VERSION "created by canmatrix"

NS_ :

BS_:

BU_: DiagTool_OBD1 DiwaNXT EBS IRCS MulticII NBM VCM ETS NODE_45 FCCU DICO SGW2 HV_BOX ADCU AEBS DTCO MBMS SGW TPMS ACU CAID2 ELC5_Fr ELC5_Rr PredictiveVirtualNode2 BPU_3 Servo_dir_Turolla PCM NODE_90 NODE_91 NODE_92 RSRRM FCU DSE_VirtualNode2 DSE_VirtualNode40 DSE_VirtualNode38 DSE_VirtualNode49 DSE_VirtualNode48 DSE_VirtualNode39 DSE_VirtualNode37 DSE_VirtualNode36 BSM_B8 BPU_2 DSE_VirtualNode35 DSE_VirtualNode34 RADAR_ACC DSE_VirtualNode33 DSE_VirtualNode41 NODE_BE DSE_VirtualNode32 DSE_VirtualNode4 BSM_C0 BPU_1 DSE_VirtualNode31 DSE_VirtualNode29 DSE_VirtualNode28 MCDS DSE_VirtualNode44 DSE_VirtualNode27 DSE_VirtualNode26 BSM_C8 ALM DSE_VirtualNode25 DSE_VirtualNode50 DSE_VirtualNode47 DSE_VirtualNode46 DSE_VirtualNode23 DSE_VirtualNode51 ScanTool DSE_VirtualNode22 DSE_VirtualNode21 AePTO DC_VirtualNode1 DSE_VirtualNode43 MCSL DSE_VirtualNode1 DSE_VirtualNode42 PredictiveVirtualNode3 DSE_VirtualNode20 DSE_VirtualNode19 DSE_VirtualNode18 DSE_VirtualNode17 DSE_VirtualNode16 DSE_VirtualNode15 NODE_F9 DiagTool DSE_VirtualNode14 DSE_VirtualNode13 DSE_VirtualNode12 DSE_VirtualNode11 DSE_VirtualNode10 DSE_VirtualNode9 DSE_VirtualNode8 DSE_VirtualNode7 DSE_VirtualNode6 Mirror DSE_VirtualNode5 SAS DC_VirtualNode2 PredictiveVirtualNode1 DSE_VirtualNode45 ELFA3 EM_PTO RM CANAIR SWI

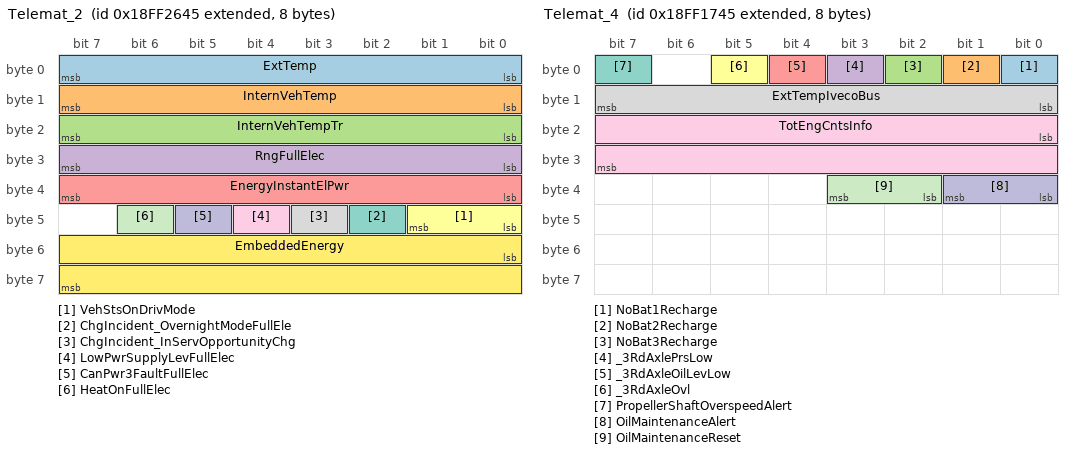
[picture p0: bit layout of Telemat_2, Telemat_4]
BO_ 2566858309 Telemat_2: 8 NODE_45
 SG_ ExtTemp : 0|8@1+ (1,-40) [-40|210] "°C"  PCM
 SG_ InternVehTemp : 8|8@1+ (1,-40) [-40|210] "°C"  PCM
 SG_ InternVehTempTr : 16|8@1+ (1,-40) [-40|210] "°C"  PCM
 SG_ RngFullElec : 24|8@1+ (2,0) [0|500] "km"  PCM
 SG_ EnergyInstantElPwr : 32|8@1+ (2,-250) [-250|250] "kw"  PCM
 SG_ VehStsOnDrivMode : 40|2@1+ (1,0) [0|3] ""  PCM
 SG_ ChgIncident_OvernightModeFullEle : 42|1@1+ (1,0) [0|1] ""  PCM
 SG_ ChgIncident_InServOpportunityChg : 43|1@1+ (1,0) [0|1] ""  PCM
 SG_ LowPwrSupplyLevFullElec : 44|1@1+ (1,0) [0|1] ""  PCM
 SG_ CanPwr3FaultFullElec : 45|1@1+ (1,0) [0|1] ""  PCM
 SG_ HeatOnFullElec : 46|1@1+ (1,0) [0|1] ""  PCM
 SG_ EmbeddedEnergy : 48|16@1+ (1,0) [0|385] "kwh"  PCM

BO_ 2566870597 Telemat_3: 8 NODE_45
 SG_ VehMode : 0|3@1+ (1,0) [0|7] ""  PCM
 SG_ HeatLiquidLowLev : 5|1@1+ (1,0) [0|1] ""  PCM
 SG_ HeatFuelLowLev : 6|1@1+ (1,0) [0|1] ""  PCM
 SG_ HeatSysHighTempFault : 7|1@1+ (1,0) [0|1] ""  PCM
 SG_ ParkBrkSwFullyApplied : 8|1@1+ (1,0) [0|1] ""  PCM
 SG_ FaeSts : 9|2@1+ (1,0) [0|3] ""  PCM
 SG_ FipoSts : 11|2@1+ (1,0) [0|3] ""  PCM
 SG_ EmerBtnSts : 13|1@1+ (1,0) [0|1] ""  PCM
 SG_ Door1EmerInh : 16|1@1+ (1,0) [0|1] ""  PCM
 SG_ Door2EmerInh : 17|1@1+ (1,0) [0|1] ""  PCM
 SG_ Door3EmerInh : 18|1@1+ (1,0) [0|1] ""  PCM
 SG_ Door4EmerInh : 19|1@1+ (1,0) [0|1] ""  PCM
 SG_ Door1ActvInEmerMode : 20|1@1+ (1,0) [0|1] ""  PCM
 SG_ Door2ActvInEmerMode : 21|1@1+ (1,0) [0|1] ""  PCM
 SG_ Door3ActvInEmerMode : 22|1@1+ (1,0) [0|1] ""  PCM
 SG_ Door4ActvInEmerMode : 23|1@1+ (1,0) [0|1] ""  PCM
 SG_ LastDoor1CmdCode : 24|8@1+ (1,0) [0|250] ""  PCM
 SG_ LastDoor2CmdCode : 32|8@1+ (1,0) [0|250] ""  PCM
 SG_ LastDoor3CmdCode : 40|8@1+ (1,0) [0|250] ""  PCM
 SG_ LastDoor4CmdCode : 48|8@1+ (1,0) [0|250] ""  PCM
 SG_ AirDryerSts : 56|1@1+ (1,0) [0|1] ""  PCM
 SG_ OverheatingComprElec : 57|1@1+ (1,0) [0|1] ""  PCM

BO_ 2566854469 Telemat_4: 8 NODE_45
 SG_ NoBat1Recharge : 0|1@1+ (1,0) [0|1] ""  PCM
 SG_ NoBat2Recharge : 1|1@1+ (1,0) [0|1] ""  PCM
 SG_ NoBat3Recharge : 2|1@1+ (1,0) [0|1] ""  PCM
 SG_ _3RdAxlePrsLow : 3|1@1+ (1,0) [0|1] ""  PCM
 SG_ _3RdAxleOilLevLow : 4|1@1+ (1,0) [0|1] ""  PCM
 SG_ _3RdAxleOvl : 5|1@1+ (1,0) [0|1] ""  PCM
 SG_ PropellerShaftOverspeedAlert : 7|1@1+ (1,0) [0|1] ""  PCM
 SG_ ExtTempIvecoBus : 8|8@1+ (1,-40) [-40|210] "°C"  PCM
 SG_ TotEngCntsInfo : 16|16@1+ (100,0) [0|6553500] "Cycles"  PCM
 SG_ OilMaintenanceAlert : 32|2@1+ (1,0) [0|3] ""  PCM
 SG_ OilMaintenanceReset : 34|2@1+ (1,0) [0|3] ""  PCM

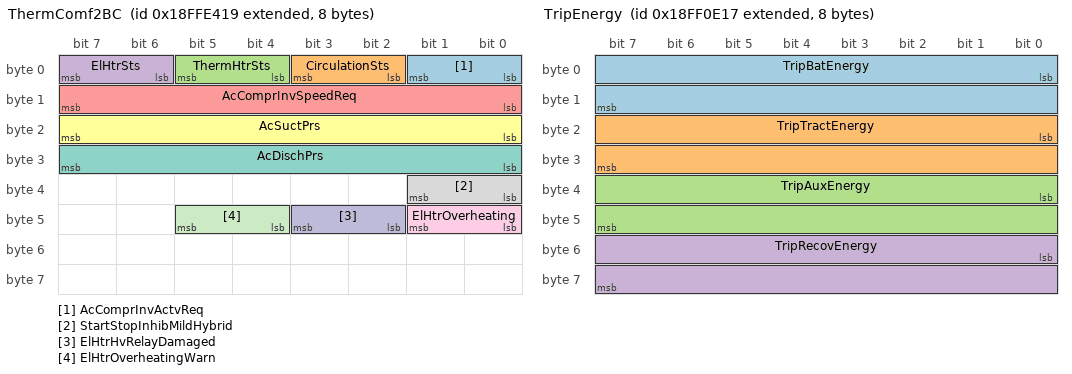
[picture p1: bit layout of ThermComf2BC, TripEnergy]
BO_ 2566906905 ThermComf2BC: 8 CANAIR
 SG_ AcComprInvActvReq : 0|2@1+ (1,0) [0|3] ""  PCM
 SG_ CirculationSts : 2|2@1+ (1,0) [0|3] ""  PCM
 SG_ ThermHtrSts : 4|2@1+ (1,0) [0|3] ""  PCM
 SG_ ElHtrSts : 6|2@1+ (1,0) [0|3] ""  PCM
 SG_ AcComprInvSpeedReq : 8|8@1+ (1,0) [0|250] "Hz"  PCM
 SG_ AcSuctPrs : 16|8@1+ (16,0) [0|4000] "kPa"  PCM
 SG_ AcDischPrs : 24|8@1+ (16,0) [0|4000] "kPa"  PCM
 SG_ StartStopInhibMildHybrid : 32|2@1+ (1,0) [0|3] ""  PCM
 SG_ ElHtrOverheating : 40|2@1+ (1,0) [0|3] ""  PCM
 SG_ ElHtrHvRelayDamaged : 42|2@1+ (1,0) [0|3] ""  PCM
 SG_ ElHtrOverheatingWarn : 44|2@1+ (1,0) [0|3] ""  PCM

BO_ 2566846467 TRF1: 8 DiwaNXT
 SG_ TransmOilTemp1 : 32|16@1+ (0.03125,-273) [-273|1734] "°C"  PCM

BO_ 2566852119 TripEnergy: 8 MulticII
 SG_ TripBatEnergy : 0|16@1+ (1,0) [0|65535] "kWh"  PCM
 SG_ TripTractEnergy : 16|16@1+ (1,0) [0|65535] "kWh"  PCM
 SG_ TripAuxEnergy : 32|16@1+ (1,0) [0|65535] "kWh"  PCM
 SG_ TripRecovEnergy : 48|16@1+ (1,0) [0|65535] "kWh"  PCM

BO_ 2566856261 TripEnergy2: 8 NODE_45
 SG_ TripAcEnergy : 0|16@1+ (1,0) [0|64255] "kWh"  PCM
 SG_ TripNet24VEnergy : 16|16@1+ (1,0) [0|64255] "kWh"  PCM

BO_ 2566749463 TTS: 8 MulticII
 SG_ TtBlkId M : 0|4@1+ (1,0) [0|15] ""  PCM
 SG_ CoolAc m0 : 4|3@1+ (1,0) [0|7] ""  PCM
 SG_ HighBeamMainBeam m0 : 8|3@1+ (1,0) [0|7] ""  PCM
 SG_ LowBeamDipBeam m0 : 12|3@1+ (1,0) [0|7] ""  PCM
 SG_ TurnSigs m0 : 16|3@1+ (1,0) [0|7] ""  PCM
 SG_ HazardWarn m0 : 20|3@1+ (1,0) [0|7] ""  PCM
 SG_ ProvDisOrHandiPers m0 : 24|3@1+ (1,0) [0|7] ""  PCM
 SG_ ParkBrk m0 : 28|3@1+ (1,0) [0|7] ""  PCM
 SG_ BrkFail_BrkSysMalf m0 : 32|3@1+ (1,0) [0|7] ""  PCM
 SG_ HatchOpen m0 : 36|3@1+ (1,0) [0|7] ""  PCM
 SG_ FuelLev m0 : 40|3@1+ (1,0) [0|7] ""  PCM
 SG_ EngCoolTemp_18FD7D17 m0 : 44|3@1+ (1,0) [0|7] ""  PCM
 SG_ BatChgCond m0 : 48|3@1+ (1,0) [0|7] ""  PCM
 SG_ EngOil m0 : 52|3@1+ (1,0) [0|7] ""  PCM
 SG_ PosLightSideLight m0 : 56|3@1+ (1,0) [0|7] ""  PCM
 SG_ FrontFogLight m0 : 60|3@1+ (1,0) [0|7] ""  PCM
 SG_ RearFogLight m1 : 4|3@1+ (1,0) [0|7] ""  PCM
 SG_ ParkHeat m1 : 8|3@1+ (1,0) [0|7] ""  PCM
 SG_ Eng_Mil m1 : 12|3@1+ (1,0) [0|7] ""  PCM
 SG_ ServCallForMaint m1 : 16|3@1+ (1,0) [0|7] ""  PCM
 SG_ TransmFluidTemp m1 : 20|3@1+ (1,0) [0|7] ""  PCM
 SG_ TransmFail_Malf m1 : 24|3@1+ (1,0) [0|7] ""  PCM
 SG_ AntiLckBrkSysFail m1 : 28|3@1+ (1,0) [0|7] ""  PCM
 SG_ WornBrkLin m1 : 32|3@1+ (1,0) [0|7] ""  PCM
 SG_ Windsh_WindshWasherFluid m1 : 36|3@1+ (1,0) [0|7] ""  PCM
 SG_ TireFail_Malf m1 : 40|3@1+ (1,0) [0|7] ""  PCM
 SG_ Malf_GenFail m1 : 44|3@1+ (1,0) [0|7] ""  PCM
 SG_ EngOilTemp m1 : 48|3@1+ (1,0) [0|7] ""  PCM
 SG_ EngOilLev m1 : 52|3@1+ (1,0) [0|7] ""  PCM
 SG_ EngCoolLev m1 : 56|3@1+ (1,0) [0|7] ""  PCM
 SG_ SteerFluidLev m1 : 60|3@1+ (1,0) [0|7] ""  PCM
 SG_ SteerFail m2 : 4|3@1+ (1,0) [0|7] ""  PCM
 SG_ HtCtrl m2 : 8|3@1+ (1,0) [0|7] ""  PCM
 SG_ Ret m2 : 12|3@1+ (1,0) [0|7] ""  PCM
 SG_ EngEmisSysFailMil m2 : 16|3@1+ (1,0) [0|7] ""  PCM
 SG_ EscInd m2 : 20|3@1+ (1,0) [0|7] ""  PCM
 SG_ BrkLight m2 : 24|3@1+ (1,0) [0|7] ""  PCM
 SG_ Artic m2 : 28|3@1+ (1,0) [0|7] ""  PCM
 SG_ StopReq m2 : 32|3@1+ (1,0) [0|7] ""  PCM
 SG_ PramReq m2 : 36|3@1+ (1,0) [0|7] ""  PCM
 SG_ BusStopBrk m2 : 40|3@1+ (1,0) [0|7] ""  PCM
 SG_ AdblueLev m2 : 44|3@1+ (1,0) [0|7] ""  PCM
 SG_ Raising m2 : 48|3@1+ (1,0) [0|7] ""  PCM
 SG_ Low m2 : 52|3@1+ (1,0) [0|7] ""  PCM
 SG_ Kneel m2 : 56|3@1+ (1,0) [0|7] ""  PCM
 SG_ EngCompTemp m2 : 60|3@1+ (1,0) [0|7] ""  PCM
 SG_ AuxAirPrs m3 : 4|3@1+ (1,0) [0|7] ""  PCM
 SG_ AirFiltClog m3 : 8|3@1+ (1,0) [0|7] ""  PCM
 SG_ FuelFiltDiffPrs m3 : 12|3@1+ (1,0) [0|7] ""  PCM
 SG_ SeatBelt m3 : 16|3@1+ (1,0) [0|7] ""  PCM
 SG_ Ebs m3 : 20|3@1+ (1,0) [0|7] ""  PCM
 SG_ LaneDepInd m3 : 24|3@1+ (1,0) [0|7] ""  PCM
 SG_ Aebs m3 : 28|3@1+ (1,0) [0|7] ""  PCM
 SG_ Acc m3 : 32|3@1+ (1,0) [0|7] ""  PCM
 SG_ TrailConn m3 : 36|3@1+ (1,0) [0|7] ""  PCM
 SG_ AbsTrail12 m3 : 40|3@1+ (1,0) [0|7] ""  PCM
 SG_ Airbag m3 : 44|3@1+ (1,0) [0|7] ""  PCM
 SG_ EbsTrail12 m3 : 48|3@1+ (1,0) [0|7] ""  PCM
 SG_ TcoInd m3 : 52|3@1+ (1,0) [0|7] ""  PCM
 SG_ EscSwdOff m3 : 56|3@1+ (1,0) [0|7] ""  PCM
 SG_ LdwSwdOff m3 : 60|3@1+ (1,0) [0|7] ""  PCM
 SG_ EngEmisFilt m4 : 4|3@1+ (1,0) [0|7] ""  PCM
 SG_ ElMotFails m4 : 8|3@1+ (1,0) [0|7] ""  PCM
 SG_ AdblueTamp m4 : 12|3@1+ (1,0) [0|7] ""  PCM
 SG_ MuxSys m4 : 16|3@1+ (1,0) [0|7] ""  PCM
 SG_ BatPak m4 : 20|3@1+ (1,0) [0|7] ""  PCM
 SG_ highVsysCaution m4 : 24|3@1+ (1,0) [0|7] ""  PCM
 SG_ BatPakTemp m4 : 28|3@1+ (1,0) [0|7] ""  PCM
 SG_ LimPerfElMot m4 : 32|3@1+ (1,0) [0|7] ""  PCM
 SG_ BatPakCool m4 : 36|3@1+ (1,0) [0|7] ""  PCM

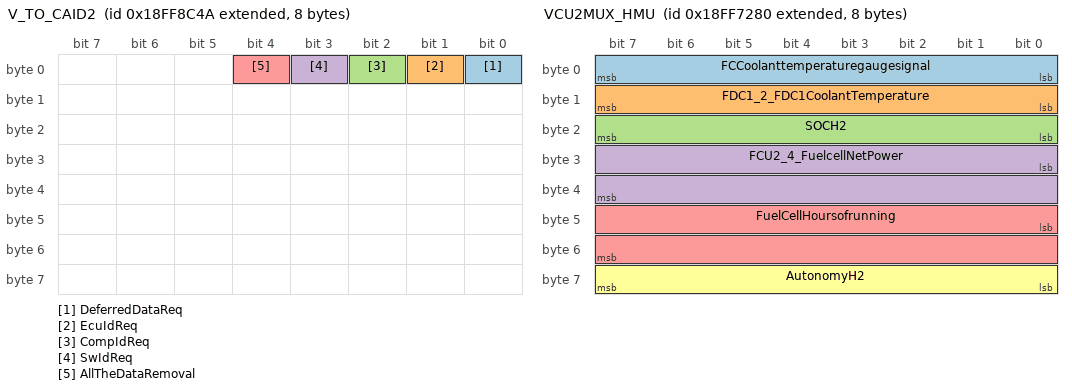
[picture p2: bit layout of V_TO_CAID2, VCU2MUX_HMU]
BO_ 2566884426 V_TO_CAID2: 8 PCM
 SG_ DeferredDataReq : 0|1@1+ (1,0) [0|1] "" Vector__XXX
 SG_ EcuIdReq : 1|1@1+ (1,0) [0|1] "" Vector__XXX
 SG_ CompIdReq : 2|1@1+ (1,0) [0|1] "" Vector__XXX
 SG_ SwIdReq : 3|1@1+ (1,0) [0|1] "" Vector__XXX
 SG_ AllTheDataRemoval : 4|1@1+ (1,0) [0|1] "" Vector__XXX

BO_ 2566877568 VCU2MUX_FC: 8 HV_BOX
 SG_ FCU2_8_H2LeakLamp : 1|2@1+ (1,0) [0|3] ""  PCM
 SG_ FCU2_5_H2FaultLamp : 3|1@1+ (1,0) [0|1] ""  PCM
 SG_ FCU2_HighvoltageInterlockReactRe : 4|1@1+ (1,0) [0|1] ""  PCM
 SG_ FCU2_H2TankValveEmergencyClose : 5|1@1+ (1,0) [0|1] ""  PCM
 SG_ FuelCellSwitchONOFFinputVCU : 6|1@1+ (1,0) [0|1] ""  PCM
 SG_ VCU_FuelcellCoolantLevelLow : 7|1@1+ (1,0) [0|1] ""  PCM
 SG_ FCU2_5_FuelcellStartup : 8|2@1+ (1,0) [0|3] ""  PCM
 SG_ FCU2_5_FuelcellLoadPermmit : 10|1@1+ (1,0) [0|1] ""  PCM
 SG_ FCU2_5_FuelcellShutdown : 11|2@1+ (1,0) [0|3] ""  PCM
 SG_ FCU2_5_FuelcellFault : 13|1@1+ (1,0) [0|1] ""  PCM
 SG_ FCU2_7_FuelcellStopImpossible : 14|2@1+ (1,0) [0|3] ""  PCM
 SG_ FCU2_7_FuelcellStopState : 16|2@1+ (1,0) [0|3] ""  PCM
 SG_ VCU_HighvoltageFaultEmergencyShu : 18|1@1+ (1,0) [0|1] ""  PCM
 SG_ VCU_TankCloseEmergencyShutdownRe : 19|1@1+ (1,0) [0|1] ""  PCM
 SG_ Fcactivationdeactivationstatusfo : 20|2@1+ (1,0) [0|3] ""  PCM
 SG_ H2ConctValExc3Pc_AwlR134 : 22|1@1+ (1,0) [0|1] ""  PCM
 SG_ H2ConctValExc4Pc_RsllR134 : 23|1@1+ (1,0) [0|1] ""  PCM
 SG_ H2sensor1leakagestatus : 24|1@1+ (1,0) [0|1] ""  PCM
 SG_ H2sensor2leakagestatus : 25|1@1+ (1,0) [0|1] ""  PCM
 SG_ H2sensor3leakagestatus : 26|1@1+ (1,0) [0|1] ""  PCM
 SG_ H2sensor4leakagestatus : 27|1@1+ (1,0) [0|1] ""  PCM
 SG_ FuelCellstatusfromSupervisorside : 28|4@1+ (1,0) [0|15] ""  PCM
 SG_ H2Circuitstatus : 32|4@1+ (1,0) [0|15] ""  PCM
 SG_ Limphomemodeoverridemodestatus : 36|1@1+ (1,0) [0|1] ""  PCM
 SG_ H2CircuitFautRSL : 37|1@1+ (1,0) [0|1] ""  PCM
 SG_ H2circuitFaultAWL : 38|1@1+ (1,0) [0|1] ""  PCM
 SG_ HVDCLinkStatus : 39|1@1+ (1,0) [0|1] ""  PCM
 SG_ FCModerequestbytheSupervisor : 40|4@1+ (1,0) [0|15] ""  PCM
 SG_ NumberoftanksopenforH2Readytopro : 44|3@1+ (1,0) [0|7] ""  PCM
 SG_ Fillingauthorizationduetosafetyr : 47|1@1+ (1,0) [0|1] ""  PCM
 SG_ FCU2_8_FuelcellConsumption : 48|16@1+ (0.01,0) [0|655] "mg"  PCM

BO_ 2566877824 VCU2MUX_HMU: 8 HV_BOX
 SG_ FCCoolanttemperaturegaugesignal : 0|8@1+ (1,0) [0|0] ""  PCM
 SG_ FDC1_2_FDC1CoolantTemperature : 8|8@1+ (1,0) [0|0] ""  PCM
 SG_ SOCH2 : 16|8@1+ (1,0) [0|0] ""  PCM
 SG_ FCU2_4_FuelcellNetPower : 24|16@1+ (1,0) [0|0] ""  PCM
 SG_ FuelCellHoursofrunning : 40|16@1+ (1,0) [0|0] ""  PCM
 SG_ AutonomyH2 : 56|8@1+ (1,0) [0|0] ""  PCM

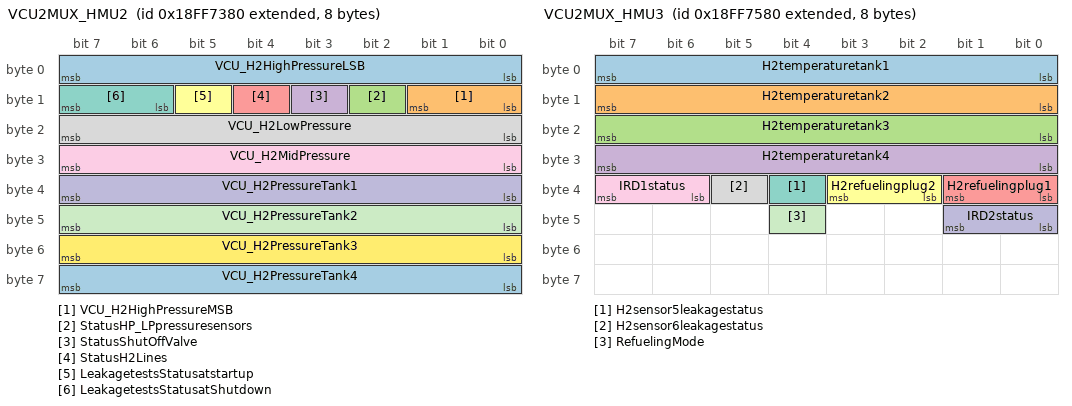
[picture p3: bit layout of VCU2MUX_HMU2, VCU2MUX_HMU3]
BO_ 2566878080 VCU2MUX_HMU2: 8 HV_BOX
 SG_ VCU_H2HighPressureLSB : 0|8@1+ (1,0) [0|0] ""  PCM
 SG_ VCU_H2HighPressureMSB : 8|2@1+ (1,0) [0|0] ""  PCM
 SG_ StatusHP_LPpressuresensors : 10|1@1+ (1,0) [0|0] ""  PCM
 SG_ StatusShutOffValve : 11|1@1+ (1,0) [0|0] ""  PCM
 SG_ StatusH2Lines : 12|1@1+ (1,0) [0|0] ""  PCM
 SG_ LeakagetestsStatusatstartup : 13|1@1+ (1,0) [0|0] ""  PCM
 SG_ LeakagetestsStatusatShutdown : 14|2@1+ (1,0) [0|0] ""  PCM
 SG_ VCU_H2LowPressure : 16|8@1+ (1,0) [0|0] ""  PCM
 SG_ VCU_H2MidPressure : 24|8@1+ (1,0) [0|0] ""  PCM
 SG_ VCU_H2PressureTank1 : 32|8@1+ (1,0) [0|0] ""  PCM
 SG_ VCU_H2PressureTank2 : 40|8@1+ (1,0) [0|0] ""  PCM
 SG_ VCU_H2PressureTank3 : 48|8@1+ (1,0) [0|0] ""  PCM
 SG_ VCU_H2PressureTank4 : 56|8@1+ (1,0) [0|0] ""  PCM

BO_ 2566878592 VCU2MUX_HMU3: 8 HV_BOX
 SG_ H2temperaturetank1 : 0|8@1+ (1,0) [0|0] ""  PCM
 SG_ H2temperaturetank2 : 8|8@1+ (1,0) [0|0] ""  PCM
 SG_ H2temperaturetank3 : 16|8@1+ (1,0) [0|0] ""  PCM
 SG_ H2temperaturetank4 : 24|8@1+ (1,0) [0|0] ""  PCM
 SG_ H2refuelingplug1 : 32|2@1+ (1,0) [0|0] ""  PCM
 SG_ H2refuelingplug2 : 34|2@1+ (1,0) [0|0] ""  PCM
 SG_ H2sensor5leakagestatus : 36|1@1+ (1,0) [0|0] ""  PCM
 SG_ H2sensor6leakagestatus : 37|1@1+ (1,0) [0|0] ""  PCM
 SG_ IRD1status : 38|2@1+ (1,0) [0|0] ""  PCM
 SG_ IRD2status : 40|2@1+ (1,0) [0|0] ""  PCM
 SG_ RefuelingMode : 44|1@1+ (1,0) [0|0] ""  PCM

BO_ 2566803211 VDC1: 8 EBS
 SG_ VdcInfoSig : 0|2@1+ (1,0) [0|3] ""  PCM
 SG_ VdcFullyOp : 2|2@1+ (1,0) [0|3] ""  PCM

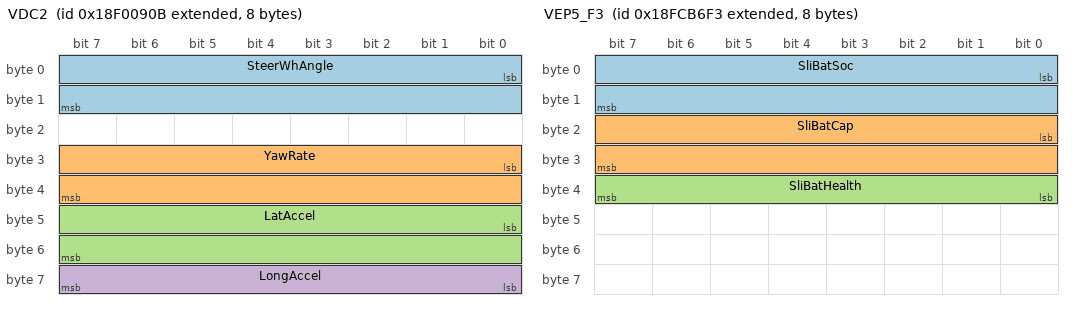
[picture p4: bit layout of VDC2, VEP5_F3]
BO_ 2565867787 VDC2: 8 EBS
 SG_ SteerWhAngle : 0|16@1+ (0.0009765625,-31) [-31|31] "rad"  PCM
 SG_ YawRate : 24|16@1+ (0.0001220703125,-3) [-3|3] "rad/s"  PCM
 SG_ LatAccel : 40|16@1+ (0.00048828125,-15) [-15|15] "m/s²"  PCM
 SG_ LongAccel : 56|8@1+ (0.1,-12) [-12|12] "m/s²"  PCM

BO_ 2566832622 VDHR: 8 DTCO
 SG_ TotVehDistHr : 0|32@1+ (5,0) [0|21055406075] "m"  PCM
 SG_ TripDistHr : 32|32@1+ (5,0) [0|21055406075] "m"  PCM

BO_ 2566846208 VEP1_00: 8 DiagTool_OBD1
 SG_ BatPot_PwrIn1 : 32|16@1+ (0.05,0) [0|3212] "V"  PCM

BO_ 2566846451 VEP1_F3: 8 MBMS
 SG_ BatPot_PwrIn1_18FEF7F3 : 32|16@1+ (0.05,0) [0|3212] "V"  PCM

BO_ 2566804211 VEP3_F3: 8 MBMS
 SG_ SliBat1NetCurHr : 16|16@1+ (0.05,-1600) [-1600|1612] "A"  PCM

BO_ 2566698739 VEP5_F3: 8 MBMS
 SG_ SliBatSoc : 0|16@1+ (0.0025,0) [0|160] "%"  PCM
 SG_ SliBatCap : 16|16@1+ (1,0) [0|64255] "Ah"  PCM
 SG_ SliBatHealth : 32|8@1+ (0.5,0) [0|125] "%"  PCM

BO_ 2566843630 VI_EE: 18 DTCO
 SG_ Vin : 0|8@1+ (1,0) [0|255] "ASCII"  PCM

BO_ 2566845212 VP1_1C: 8 PCM
 SG_ Lat : 0|32@1+ (1E-007,-210) [-210|211] "deg" Vector__XXX
 SG_ Long : 32|32@1+ (1E-007,-210) [-210|211] "deg" Vector__XXX

BO_ 2566842927 VW_2F_Test: 8 ELC5_Fr
 SG_ Axle_Location M : 4|4@1+ (1,0) [0|15] ""  PCM
 SG_ Axle_Weight_1 m0 : 8|16@1+ (0.5,0) [0|32127] "kg"  PCM
 SG_ Axle_Weight_2 m1 : 8|16@1+ (0.5,0) [0|32127] "kg"  PCM
 SG_ Axle_Weight_3 m2 : 8|16@1+ (0.5,0) [0|32127] "kg"  PCM
 SG_ Axle_Weight_4 m3 : 8|16@1+ (0.5,0) [0|32127] "kg"  PCM
 SG_ Axle_Weight_5 m4 : 8|16@1+ (0.5,0) [0|32127] "kg"  PCM

BO_ 2566842944 VW_40_Test: 8 ELC5_Rr
 SG_ Axle_Location_18FEEA40 M : 4|4@1+ (1,0) [0|15] ""  PCM
 SG_ Axle_Weight_1_18FEEA40 m0 : 8|16@1+ (0.5,0) [0|32127] "kg"  PCM
 SG_ Axle_Weight_2_18FEEA40 m1 : 8|16@1+ (0.5,0) [0|32127] "kg"  PCM
 SG_ Axle_Weight_3_18FEEA40 m2 : 8|16@1+ (0.5,0) [0|32127] "kg"  PCM
 SG_ Axle_Weight_4_18FEEA40 m3 : 8|16@1+ (0.5,0) [0|32127] "kg"  PCM
 SG_ Axle_Weight_5_18FEEA40 m4 : 8|16@1+ (0.5,0) [0|32127] "kg"  PCM

BO_ 2566848256 WFI: 8 DiagTool_OBD1
 SG_ WaterInFuelInd1 : 0|2@1+ (1,0) [0|3] ""  PCM

BO_ 2349075360 XBR_A0_0B: 8 AEBS
 SG_ XbrMsgCnt : 56|4@1+ (1,0) [0|15] "count"  PCM,EBS

BO_ 2565472330 RQST_4A_00: 3 PCM
 SG_ PgnRqst_4A_00 : 0|24@1+ (1,0) [0|16777215] ""  DiagTool_OBD1

BO_ 2565482314 RQST_4A_27: 3 PCM
 SG_ PgnRqst_4A_27 : 0|24@1+ (1,0) [0|16777215] ""  VCM

BO_ 2565478218 RQST_4A_17: 3 PCM
 SG_ PgnRqst_4A_17 : 0|24@1+ (1,0) [0|16777215] ""  MulticII

BO_ 2565473098 RQST_4A_03: 3 PCM
 SG_ PgnRqst_4A_03 : 0|24@1+ (1,0) [0|16777215] ""  DiwaNXT

BO_ 2565475146 RQST_4A_0B: 3 PCM
 SG_ PgnRqst_4A_0B : 0|24@1+ (1,0) [0|16777215] ""  EBS

BO_ 2565479754 RQST_4A_1D: 3 PCM
 SG_ PgnRqst_4A_1D : 0|24@1+ (1,0) [0|16777215] ""  SGW

BO_ 2565486666 RQST_4A_38: 3 PCM
 SG_ PgnRqst_4A_38 : 0|24@1+ (1,0) [0|16777215] ""  ETS

BO_ 2565504586 RQST_4A_7E: 3 PCM
 SG_ PgnRqst_4A_7E : 0|24@1+ (1,0) [0|16777215] ""  SGW2

BO_ 2565512778 RQST_4A_9E: 3 PCM
 SG_ PgnRqst_4A_9E : 0|24@1+ (1,0) [0|16777215] ""  ADCU

BO_ 2565513290 RQST_4A_A0: 3 PCM
 SG_ PgnRqst_4A_A0 : 0|24@1+ (1,0) [0|16777215] ""  AEBS

BO_ 2565531466 RQST_4A_E7: 3 PCM
 SG_ PgnRqst_4A_E7 : 0|24@1+ (1,0) [0|16777215] ""  ACU

BO_ 2565480778 RQST_4A_21: 3 PCM
 SG_ PgnRqst_4A_21 : 0|24@1+ (1,0) [0|16777215] ""  NBM

BO_ 2565496394 RQST_4A_5E: 3 PCM
 SG_ PgnRqst_4A_5E : 0|24@1+ (1,0) [0|16777215] ""  CAID2

BO_ 2565495370 RQST_4A_5A: 3 PCM
 SG_ PgnRqst_4A_5A : 0|24@1+ (1,0) [0|16777215] ""  DICO

BO_ 2565484362 RQST_4A_2F: 3 PCM
 SG_ PgnRqst_4A_2F : 0|24@1+ (1,0) [0|16777215] ""  ELC5_Fr

BO_ 2565488714 RQST_4A_40: 3 PCM
 SG_ PgnRqst_4A_40 : 0|24@1+ (1,0) [0|16777215] ""  ELC5_Rr

BO_ 2565535562 RQST_4A_F7: 3 PCM
 SG_ PgnRqst_4A_F7 : 0|24@1+ (1,0) [0|16777215] ""  PredictiveVirtualNode2

BO_ 2565535306 RQST_4A_F6: 3 PCM
 SG_ PgnRqst_4A_F6 : 0|24@1+ (1,0) [0|16777215] ""  BPU_3

BO_ 2565534538 RQST_4A_F3: 3 PCM
 SG_ PgnRqst_4A_F3 : 0|24@1+ (1,0) [0|16777215] ""  MBMS

BO_ 2565491018 RQST_4A_49: 3 PCM
 SG_ PgnRqst_4A_49 : 0|24@1+ (1,0) [0|16777215] ""  FCCU

BO_ 2565476426 RQST_4A_10: 3 PCM
 SG_ PgnRqst_4A_10 : 0|24@1+ (1,0) [0|16777215] ""  IRCS

BO_ 2565484106 RQST_4A_2E: 3 PCM
 SG_ PgnRqst_4A_2E : 0|24@1+ (1,0) [0|16777215] ""  Servo_dir_Turolla

BO_ 2565509194 RQST_4A_90: 3 PCM
 SG_ PgnRqst_4A_90 : 0|24@1+ (1,0) [0|16777215] ""  NODE_90

BO_ 2565509450 RQST_4A_91: 3 PCM
 SG_ PgnRqst_4A_91 : 0|24@1+ (1,0) [0|16777215] ""  NODE_91

BO_ 2565509706 RQST_4A_92: 3 PCM
 SG_ PgnRqst_4A_92 : 0|24@1+ (1,0) [0|16777215] ""  NODE_92

BO_ 2565512266 RQST_4A_9C: 3 PCM
 SG_ PgnRqst_4A_9C : 0|24@1+ (1,0) [0|16777215] ""  RSRRM

BO_ 2565521994 RQST_4A_C2: 3 PCM
 SG_ PgnRqst_4A_C2 : 0|24@1+ (1,0) [0|16777215] ""  FCU

BO_ 2565531722 RQST_4A_E8: 3 PCM
 SG_ PgnRqst_4A_E8 : 0|24@1+ (1,0) [0|16777215] ""  DSE_VirtualNode2

BO_ 2565505098 RQST_4A_80: 3 PCM
 SG_ PgnRqst_4A_80 : 0|24@1+ (1,0) [0|16777215] ""  HV_BOX

BO_ 2565489994 RQST_4A_45: 3 PCM
 SG_ PgnRqst_4A_45 : 0|24@1+ (1,0) [0|16777215] ""  NODE_45

BO_ 2565501514 RQST_4A_72: 3 PCM
 SG_ PgnRqst_4A_72 : 0|24@1+ (1,0) [0|16777215] ""  EM_PTO

BO_ 2565476170 RQST_4A_0F: 3 PCM
 SG_ PgnRqst_4A_0F : 0|24@1+ (1,0) [0|16777215] ""  RM

BO_ 2565533514 RQST_4A_EF: 3 PCM
 SG_ PgnRqst_4A_EF : 0|24@1+ (1,0) [0|16777215] ""  ELFA3

BO_ 2565501258 RQST_4A_71: 3 PCM
 SG_ PgnRqst_4A_71 : 0|24@1+ (1,0) [0|16777215] ""  SWI

BO_ 2565478730 RQST_4A_19: 3 PCM
 SG_ PgnRqst_4A_19 : 0|24@1+ (1,0) [0|16777215] ""  CANAIR

BO_ 2565537610 RQST_4A_FF: 3 PCM
 SG_ PgnRqst_4A_FF : 0|24@1+ (1,0) [0|16777215] "" Vector__XXX

CM_ BO_ 2566858309 "- Full Elec only.";
CM_ SG_ 2566858309 ChgIncident_OvernightModeFullEle "- CUC.C.PCM..3..TELEM: Predisposition. Not yet implemented on MUX software";
CM_ SG_ 2566858309 ChgIncident_InServOpportunityChg "- CUC.C.PCM..3..TELEM: Predisposition. Not yet implemented on MUX software";
CM_ BO_ 2566906905 "- *Not yet confirmed Heat Pump for CW FE. Today is used ECU Clima (like in Thermal engines).
-  [Msg Predisposal]";
CM_ SG_ 2566906905 ThermHtrSts "- Not yet used by the MUX, just for information.";
CM_ BO_ 2566852119 "- Full Elec only. Message FMS14, same ID, moved here.";
CM_ SG_ 2566852119 TripBatEnergy "- SPN/ID requested by responsible system ECU";
CM_ SG_ 2566852119 TripTractEnergy "- SPN/ID requested by responsible system ECU";
CM_ SG_ 2566852119 TripAuxEnergy "- SPN/ID requested by responsible system ECU";
CM_ SG_ 2566852119 TripRecovEnergy "- SPN/ID requested by responsible system ECU";
CM_ BO_ 2566856261 "- Full Elec only / Predisposal";
CM_ BO_ 2566884426 "- The telematics ECU will send 5 requests each 1 second if the CAID doesn’t send the data. After that the telematics ECU will generate an error if the CAID didn’t send the data. At least 2 events must be present in the deferred data in order to consider that it is valid.";
CM_ BO_ 2566803211 "- Optionnal, only if ESP installed";
CM_ SG_ 2566803211 VdcInfoSig "- VDC lamp status";
CM_ BO_ 2565867787 "- Optionnal, only if ESP installed Transmitted only if EoL enable_ebc2==1";
CM_ BO_ 2566832622 "- If without Tacho then Multic S is Tx_ else MulticS is Rx.
- VS2.B.SGW2..23..VDB: Used in freeze frames parameters";
CM_ BO_ 2566846208 "- Note: on MF4 (CNG) applications this message is not present";
CM_ SG_ 2566846208 BatPot_PwrIn1 "- Diesel vehicle only!!!??
-  Min value between both DC DC inverters delivered voltages.";
CM_ SG_ 2566846451 BatPot_PwrIn1_18FEF7F3 "- Available with NBM";
CM_ BO_ 2566843630 "-  2 Message Variant(s): Transm.Rates 10000, OnRequest
-  Cyclic Transmission Rate as result of PGN requests
-  Multipacket message handled by SAE Transport Protocol (J1939/21, par 5.10, Multipacket Broadcast with TP.CM/BAM, TP.DT)
-  Variable Message Length, maximum value used for dbc generation
-  Multipacket message handled by SAE Transport Protocol (J1939/21, par 5.10, Multipacket Broadcast with TP.CM/BAM, TP.DT)
-  Variable Message Length, maximum value used for dbc generation.
- ADC.ZF.ADCU..2";
CM_ SG_ 2566843630 Vin "- 17 bytes followed by an * delimiter
-  Variable signal length, 8 bits used for dbc generation only";
CM_ BO_ 2566842927 "- Only testing";
CM_ BO_ 2566842944 "- Only testing";
CM_ BO_ 2566848256 "- Diesel vehicle only";
CM_ SG_ 2566848256 WaterInFuelInd1 "- 00 No / 01 Yes / 10 Error / 11 Not available";
CM_ BO_ 2349075360 "- Faster Transmission Rate when active and at least once thereafter.
- CUC.C.PCM..3..TELEM: Optional";
BA_DEF_ BO_  "CI_MsgDefinition" STRING ;
BA_DEF_ BO_  "CI_MsgId" INT 0 2147483647;
BA_DEF_ BO_  "CI_MsgName" STRING ;
BA_DEF_ BO_  "GenMsgCycleTime" INT 0 3600000;
BA_DEF_ BO_  "GenMsgCycleTimeFast" INT 0 3600000;
BA_DEF_ BO_  "GenMsgDelayTime" INT 0 3600000;
BA_DEF_ BO_  "GenMsgILSupport" ENUM  "No","Yes";
BA_DEF_ BO_  "GenMsgNrOfRepetition" INT 0 1000000;
BA_DEF_ BO_  "GenMsgRequestable" INT 0 1;
BA_DEF_ BO_  "GenMsgSendType" ENUM  "cyclic","NotUsed","NotUsed","NotUsed","NotUsed","NotUsed","NotUsed","IfActive","noMsgSendType";
BA_DEF_ BO_  "GenMsgStartDelayTime" INT 0 100000;
BA_DEF_ BO_  "J1939PgAppearanceOnBus" ENUM  "Default","CAN_Extended","CANFD_Extended";
BA_DEF_ BO_  "TpJ1939VarDlc" ENUM  "No","Yes";
BA_DEF_ BO_  "VFrameFormat" ENUM  "StandardCAN","ExtendedCAN","reserved","J1939PG";
BA_DEF_ SG_  "CI_ParId" STRING ;
BA_DEF_ SG_  "CI_SigId" INT 0 2147483647;
BA_DEF_ SG_  "CI_SigName" STRING ;
BA_DEF_ SG_  "GenSigEVName" STRING ;
BA_DEF_ SG_  "GenSigILSupport" ENUM  "No","Yes";
BA_DEF_ SG_  "GenSigInactiveValue" INT 0 2147483647;
BA_DEF_ SG_  "GenSigSendType" ENUM  "Cyclic","OnWrite","OnWriteWithRepetition","OnChange","OnChangeWithRepetition","IfActive","IfActiveWithRepetition","NoSigSendType";
BA_DEF_ SG_  "GenSigStartValue" INT 0 2147483647;
BA_DEF_ SG_  "GenSigTimeoutTime_ACU" INT 0 3600000;
BA_DEF_ SG_  "GenSigTimeoutTime_ADCU" INT 0 3600000;
BA_DEF_ SG_  "GenSigTimeoutTime_CAID" INT 0 3600000;
BA_DEF_ SG_  "GenSigTimeoutTime_CANAIR" INT 0 3600000;
BA_DEF_ SG_  "GenSigTimeoutTime_DICO" INT 0 3600000;
BA_DEF_ SG_  "GenSigTimeoutTime_DTCO" INT 0 3600000;
BA_DEF_ SG_  "GenSigTimeoutTime_DiwaNXT" INT 0 3600000;
BA_DEF_ SG_  "GenSigTimeoutTime_DiwaNXT_MH" INT 0 3600000;
BA_DEF_ SG_  "GenSigTimeoutTime_EBS" INT 0 3600000;
BA_DEF_ SG_  "GenSigTimeoutTime_EBS_" INT 0 3600000;
BA_DEF_ SG_  "GenSigTimeoutTime_EBS__" INT 0 3600000;
BA_DEF_ SG_  "GenSigTimeoutTime_EBS___" INT 0 3600000;
BA_DEF_ SG_  "GenSigTimeoutTime_ELC5_Fr" INT 0 3600000;
BA_DEF_ SG_  "GenSigTimeoutTime_ELFA3" INT 0 3600000;
BA_DEF_ SG_  "GenSigTimeoutTime_ETS" INT 0 3600000;
BA_DEF_ SG_  "GenSigTimeoutTime_Ecolife2" INT 0 3600000;
BA_DEF_ SG_  "GenSigTimeoutTime_FCCU_" INT 0 3600000;
BA_DEF_ SG_  "GenSigTimeoutTime_FMS4" INT 0 3600000;
BA_DEF_ SG_  "GenSigTimeoutTime_HV_BOX" INT 0 3600000;
BA_DEF_ SG_  "GenSigTimeoutTime_INTD" INT 0 3600000;
BA_DEF_ SG_  "GenSigTimeoutTime_IRCS" INT 0 3600000;
BA_DEF_ SG_  "GenSigTimeoutTime_MD1_D" INT 0 3600000;
BA_DEF_ SG_  "GenSigTimeoutTime_MD1_G" INT 0 3600000;
BA_DEF_ SG_  "GenSigTimeoutTime_MTCO" INT 0 3600000;
BA_DEF_ SG_  "GenSigTimeoutTime_MulticII" INT 0 3600000;
BA_DEF_ SG_  "GenSigTimeoutTime_MulticS" INT 0 3600000;
BA_DEF_ SG_  "GenSigTimeoutTime_MulticS_" INT 0 3600000;
BA_DEF_ SG_  "GenSigTimeoutTime_MulticS__" INT 0 3600000;
BA_DEF_ SG_  "GenSigTimeoutTime_NBM" INT 0 3600000;
BA_DEF_ SG_  "GenSigTimeoutTime_NBM_" INT 0 3600000;
BA_DEF_ SG_  "GenSigTimeoutTime_NBM__" INT 0 3600000;
BA_DEF_ SG_  "GenSigTimeoutTime_NBM___" INT 0 3600000;
BA_DEF_ SG_  "GenSigTimeoutTime_PCM" INT 0 3600000;
BA_DEF_ SG_  "GenSigTimeoutTime_SGW" INT 0 3600000;
BA_DEF_ SG_  "GenSigTimeoutTime_SGW2" INT 0 3600000;
BA_DEF_ SG_  "GenSigTimeoutTime_SGW_" INT 0 3600000;
BA_DEF_ SG_  "GenSigTimeoutTime_SGW__" INT 0 3600000;
BA_DEF_ SG_  "GenSigTimeoutTime_SIU" INT 0 3600000;
BA_DEF_ SG_  "GenSigTimeoutTime_SmartRadio" INT 0 3600000;
BA_DEF_ SG_  "GenSigTimeoutTime_TPMS" INT 0 3600000;
BA_DEF_ SG_  "GenSigTimeoutTime_TSU" INT 0 3600000;
BA_DEF_ SG_  "GenSigTimeoutTime_VCM" INT 0 3600000;
BA_DEF_ SG_  "GenSigTimeoutTime_VCM_" INT 0 3600000;
BA_DEF_ SG_  "GenSigTimeoutTime_VCM__" INT 0 3600000;
BA_DEF_ SG_  "GenSigTimeoutTime_VCU" INT 0 3600000;
BA_DEF_ SG_  "GenSigTimeoutTime_VCU_" INT 0 3600000;
BA_DEF_ SG_  "GenSigTimeoutTime_VMU" INT 0 3600000;
BA_DEF_ SG_  "SPN" INT 0 524287;
BA_DEF_ SG_  "SigType" ENUM  "Default","Range","RangeSigned","ASCII","Discrete","Control","ReferencePGN","DTC","StringDelimiter","StringLength","StringLengthControl";
BA_DEF_DEF_  "CI_MsgDefinition" "";
BA_DEF_DEF_  "CI_MsgId" 0;
BA_DEF_DEF_  "CI_MsgName" "";
BA_DEF_DEF_  "GenMsgCycleTime" 0;
BA_DEF_DEF_  "GenMsgCycleTimeFast" 0;
BA_DEF_DEF_  "GenMsgDelayTime" 1;
BA_DEF_DEF_  "GenMsgILSupport" "Yes";
BA_DEF_DEF_  "GenMsgNrOfRepetition" 0;
BA_DEF_DEF_  "GenMsgRequestable" 0;
BA_DEF_DEF_  "GenMsgSendType" "noMsgSendType";
BA_DEF_DEF_  "GenMsgStartDelayTime" 0;
BA_DEF_DEF_  "J1939PgAppearanceOnBus" "Default";
BA_DEF_DEF_  "TpJ1939VarDlc" "No";
BA_DEF_DEF_  "VFrameFormat" "J1939PG";
BA_DEF_DEF_  "CI_ParId" "";
BA_DEF_DEF_  "CI_SigId" 0;
BA_DEF_DEF_  "CI_SigName" "";
BA_DEF_DEF_  "GenSigEVName" "Env@Nodename_@Signame";
BA_DEF_DEF_  "GenSigILSupport" "Yes";
BA_DEF_DEF_  "GenSigInactiveValue" 0;
BA_DEF_DEF_  "GenSigSendType" "NoSigSendType";
BA_DEF_DEF_  "GenSigStartValue" 0;
BA_DEF_DEF_  "GenSigTimeoutTime_ACU" 0;
BA_DEF_DEF_  "GenSigTimeoutTime_ADCU" 0;
BA_DEF_DEF_  "GenSigTimeoutTime_CAID" 0;
BA_DEF_DEF_  "GenSigTimeoutTime_CANAIR" 0;
BA_DEF_DEF_  "GenSigTimeoutTime_DICO" 0;
BA_DEF_DEF_  "GenSigTimeoutTime_DTCO" 0;
BA_DEF_DEF_  "GenSigTimeoutTime_DiwaNXT" 0;
BA_DEF_DEF_  "GenSigTimeoutTime_DiwaNXT_MH" 0;
BA_DEF_DEF_  "GenSigTimeoutTime_EBS" 0;
BA_DEF_DEF_  "GenSigTimeoutTime_EBS_" 0;
BA_DEF_DEF_  "GenSigTimeoutTime_EBS__" 0;
BA_DEF_DEF_  "GenSigTimeoutTime_EBS___" 0;
BA_DEF_DEF_  "GenSigTimeoutTime_ELC5_Fr" 0;
BA_DEF_DEF_  "GenSigTimeoutTime_ELFA3" 0;
BA_DEF_DEF_  "GenSigTimeoutTime_ETS" 0;
BA_DEF_DEF_  "GenSigTimeoutTime_Ecolife2" 0;
BA_DEF_DEF_  "GenSigTimeoutTime_FCCU_" 0;
BA_DEF_DEF_  "GenSigTimeoutTime_FMS4" 0;
BA_DEF_DEF_  "GenSigTimeoutTime_HV_BOX" 0;
BA_DEF_DEF_  "GenSigTimeoutTime_INTD" 0;
BA_DEF_DEF_  "GenSigTimeoutTime_IRCS" 0;
BA_DEF_DEF_  "GenSigTimeoutTime_MD1_D" 0;
BA_DEF_DEF_  "GenSigTimeoutTime_MD1_G" 0;
BA_DEF_DEF_  "GenSigTimeoutTime_MTCO" 0;
BA_DEF_DEF_  "GenSigTimeoutTime_MulticII" 0;
BA_DEF_DEF_  "GenSigTimeoutTime_MulticS" 0;
BA_DEF_DEF_  "GenSigTimeoutTime_MulticS_" 0;
BA_DEF_DEF_  "GenSigTimeoutTime_MulticS__" 0;
BA_DEF_DEF_  "GenSigTimeoutTime_NBM" 0;
BA_DEF_DEF_  "GenSigTimeoutTime_NBM_" 0;
BA_DEF_DEF_  "GenSigTimeoutTime_NBM__" 0;
BA_DEF_DEF_  "GenSigTimeoutTime_NBM___" 0;
BA_DEF_DEF_  "GenSigTimeoutTime_PCM" 0;
BA_DEF_DEF_  "GenSigTimeoutTime_SGW" 0;
BA_DEF_DEF_  "GenSigTimeoutTime_SGW2" 0;
BA_DEF_DEF_  "GenSigTimeoutTime_SGW_" 0;
BA_DEF_DEF_  "GenSigTimeoutTime_SGW__" 0;
BA_DEF_DEF_  "GenSigTimeoutTime_SIU" 0;
BA_DEF_DEF_  "GenSigTimeoutTime_SmartRadio" 0;
BA_DEF_DEF_  "GenSigTimeoutTime_TPMS" 0;
BA_DEF_DEF_  "GenSigTimeoutTime_TSU" 0;
BA_DEF_DEF_  "GenSigTimeoutTime_VCM" 0;
BA_DEF_DEF_  "GenSigTimeoutTime_VCM_" 0;
BA_DEF_DEF_  "GenSigTimeoutTime_VCM__" 0;
BA_DEF_DEF_  "GenSigTimeoutTime_VCU" 0;
BA_DEF_DEF_  "GenSigTimeoutTime_VCU_" 0;
BA_DEF_DEF_  "GenSigTimeoutTime_VMU" 0;
BA_DEF_DEF_  "SPN" 0;
BA_DEF_DEF_  "SigType" "Default";
BA_ "CI_MsgDefinition" BO_ 2566858309 "Wabco Proprietary";
BA_ "CI_MsgId" BO_ 2566858309 1847;
BA_ "CI_MsgName" BO_ 2566858309 "Telemat_2 - Telemat message 2";
BA_ "GenMsgCycleTime" BO_ 2566858309 1000;
BA_ "GenMsgCycleTimeFast" BO_ 2566858309 1000;
BA_ "GenMsgDelayTime" BO_ 2566858309 500;
BA_ "GenMsgSendType" BO_ 2566858309 0;
BA_ "GenMsgStartDelayTime" BO_ 2566858309 78;
BA_ "VFrameFormat" BO_ 2566858309 1;
BA_ "CI_MsgDefinition" BO_ 2566870597 "Iveco Bus Proprietary";
BA_ "CI_MsgId" BO_ 2566870597 1860;
BA_ "CI_MsgName" BO_ 2566870597 "Telemat_3 - Telemat message 3";
BA_ "GenMsgCycleTime" BO_ 2566870597 1000;
BA_ "GenMsgCycleTimeFast" BO_ 2566870597 1000;
BA_ "GenMsgDelayTime" BO_ 2566870597 500;
BA_ "GenMsgSendType" BO_ 2566870597 0;
BA_ "GenMsgStartDelayTime" BO_ 2566870597 82;
BA_ "CI_MsgDefinition" BO_ 2566854469 "Iveco Bus Proprietary";
BA_ "CI_MsgId" BO_ 2566854469 1885;
BA_ "CI_MsgName" BO_ 2566854469 "Telemat_4 - Telemat message 4";
BA_ "GenMsgCycleTime" BO_ 2566854469 1000;
BA_ "GenMsgCycleTimeFast" BO_ 2566854469 1000;
BA_ "GenMsgDelayTime" BO_ 2566854469 500;
BA_ "GenMsgSendType" BO_ 2566854469 0;
BA_ "GenMsgStartDelayTime" BO_ 2566854469 73;
BA_ "CI_MsgDefinition" BO_ 2566906905 "Iveco Proprietary";
BA_ "CI_MsgId" BO_ 2566906905 10923;
BA_ "CI_MsgName" BO_ 2566906905 "ThermComf2BC - Thermal Comfort To Body Controller";
BA_ "GenMsgCycleTime" BO_ 2566906905 1000;
BA_ "GenMsgCycleTimeFast" BO_ 2566906905 1000;
BA_ "GenMsgDelayTime" BO_ 2566906905 500;
BA_ "GenMsgSendType" BO_ 2566906905 0;
BA_ "CI_MsgDefinition" BO_ 2566846467 "J1939DA";
BA_ "CI_MsgId" BO_ 2566846467 630;
BA_ "CI_MsgName" BO_ 2566846467 "TRF1 - Transmission Fluids 1";
BA_ "GenMsgCycleTime" BO_ 2566846467 1000;
BA_ "GenMsgCycleTimeFast" BO_ 2566846467 1000;
BA_ "GenMsgDelayTime" BO_ 2566846467 500;
BA_ "GenMsgSendType" BO_ 2566846467 0;
BA_ "GenMsgStartDelayTime" BO_ 2566846467 35;
BA_ "CI_MsgDefinition" BO_ 2566852119 "Iveco Proprietary";
BA_ "CI_MsgId" BO_ 2566852119 1901;
BA_ "CI_MsgName" BO_ 2566852119 "TripEnergy - Trip Energy";
BA_ "GenMsgCycleTime" BO_ 2566852119 1000;
BA_ "GenMsgCycleTimeFast" BO_ 2566852119 1000;
BA_ "GenMsgDelayTime" BO_ 2566852119 500;
BA_ "GenMsgSendType" BO_ 2566852119 0;
BA_ "GenMsgStartDelayTime" BO_ 2566852119 75;
BA_ "CI_MsgDefinition" BO_ 2566856261 "Iveco Bus Proprietary";
BA_ "CI_MsgId" BO_ 2566856261 1923;
BA_ "CI_MsgName" BO_ 2566856261 "TripEnergy2 - Trip Energy2 (Old Telematic_10)";
BA_ "GenMsgCycleTime" BO_ 2566856261 1000;
BA_ "GenMsgCycleTimeFast" BO_ 2566856261 1000;
BA_ "GenMsgDelayTime" BO_ 2566856261 500;
BA_ "GenMsgSendType" BO_ 2566856261 0;
BA_ "GenMsgStartDelayTime" BO_ 2566856261 77;
BA_ "CI_MsgDefinition" BO_ 2566749463 "FMS";
BA_ "CI_MsgId" BO_ 2566749463 3201;
BA_ "CI_MsgName" BO_ 2566749463 "TTS - Telltale Status FMS1";
BA_ "GenMsgCycleTime" BO_ 2566749463 1000;
BA_ "GenMsgCycleTimeFast" BO_ 2566749463 1000;
BA_ "GenMsgDelayTime" BO_ 2566749463 100;
BA_ "GenMsgSendType" BO_ 2566749463 0;
BA_ "GenMsgStartDelayTime" BO_ 2566749463 53;
BA_ "CI_MsgDefinition" BO_ 2566884426 "Iveco Proprietary";
BA_ "CI_MsgId" BO_ 2566884426 1328;
BA_ "CI_MsgName" BO_ 2566884426 "V_TO_CAID2 - Proprietary B - Vehicle to CAID2 message ";
BA_ "GenMsgCycleTime" BO_ 2566884426 1000;
BA_ "GenMsgCycleTimeFast" BO_ 2566884426 1000;
BA_ "GenMsgDelayTime" BO_ 2566884426 500;
BA_ "GenMsgSendType" BO_ 2566884426 0;
BA_ "GenMsgStartDelayTime" BO_ 2566884426 162;
BA_ "CI_MsgDefinition" BO_ 2566877568 "Iveco Bus Proprietary";
BA_ "CI_MsgId" BO_ 2566877568 18903;
BA_ "CI_MsgName" BO_ 2566877568 "VCU2MUX_FC - VCU2MUX_FuelCell";
BA_ "GenMsgCycleTime" BO_ 2566877568 100;
BA_ "GenMsgCycleTimeFast" BO_ 2566877568 100;
BA_ "GenMsgDelayTime" BO_ 2566877568 50;
BA_ "GenMsgSendType" BO_ 2566877568 0;
BA_ "GenMsgStartDelayTime" BO_ 2566877568 22;
BA_ "CI_MsgDefinition" BO_ 2566877824 "Iveco Bus Proprietary";
BA_ "CI_MsgId" BO_ 2566877824 18936;
BA_ "CI_MsgName" BO_ 2566877824 "VCU2MUX_HMU - VCU2MUX_HMU";
BA_ "GenMsgCycleTime" BO_ 2566877824 1000;
BA_ "GenMsgCycleTimeFast" BO_ 2566877824 1000;
BA_ "GenMsgDelayTime" BO_ 2566877824 500;
BA_ "GenMsgSendType" BO_ 2566877824 0;
BA_ "GenMsgStartDelayTime" BO_ 2566877824 43;
BA_ "CI_MsgDefinition" BO_ 2566878080 "Iveco Bus Proprietary";
BA_ "CI_MsgId" BO_ 2566878080 18943;
BA_ "CI_MsgName" BO_ 2566878080 "VCU2MUX_HMU#2 - VCU2MUX_HMU#2";
BA_ "GenMsgCycleTime" BO_ 2566878080 1000;
BA_ "GenMsgCycleTimeFast" BO_ 2566878080 1000;
BA_ "GenMsgDelayTime" BO_ 2566878080 500;
BA_ "GenMsgSendType" BO_ 2566878080 0;
BA_ "GenMsgStartDelayTime" BO_ 2566878080 44;
BA_ "CI_MsgDefinition" BO_ 2566878592 "Iveco Bus Proprietary";
BA_ "CI_MsgId" BO_ 2566878592 18963;
BA_ "CI_MsgName" BO_ 2566878592 "VCU2MUX_HMU#3 - VCU2MUX_HMU#3";
BA_ "GenMsgCycleTime" BO_ 2566878592 1000;
BA_ "GenMsgCycleTimeFast" BO_ 2566878592 1000;
BA_ "GenMsgDelayTime" BO_ 2566878592 500;
BA_ "GenMsgSendType" BO_ 2566878592 0;
BA_ "GenMsgStartDelayTime" BO_ 2566878592 45;
BA_ "CI_MsgDefinition" BO_ 2566803211 "J1939DA";
BA_ "CI_MsgId" BO_ 2566803211 345;
BA_ "CI_MsgName" BO_ 2566803211 "VDC1 - Vehicle Dynamic Stability Control 1";
BA_ "GenMsgCycleTime" BO_ 2566803211 100;
BA_ "GenMsgCycleTimeFast" BO_ 2566803211 100;
BA_ "GenMsgDelayTime" BO_ 2566803211 50;
BA_ "GenMsgSendType" BO_ 2566803211 0;
BA_ "GenMsgStartDelayTime" BO_ 2566803211 29;
BA_ "CI_MsgDefinition" BO_ 2565867787 "J1939DA";
BA_ "CI_MsgId" BO_ 2565867787 354;
BA_ "CI_MsgName" BO_ 2565867787 "VDC2 - Vehicle Dynamic Stability Control 2";
BA_ "GenMsgCycleTime" BO_ 2565867787 20;
BA_ "GenMsgCycleTimeFast" BO_ 2565867787 20;
BA_ "GenMsgDelayTime" BO_ 2565867787 10;
BA_ "GenMsgSendType" BO_ 2565867787 0;
BA_ "GenMsgStartDelayTime" BO_ 2565867787 6;
BA_ "CI_MsgDefinition" BO_ 2566832622 "J1939DA";
BA_ "CI_MsgId" BO_ 2566832622 673;
BA_ "CI_MsgName" BO_ 2566832622 "VDHR - High Resolution Vehicle Distance";
BA_ "GenMsgCycleTime" BO_ 2566832622 1000;
BA_ "GenMsgCycleTimeFast" BO_ 2566832622 1000;
BA_ "GenMsgDelayTime" BO_ 2566832622 500;
BA_ "GenMsgSendType" BO_ 2566832622 0;
BA_ "GenMsgStartDelayTime" BO_ 2566832622 10;
BA_ "CI_MsgDefinition" BO_ 2566846208 "J1939DA";
BA_ "CI_MsgId" BO_ 2566846208 2205;
BA_ "CI_MsgName" BO_ 2566846208 "VEP1_00 - Vehicle Electrical Power 1";
BA_ "GenMsgCycleTime" BO_ 2566846208 1000;
BA_ "GenMsgCycleTimeFast" BO_ 2566846208 1000;
BA_ "GenMsgDelayTime" BO_ 2566846208 500;
BA_ "GenMsgSendType" BO_ 2566846208 0;
BA_ "GenMsgStartDelayTime" BO_ 2566846208 42;
BA_ "CI_MsgDefinition" BO_ 2566846451 "J1939DA";
BA_ "CI_MsgId" BO_ 2566846451 2211;
BA_ "CI_MsgName" BO_ 2566846451 "VEP1_F3 - Vehicle Electrical Power 1";
BA_ "GenMsgCycleTime" BO_ 2566846451 100;
BA_ "GenMsgCycleTimeFast" BO_ 2566846451 100;
BA_ "GenMsgDelayTime" BO_ 2566846451 100;
BA_ "GenMsgSendType" BO_ 2566846451 0;
BA_ "GenMsgStartDelayTime" BO_ 2566846451 36;
BA_ "CI_MsgDefinition" BO_ 2566804211 "J1939DA";
BA_ "CI_MsgId" BO_ 2566804211 2217;
BA_ "CI_MsgName" BO_ 2566804211 "VEP3_F3 - Vehicle Electrical Power 3";
BA_ "GenMsgCycleTime" BO_ 2566804211 100;
BA_ "GenMsgCycleTimeFast" BO_ 2566804211 100;
BA_ "GenMsgDelayTime" BO_ 2566804211 100;
BA_ "GenMsgSendType" BO_ 2566804211 0;
BA_ "GenMsgStartDelayTime" BO_ 2566804211 22;
BA_ "CI_MsgDefinition" BO_ 2566698739 "J1939DA";
BA_ "CI_MsgId" BO_ 2566698739 2586;
BA_ "CI_MsgName" BO_ 2566698739 "VEP5_F3 - Vehicle Electrical Power 5";
BA_ "GenMsgCycleTime" BO_ 2566698739 1000;
BA_ "GenMsgCycleTimeFast" BO_ 2566698739 1000;
BA_ "GenMsgDelayTime" BO_ 2566698739 500;
BA_ "GenMsgSendType" BO_ 2566698739 0;
BA_ "GenMsgStartDelayTime" BO_ 2566698739 49;
BA_ "CI_MsgDefinition" BO_ 2566843630 "J1939DA";
BA_ "CI_MsgId" BO_ 2566843630 743;
BA_ "CI_MsgName" BO_ 2566843630 "VI_EE - Vehicle Identification";
BA_ "GenMsgCycleTime" BO_ 2566843630 10000;
BA_ "GenMsgCycleTimeFast" BO_ 2566843630 10000;
BA_ "GenMsgDelayTime" BO_ 2566843630 5000;
BA_ "GenMsgSendType" BO_ 2566843630 0;
BA_ "GenMsgStartDelayTime" BO_ 2566843630 28;
BA_ "CI_MsgDefinition" BO_ 2566845212 "J1939DA";
BA_ "CI_MsgId" BO_ 2566845212 3460;
BA_ "CI_MsgName" BO_ 2566845212 "VP1_1C - Vehicle Position 1";
BA_ "GenMsgCycleTime" BO_ 2566845212 1000;
BA_ "GenMsgCycleTimeFast" BO_ 2566845212 1000;
BA_ "GenMsgDelayTime" BO_ 2566845212 500;
BA_ "GenMsgSendType" BO_ 2566845212 0;
BA_ "GenMsgStartDelayTime" BO_ 2566845212 158;
BA_ "CI_MsgDefinition" BO_ 2566842927 "J1939DA";
BA_ "CI_MsgId" BO_ 2566842927 17507;
BA_ "CI_MsgName" BO_ 2566842927 "VW_2F - Vehicle Weight";
BA_ "GenMsgCycleTime" BO_ 2566842927 1000;
BA_ "GenMsgCycleTimeFast" BO_ 2566842927 1000;
BA_ "GenMsgDelayTime" BO_ 2566842927 500;
BA_ "GenMsgSendType" BO_ 2566842927 0;
BA_ "GenMsgStartDelayTime" BO_ 2566842927 10;
BA_ "CI_MsgDefinition" BO_ 2566842944 "J1939DA";
BA_ "CI_MsgId" BO_ 2566842944 17514;
BA_ "CI_MsgName" BO_ 2566842944 "VW_40 - Vehicle Weight";
BA_ "GenMsgCycleTime" BO_ 2566842944 1000;
BA_ "GenMsgCycleTimeFast" BO_ 2566842944 1000;
BA_ "GenMsgDelayTime" BO_ 2566842944 500;
BA_ "GenMsgSendType" BO_ 2566842944 0;
BA_ "GenMsgStartDelayTime" BO_ 2566842944 8;
BA_ "CI_MsgDefinition" BO_ 2566848256 "J1939DA";
BA_ "CI_MsgId" BO_ 2566848256 1616;
BA_ "CI_MsgName" BO_ 2566848256 "WFI - Water in Fuel Indicator";
BA_ "GenMsgCycleTime" BO_ 2566848256 1000;
BA_ "GenMsgCycleTimeFast" BO_ 2566848256 1000;
BA_ "GenMsgDelayTime" BO_ 2566848256 100;
BA_ "GenMsgSendType" BO_ 2566848256 0;
BA_ "GenMsgStartDelayTime" BO_ 2566848256 52;
BA_ "CI_MsgDefinition" BO_ 2349075360 "J1939 p2p";
BA_ "CI_MsgId" BO_ 2349075360 336;
BA_ "CI_MsgName" BO_ 2349075360 "XBR_A0_0B - External Brake Request";
BA_ "GenMsgCycleTime" BO_ 2349075360 200;
BA_ "GenMsgCycleTimeFast" BO_ 2349075360 20;
BA_ "GenMsgDelayTime" BO_ 2349075360 10;
BA_ "GenMsgNrOfRepetition" BO_ 2349075360 4;
BA_ "GenMsgSendType" BO_ 2349075360 0;
BA_ "CI_MsgDefinition" BO_ 2565472330 "J1939-21";
BA_ "CI_MsgId" BO_ 2565472330 100000;
BA_ "CI_MsgName" BO_ 2565472330 "RQST_4A_00 - Request";
BA_ "CI_MsgDefinition" BO_ 2565482314 "J1939-21";
BA_ "CI_MsgId" BO_ 2565482314 100002;
BA_ "CI_MsgName" BO_ 2565482314 "RQST_4A_27 - Request";
BA_ "CI_MsgDefinition" BO_ 2565478218 "J1939-21";
BA_ "CI_MsgId" BO_ 2565478218 100004;
BA_ "CI_MsgName" BO_ 2565478218 "RQST_4A_17 - Request";
BA_ "CI_MsgDefinition" BO_ 2565473098 "J1939-21";
BA_ "CI_MsgId" BO_ 2565473098 100006;
BA_ "CI_MsgName" BO_ 2565473098 "RQST_4A_03 - Request";
BA_ "CI_MsgDefinition" BO_ 2565475146 "J1939-21";
BA_ "CI_MsgId" BO_ 2565475146 100008;
BA_ "CI_MsgName" BO_ 2565475146 "RQST_4A_0B - Request";
BA_ "CI_MsgDefinition" BO_ 2565479754 "J1939-21";
BA_ "CI_MsgId" BO_ 2565479754 100010;
BA_ "CI_MsgName" BO_ 2565479754 "RQST_4A_1D - Request";
BA_ "CI_MsgDefinition" BO_ 2565486666 "J1939-21";
BA_ "CI_MsgId" BO_ 2565486666 100012;
BA_ "CI_MsgName" BO_ 2565486666 "RQST_4A_38 - Request";
BA_ "CI_MsgDefinition" BO_ 2565504586 "J1939-21";
BA_ "CI_MsgId" BO_ 2565504586 100014;
BA_ "CI_MsgName" BO_ 2565504586 "RQST_4A_7E - Request";
BA_ "CI_MsgDefinition" BO_ 2565512778 "J1939-21";
BA_ "CI_MsgId" BO_ 2565512778 100016;
BA_ "CI_MsgName" BO_ 2565512778 "RQST_4A_9E - Request";
BA_ "CI_MsgDefinition" BO_ 2565513290 "J1939-21";
BA_ "CI_MsgId" BO_ 2565513290 100018;
BA_ "CI_MsgName" BO_ 2565513290 "RQST_4A_A0 - Request";
BA_ "CI_MsgDefinition" BO_ 2565531466 "J1939-21";
BA_ "CI_MsgId" BO_ 2565531466 100020;
BA_ "CI_MsgName" BO_ 2565531466 "RQST_4A_E7 - Request";
BA_ "CI_MsgDefinition" BO_ 2565480778 "J1939-21";
BA_ "CI_MsgId" BO_ 2565480778 100022;
BA_ "CI_MsgName" BO_ 2565480778 "RQST_4A_21 - Request";
BA_ "CI_MsgDefinition" BO_ 2565496394 "J1939-21";
BA_ "CI_MsgId" BO_ 2565496394 100024;
BA_ "CI_MsgName" BO_ 2565496394 "RQST_4A_5E - Request";
BA_ "CI_MsgDefinition" BO_ 2565495370 "J1939-21";
BA_ "CI_MsgId" BO_ 2565495370 100026;
BA_ "CI_MsgName" BO_ 2565495370 "RQST_4A_5A - Request";
BA_ "CI_MsgDefinition" BO_ 2565484362 "J1939-21";
BA_ "CI_MsgId" BO_ 2565484362 100028;
BA_ "CI_MsgName" BO_ 2565484362 "RQST_4A_2F - Request";
BA_ "CI_MsgDefinition" BO_ 2565488714 "J1939-21";
BA_ "CI_MsgId" BO_ 2565488714 100030;
BA_ "CI_MsgName" BO_ 2565488714 "RQST_4A_40 - Request";
BA_ "CI_MsgDefinition" BO_ 2565535562 "J1939-21";
BA_ "CI_MsgId" BO_ 2565535562 100032;
BA_ "CI_MsgName" BO_ 2565535562 "RQST_4A_F7 - Request";
BA_ "CI_MsgDefinition" BO_ 2565535306 "J1939-21";
BA_ "CI_MsgId" BO_ 2565535306 100034;
BA_ "CI_MsgName" BO_ 2565535306 "RQST_4A_F6 - Request";
BA_ "CI_MsgDefinition" BO_ 2565534538 "J1939-21";
BA_ "CI_MsgId" BO_ 2565534538 100036;
BA_ "CI_MsgName" BO_ 2565534538 "RQST_4A_F3 - Request";
BA_ "CI_MsgDefinition" BO_ 2565491018 "J1939-21";
BA_ "CI_MsgId" BO_ 2565491018 100038;
BA_ "CI_MsgName" BO_ 2565491018 "RQST_4A_49 - Request";
BA_ "CI_MsgDefinition" BO_ 2565476426 "J1939-21";
BA_ "CI_MsgId" BO_ 2565476426 100040;
BA_ "CI_MsgName" BO_ 2565476426 "RQST_4A_10 - Request";
BA_ "CI_MsgDefinition" BO_ 2565484106 "J1939-21";
BA_ "CI_MsgId" BO_ 2565484106 100042;
BA_ "CI_MsgName" BO_ 2565484106 "RQST_4A_2E - Request";
BA_ "CI_MsgDefinition" BO_ 2565509194 "J1939-21";
BA_ "CI_MsgId" BO_ 2565509194 100044;
BA_ "CI_MsgName" BO_ 2565509194 "RQST_4A_90 - Request";
BA_ "CI_MsgDefinition" BO_ 2565509450 "J1939-21";
BA_ "CI_MsgId" BO_ 2565509450 100046;
BA_ "CI_MsgName" BO_ 2565509450 "RQST_4A_91 - Request";
BA_ "CI_MsgDefinition" BO_ 2565509706 "J1939-21";
BA_ "CI_MsgId" BO_ 2565509706 100048;
BA_ "CI_MsgName" BO_ 2565509706 "RQST_4A_92 - Request";
BA_ "CI_MsgDefinition" BO_ 2565512266 "J1939-21";
BA_ "CI_MsgId" BO_ 2565512266 100050;
BA_ "CI_MsgName" BO_ 2565512266 "RQST_4A_9C - Request";
BA_ "CI_MsgDefinition" BO_ 2565521994 "J1939-21";
BA_ "CI_MsgId" BO_ 2565521994 100052;
BA_ "CI_MsgName" BO_ 2565521994 "RQST_4A_C2 - Request";
BA_ "CI_MsgDefinition" BO_ 2565531722 "J1939-21";
BA_ "CI_MsgId" BO_ 2565531722 100054;
BA_ "CI_MsgName" BO_ 2565531722 "RQST_4A_E8 - Request";
BA_ "CI_MsgDefinition" BO_ 2565505098 "J1939-21";
BA_ "CI_MsgId" BO_ 2565505098 100056;
BA_ "CI_MsgName" BO_ 2565505098 "RQST_4A_80 - Request";
BA_ "CI_MsgDefinition" BO_ 2565489994 "J1939-21";
BA_ "CI_MsgId" BO_ 2565489994 100058;
BA_ "CI_MsgName" BO_ 2565489994 "RQST_4A_45 - Request";
BA_ "CI_MsgDefinition" BO_ 2565501514 "J1939-21";
BA_ "CI_MsgId" BO_ 2565501514 100060;
BA_ "CI_MsgName" BO_ 2565501514 "RQST_4A_72 - Request";
BA_ "CI_MsgDefinition" BO_ 2565476170 "J1939-21";
BA_ "CI_MsgId" BO_ 2565476170 100062;
BA_ "CI_MsgName" BO_ 2565476170 "RQST_4A_0F - Request";
BA_ "CI_MsgDefinition" BO_ 2565533514 "J1939-21";
BA_ "CI_MsgId" BO_ 2565533514 100064;
BA_ "CI_MsgName" BO_ 2565533514 "RQST_4A_EF - Request";
BA_ "CI_MsgDefinition" BO_ 2565501258 "J1939-21";
BA_ "CI_MsgId" BO_ 2565501258 100066;
BA_ "CI_MsgName" BO_ 2565501258 "RQST_4A_71 - Request";
BA_ "CI_MsgDefinition" BO_ 2565478730 "J1939-21";
BA_ "CI_MsgId" BO_ 2565478730 100068;
BA_ "CI_MsgName" BO_ 2565478730 "RQST_4A_19 - Request";
BA_ "CI_MsgDefinition" BO_ 2565537610 "J1939-21";
BA_ "CI_MsgId" BO_ 2565537610 100070;
BA_ "CI_MsgName" BO_ 2565537610 "RQST_4A_FF - Request";
BA_ "CI_ParId" SG_ 2566858309 ExtTemp "IB741";
BA_ "CI_SigId" SG_ 2566858309 ExtTemp 1848;
BA_ "CI_SigName" SG_ 2566858309 ExtTemp "External temperature";
BA_ "GenSigTimeoutTime_PCM" SG_ 2566858309 ExtTemp 5000;
BA_ "GenSigTimeoutTime_SGW__" SG_ 2566858309 ExtTemp 5000;
BA_ "SigType" SG_ 2566858309 ExtTemp 1;
BA_ "CI_ParId" SG_ 2566858309 InternVehTemp "IB742";
BA_ "CI_SigId" SG_ 2566858309 InternVehTemp 1849;
BA_ "CI_SigName" SG_ 2566858309 InternVehTemp "Internal vehicle temperature";
BA_ "GenSigTimeoutTime_PCM" SG_ 2566858309 InternVehTemp 5000;
BA_ "GenSigTimeoutTime_SGW__" SG_ 2566858309 InternVehTemp 5000;
BA_ "SigType" SG_ 2566858309 InternVehTemp 1;
BA_ "CI_ParId" SG_ 2566858309 InternVehTempTr "IB743";
BA_ "CI_SigId" SG_ 2566858309 InternVehTempTr 1850;
BA_ "CI_SigName" SG_ 2566858309 InternVehTempTr "Internal vehicle temperature (trailer)";
BA_ "GenSigTimeoutTime_PCM" SG_ 2566858309 InternVehTempTr 5000;
BA_ "GenSigTimeoutTime_SGW__" SG_ 2566858309 InternVehTempTr 5000;
BA_ "SigType" SG_ 2566858309 InternVehTempTr 1;
BA_ "CI_ParId" SG_ 2566858309 RngFullElec "IB744";
BA_ "CI_SigId" SG_ 2566858309 RngFullElec 1851;
BA_ "CI_SigName" SG_ 2566858309 RngFullElec "Range -  Full Elec";
BA_ "GenSigTimeoutTime_PCM" SG_ 2566858309 RngFullElec 5000;
BA_ "GenSigTimeoutTime_SGW__" SG_ 2566858309 RngFullElec 5000;
BA_ "SigType" SG_ 2566858309 RngFullElec 1;
BA_ "CI_ParId" SG_ 2566858309 EnergyInstantElPwr "IB745";
BA_ "CI_SigId" SG_ 2566858309 EnergyInstantElPwr 1852;
BA_ "CI_SigName" SG_ 2566858309 EnergyInstantElPwr "Energy Instant Electric Power";
BA_ "GenSigTimeoutTime_PCM" SG_ 2566858309 EnergyInstantElPwr 5000;
BA_ "GenSigTimeoutTime_SGW__" SG_ 2566858309 EnergyInstantElPwr 5000;
BA_ "SigType" SG_ 2566858309 EnergyInstantElPwr 1;
BA_ "CI_ParId" SG_ 2566858309 VehStsOnDrivMode "IB746";
BA_ "CI_SigId" SG_ 2566858309 VehStsOnDrivMode 1853;
BA_ "CI_SigName" SG_ 2566858309 VehStsOnDrivMode "Vehicle state on drive mode ";
BA_ "GenSigTimeoutTime_PCM" SG_ 2566858309 VehStsOnDrivMode 5000;
BA_ "GenSigTimeoutTime_SGW__" SG_ 2566858309 VehStsOnDrivMode 5000;
BA_ "SigType" SG_ 2566858309 VehStsOnDrivMode 4;
BA_ "CI_ParId" SG_ 2566858309 ChgIncident_OvernightModeFullEle "IB747";
BA_ "CI_SigId" SG_ 2566858309 ChgIncident_OvernightModeFullEle 1854;
BA_ "CI_SigName" SG_ 2566858309 ChgIncident_OvernightModeFullEle "Charging incident – Overnight mode - Full Elec";
BA_ "GenSigTimeoutTime_PCM" SG_ 2566858309 ChgIncident_OvernightModeFullEle 5000;
BA_ "GenSigTimeoutTime_SGW__" SG_ 2566858309 ChgIncident_OvernightModeFullEle 5000;
BA_ "CI_ParId" SG_ 2566858309 ChgIncident_InServOpportunityChg "IB748";
BA_ "CI_SigId" SG_ 2566858309 ChgIncident_InServOpportunityChg 1855;
BA_ "CI_SigName" SG_ 2566858309 ChgIncident_InServOpportunityChg "Charging incident – In service Opportunity charging - Full Elec";
BA_ "GenSigTimeoutTime_PCM" SG_ 2566858309 ChgIncident_InServOpportunityChg 5000;
BA_ "GenSigTimeoutTime_SGW__" SG_ 2566858309 ChgIncident_InServOpportunityChg 5000;
BA_ "CI_ParId" SG_ 2566858309 LowPwrSupplyLevFullElec "IB749";
BA_ "CI_SigId" SG_ 2566858309 LowPwrSupplyLevFullElec 1856;
BA_ "CI_SigName" SG_ 2566858309 LowPwrSupplyLevFullElec "Low power supply  level - Full Elec";
BA_ "GenSigTimeoutTime_PCM" SG_ 2566858309 LowPwrSupplyLevFullElec 5000;
BA_ "GenSigTimeoutTime_SGW__" SG_ 2566858309 LowPwrSupplyLevFullElec 5000;
BA_ "CI_ParId" SG_ 2566858309 CanPwr3FaultFullElec "IB750";
BA_ "CI_SigId" SG_ 2566858309 CanPwr3FaultFullElec 1857;
BA_ "CI_SigName" SG_ 2566858309 CanPwr3FaultFullElec "CAN POWER 3 fault - Full Elec";
BA_ "GenSigTimeoutTime_PCM" SG_ 2566858309 CanPwr3FaultFullElec 5000;
BA_ "GenSigTimeoutTime_SGW__" SG_ 2566858309 CanPwr3FaultFullElec 5000;
BA_ "CI_ParId" SG_ 2566858309 HeatOnFullElec "IB751";
BA_ "CI_SigId" SG_ 2566858309 HeatOnFullElec 1858;
BA_ "CI_SigName" SG_ 2566858309 HeatOnFullElec "Heating On - Full Elec";
BA_ "GenSigTimeoutTime_PCM" SG_ 2566858309 HeatOnFullElec 5000;
BA_ "GenSigTimeoutTime_SGW__" SG_ 2566858309 HeatOnFullElec 5000;
BA_ "CI_ParId" SG_ 2566858309 EmbeddedEnergy "IB752";
BA_ "CI_SigId" SG_ 2566858309 EmbeddedEnergy 1859;
BA_ "CI_SigName" SG_ 2566858309 EmbeddedEnergy "Embedded Energy";
BA_ "GenSigTimeoutTime_PCM" SG_ 2566858309 EmbeddedEnergy 5000;
BA_ "GenSigTimeoutTime_SGW__" SG_ 2566858309 EmbeddedEnergy 5000;
BA_ "SigType" SG_ 2566858309 EmbeddedEnergy 1;
BA_ "CI_ParId" SG_ 2566870597 VehMode "IB753";
BA_ "CI_SigId" SG_ 2566870597 VehMode 1861;
BA_ "CI_SigName" SG_ 2566870597 VehMode "Vehicle Mode";
BA_ "GenSigTimeoutTime_PCM" SG_ 2566870597 VehMode 5000;
BA_ "GenSigTimeoutTime_SGW__" SG_ 2566870597 VehMode 5000;
BA_ "CI_ParId" SG_ 2566870597 HeatLiquidLowLev "IB756";
BA_ "CI_SigId" SG_ 2566870597 HeatLiquidLowLev 1864;
BA_ "CI_SigName" SG_ 2566870597 HeatLiquidLowLev "Heating Liquid Low Level";
BA_ "GenSigTimeoutTime_PCM" SG_ 2566870597 HeatLiquidLowLev 5000;
BA_ "GenSigTimeoutTime_SGW__" SG_ 2566870597 HeatLiquidLowLev 5000;
BA_ "CI_ParId" SG_ 2566870597 HeatFuelLowLev "IB757";
BA_ "CI_SigId" SG_ 2566870597 HeatFuelLowLev 1865;
BA_ "CI_SigName" SG_ 2566870597 HeatFuelLowLev "Heating Fuel Low Level";
BA_ "GenSigTimeoutTime_PCM" SG_ 2566870597 HeatFuelLowLev 5000;
BA_ "GenSigTimeoutTime_SGW__" SG_ 2566870597 HeatFuelLowLev 5000;
BA_ "CI_ParId" SG_ 2566870597 HeatSysHighTempFault "IB758";
BA_ "CI_SigId" SG_ 2566870597 HeatSysHighTempFault 1866;
BA_ "CI_SigName" SG_ 2566870597 HeatSysHighTempFault "Heating system high temperature fault";
BA_ "GenSigTimeoutTime_PCM" SG_ 2566870597 HeatSysHighTempFault 5000;
BA_ "GenSigTimeoutTime_SGW__" SG_ 2566870597 HeatSysHighTempFault 5000;
BA_ "CI_ParId" SG_ 2566870597 ParkBrkSwFullyApplied "IB759";
BA_ "CI_SigId" SG_ 2566870597 ParkBrkSwFullyApplied 1867;
BA_ "CI_SigName" SG_ 2566870597 ParkBrkSwFullyApplied "Parking Brake Switch fully applied";
BA_ "GenSigTimeoutTime_PCM" SG_ 2566870597 ParkBrkSwFullyApplied 5000;
BA_ "GenSigTimeoutTime_SGW__" SG_ 2566870597 ParkBrkSwFullyApplied 5000;
BA_ "CI_ParId" SG_ 2566870597 FaeSts "IB760";
BA_ "CI_SigId" SG_ 2566870597 FaeSts 1868;
BA_ "CI_SigName" SG_ 2566870597 FaeSts "FAE status";
BA_ "GenSigTimeoutTime_PCM" SG_ 2566870597 FaeSts 5000;
BA_ "GenSigTimeoutTime_SGW__" SG_ 2566870597 FaeSts 5000;
BA_ "SigType" SG_ 2566870597 FaeSts 4;
BA_ "CI_ParId" SG_ 2566870597 FipoSts "IB761";
BA_ "CI_SigId" SG_ 2566870597 FipoSts 1869;
BA_ "CI_SigName" SG_ 2566870597 FipoSts "FIPO status";
BA_ "GenSigTimeoutTime_PCM" SG_ 2566870597 FipoSts 5000;
BA_ "GenSigTimeoutTime_SGW__" SG_ 2566870597 FipoSts 5000;
BA_ "SigType" SG_ 2566870597 FipoSts 4;
BA_ "CI_ParId" SG_ 2566870597 EmerBtnSts "IB762";
BA_ "CI_SigId" SG_ 2566870597 EmerBtnSts 1870;
BA_ "CI_SigName" SG_ 2566870597 EmerBtnSts "Emergency button state ";
BA_ "GenSigTimeoutTime_PCM" SG_ 2566870597 EmerBtnSts 5000;
BA_ "GenSigTimeoutTime_SGW__" SG_ 2566870597 EmerBtnSts 5000;
BA_ "CI_ParId" SG_ 2566870597 Door1EmerInh "IB763";
BA_ "CI_SigId" SG_ 2566870597 Door1EmerInh 1871;
BA_ "CI_SigName" SG_ 2566870597 Door1EmerInh "Door 1 - Emergency inhibition";
BA_ "GenSigTimeoutTime_PCM" SG_ 2566870597 Door1EmerInh 5000;
BA_ "GenSigTimeoutTime_SGW__" SG_ 2566870597 Door1EmerInh 5000;
BA_ "CI_ParId" SG_ 2566870597 Door2EmerInh "IB764";
BA_ "CI_SigId" SG_ 2566870597 Door2EmerInh 1872;
BA_ "CI_SigName" SG_ 2566870597 Door2EmerInh "Door 2 - Emergency inhibition";
BA_ "GenSigTimeoutTime_PCM" SG_ 2566870597 Door2EmerInh 5000;
BA_ "GenSigTimeoutTime_SGW__" SG_ 2566870597 Door2EmerInh 5000;
BA_ "CI_ParId" SG_ 2566870597 Door3EmerInh "IB765";
BA_ "CI_SigId" SG_ 2566870597 Door3EmerInh 1873;
BA_ "CI_SigName" SG_ 2566870597 Door3EmerInh "Door 3 - Emergency inhibition";
BA_ "GenSigTimeoutTime_PCM" SG_ 2566870597 Door3EmerInh 5000;
BA_ "GenSigTimeoutTime_SGW__" SG_ 2566870597 Door3EmerInh 5000;
BA_ "CI_ParId" SG_ 2566870597 Door4EmerInh "IB766";
BA_ "CI_SigId" SG_ 2566870597 Door4EmerInh 1874;
BA_ "CI_SigName" SG_ 2566870597 Door4EmerInh "Door 4 - Emergency inhibition";
BA_ "GenSigTimeoutTime_PCM" SG_ 2566870597 Door4EmerInh 5000;
BA_ "GenSigTimeoutTime_SGW__" SG_ 2566870597 Door4EmerInh 5000;
BA_ "CI_ParId" SG_ 2566870597 Door1ActvInEmerMode "IB767";
BA_ "CI_SigId" SG_ 2566870597 Door1ActvInEmerMode 1875;
BA_ "CI_SigName" SG_ 2566870597 Door1ActvInEmerMode "Door 1 activated in emergency mode";
BA_ "GenSigTimeoutTime_PCM" SG_ 2566870597 Door1ActvInEmerMode 5000;
BA_ "GenSigTimeoutTime_SGW__" SG_ 2566870597 Door1ActvInEmerMode 5000;
BA_ "CI_ParId" SG_ 2566870597 Door2ActvInEmerMode "IB768";
BA_ "CI_SigId" SG_ 2566870597 Door2ActvInEmerMode 1876;
BA_ "CI_SigName" SG_ 2566870597 Door2ActvInEmerMode "Door 2 activated in emergency mode";
BA_ "GenSigTimeoutTime_PCM" SG_ 2566870597 Door2ActvInEmerMode 5000;
BA_ "GenSigTimeoutTime_SGW__" SG_ 2566870597 Door2ActvInEmerMode 5000;
BA_ "CI_ParId" SG_ 2566870597 Door3ActvInEmerMode "IB769";
BA_ "CI_SigId" SG_ 2566870597 Door3ActvInEmerMode 1877;
BA_ "CI_SigName" SG_ 2566870597 Door3ActvInEmerMode "Door 3 activated in emergency mode";
BA_ "GenSigTimeoutTime_PCM" SG_ 2566870597 Door3ActvInEmerMode 5000;
BA_ "GenSigTimeoutTime_SGW__" SG_ 2566870597 Door3ActvInEmerMode 5000;
BA_ "CI_ParId" SG_ 2566870597 Door4ActvInEmerMode "IB770";
BA_ "CI_SigId" SG_ 2566870597 Door4ActvInEmerMode 1878;
BA_ "CI_SigName" SG_ 2566870597 Door4ActvInEmerMode "Door 4 activated in emergency mode";
BA_ "GenSigTimeoutTime_PCM" SG_ 2566870597 Door4ActvInEmerMode 5000;
BA_ "GenSigTimeoutTime_SGW__" SG_ 2566870597 Door4ActvInEmerMode 5000;
BA_ "CI_ParId" SG_ 2566870597 LastDoor1CmdCode "IB771";
BA_ "CI_SigId" SG_ 2566870597 LastDoor1CmdCode 1879;
BA_ "CI_SigName" SG_ 2566870597 LastDoor1CmdCode "Last door 1 command code";
BA_ "GenSigTimeoutTime_PCM" SG_ 2566870597 LastDoor1CmdCode 5000;
BA_ "GenSigTimeoutTime_SGW__" SG_ 2566870597 LastDoor1CmdCode 5000;
BA_ "CI_ParId" SG_ 2566870597 LastDoor2CmdCode "IB772";
BA_ "CI_SigId" SG_ 2566870597 LastDoor2CmdCode 1880;
BA_ "CI_SigName" SG_ 2566870597 LastDoor2CmdCode "Last door 2 command code";
BA_ "GenSigTimeoutTime_PCM" SG_ 2566870597 LastDoor2CmdCode 5000;
BA_ "GenSigTimeoutTime_SGW__" SG_ 2566870597 LastDoor2CmdCode 5000;
BA_ "CI_ParId" SG_ 2566870597 LastDoor3CmdCode "IB773";
BA_ "CI_SigId" SG_ 2566870597 LastDoor3CmdCode 1881;
BA_ "CI_SigName" SG_ 2566870597 LastDoor3CmdCode "Last door 3 command code";
BA_ "GenSigTimeoutTime_PCM" SG_ 2566870597 LastDoor3CmdCode 5000;
BA_ "GenSigTimeoutTime_SGW__" SG_ 2566870597 LastDoor3CmdCode 5000;
BA_ "CI_ParId" SG_ 2566870597 LastDoor4CmdCode "IB774";
BA_ "CI_SigId" SG_ 2566870597 LastDoor4CmdCode 1882;
BA_ "CI_SigName" SG_ 2566870597 LastDoor4CmdCode "Last door 4 command code";
BA_ "GenSigTimeoutTime_PCM" SG_ 2566870597 LastDoor4CmdCode 5000;
BA_ "GenSigTimeoutTime_SGW__" SG_ 2566870597 LastDoor4CmdCode 5000;
BA_ "CI_ParId" SG_ 2566870597 AirDryerSts "IB775";
BA_ "CI_SigId" SG_ 2566870597 AirDryerSts 1883;
BA_ "CI_SigName" SG_ 2566870597 AirDryerSts "Air Dryer Status";
BA_ "GenSigTimeoutTime_PCM" SG_ 2566870597 AirDryerSts 5000;
BA_ "GenSigTimeoutTime_SGW__" SG_ 2566870597 AirDryerSts 5000;
BA_ "CI_ParId" SG_ 2566870597 OverheatingComprElec "IB776";
BA_ "CI_SigId" SG_ 2566870597 OverheatingComprElec 1884;
BA_ "CI_SigName" SG_ 2566870597 OverheatingComprElec "Overheating Compressor Elec";
BA_ "GenSigTimeoutTime_PCM" SG_ 2566870597 OverheatingComprElec 5000;
BA_ "GenSigTimeoutTime_SGW__" SG_ 2566870597 OverheatingComprElec 5000;
BA_ "CI_ParId" SG_ 2566854469 NoBat1Recharge "IB777";
BA_ "CI_SigId" SG_ 2566854469 NoBat1Recharge 1886;
BA_ "CI_SigName" SG_ 2566854469 NoBat1Recharge "No battery 1 recharge";
BA_ "GenSigTimeoutTime_PCM" SG_ 2566854469 NoBat1Recharge 5000;
BA_ "GenSigTimeoutTime_SGW__" SG_ 2566854469 NoBat1Recharge 5000;
BA_ "CI_ParId" SG_ 2566854469 NoBat2Recharge "IB778";
BA_ "CI_SigId" SG_ 2566854469 NoBat2Recharge 1887;
BA_ "CI_SigName" SG_ 2566854469 NoBat2Recharge "No battery 2 recharge";
BA_ "GenSigTimeoutTime_PCM" SG_ 2566854469 NoBat2Recharge 5000;
BA_ "GenSigTimeoutTime_SGW__" SG_ 2566854469 NoBat2Recharge 5000;
BA_ "CI_ParId" SG_ 2566854469 NoBat3Recharge "IB779";
BA_ "CI_SigId" SG_ 2566854469 NoBat3Recharge 1888;
BA_ "CI_SigName" SG_ 2566854469 NoBat3Recharge "No battery 3  recharge";
BA_ "GenSigTimeoutTime_PCM" SG_ 2566854469 NoBat3Recharge 5000;
BA_ "GenSigTimeoutTime_SGW__" SG_ 2566854469 NoBat3Recharge 5000;
BA_ "CI_ParId" SG_ 2566854469 _3RdAxlePrsLow "IB780";
BA_ "CI_SigId" SG_ 2566854469 _3RdAxlePrsLow 1889;
BA_ "CI_SigName" SG_ 2566854469 _3RdAxlePrsLow "3rd axle pressure Low";
BA_ "GenSigTimeoutTime_PCM" SG_ 2566854469 _3RdAxlePrsLow 5000;
BA_ "GenSigTimeoutTime_SGW__" SG_ 2566854469 _3RdAxlePrsLow 5000;
BA_ "CI_ParId" SG_ 2566854469 _3RdAxleOilLevLow "IB781";
BA_ "CI_SigId" SG_ 2566854469 _3RdAxleOilLevLow 1890;
BA_ "CI_SigName" SG_ 2566854469 _3RdAxleOilLevLow "3rd axle oil level low";
BA_ "GenSigTimeoutTime_PCM" SG_ 2566854469 _3RdAxleOilLevLow 5000;
BA_ "GenSigTimeoutTime_SGW__" SG_ 2566854469 _3RdAxleOilLevLow 5000;
BA_ "CI_ParId" SG_ 2566854469 _3RdAxleOvl "IB782";
BA_ "CI_SigId" SG_ 2566854469 _3RdAxleOvl 1891;
BA_ "CI_SigName" SG_ 2566854469 _3RdAxleOvl "3rd axle overload";
BA_ "GenSigTimeoutTime_PCM" SG_ 2566854469 _3RdAxleOvl 5000;
BA_ "GenSigTimeoutTime_SGW__" SG_ 2566854469 _3RdAxleOvl 5000;
BA_ "CI_ParId" SG_ 2566854469 PropellerShaftOverspeedAlert "IB784";
BA_ "CI_SigId" SG_ 2566854469 PropellerShaftOverspeedAlert 1893;
BA_ "CI_SigName" SG_ 2566854469 PropellerShaftOverspeedAlert "Propeller shaft overspeed alert";
BA_ "GenSigTimeoutTime_PCM" SG_ 2566854469 PropellerShaftOverspeedAlert 5000;
BA_ "GenSigTimeoutTime_SGW__" SG_ 2566854469 PropellerShaftOverspeedAlert 5000;
BA_ "CI_ParId" SG_ 2566854469 ExtTempIvecoBus "IB785";
BA_ "CI_SigId" SG_ 2566854469 ExtTempIvecoBus 1894;
BA_ "CI_SigName" SG_ 2566854469 ExtTempIvecoBus "External temperature - IVECO BUS";
BA_ "GenSigTimeoutTime_PCM" SG_ 2566854469 ExtTempIvecoBus 5000;
BA_ "GenSigTimeoutTime_SGW__" SG_ 2566854469 ExtTempIvecoBus 5000;
BA_ "SigType" SG_ 2566854469 ExtTempIvecoBus 1;
BA_ "CI_ParId" SG_ 2566854469 TotEngCntsInfo "IB786";
BA_ "CI_SigId" SG_ 2566854469 TotEngCntsInfo 1895;
BA_ "CI_SigName" SG_ 2566854469 TotEngCntsInfo "Total engine counters information";
BA_ "GenSigTimeoutTime_PCM" SG_ 2566854469 TotEngCntsInfo 5000;
BA_ "GenSigTimeoutTime_SGW__" SG_ 2566854469 TotEngCntsInfo 5000;
BA_ "SigType" SG_ 2566854469 TotEngCntsInfo 1;
BA_ "CI_ParId" SG_ 2566854469 OilMaintenanceAlert "IB2158";
BA_ "CI_SigId" SG_ 2566854469 OilMaintenanceAlert 17499;
BA_ "CI_SigName" SG_ 2566854469 OilMaintenanceAlert "Oil maintenance alert";
BA_ "GenSigTimeoutTime_PCM" SG_ 2566854469 OilMaintenanceAlert 5000;
BA_ "GenSigTimeoutTime_SGW__" SG_ 2566854469 OilMaintenanceAlert 5000;
BA_ "SigType" SG_ 2566854469 OilMaintenanceAlert 4;
BA_ "CI_ParId" SG_ 2566854469 OilMaintenanceReset "IB2159";
BA_ "CI_SigId" SG_ 2566854469 OilMaintenanceReset 17500;
BA_ "CI_SigName" SG_ 2566854469 OilMaintenanceReset "Oil maintenance reset";
BA_ "GenSigTimeoutTime_PCM" SG_ 2566854469 OilMaintenanceReset 5000;
BA_ "GenSigTimeoutTime_SGW__" SG_ 2566854469 OilMaintenanceReset 5000;
BA_ "SigType" SG_ 2566854469 OilMaintenanceReset 4;
BA_ "CI_ParId" SG_ 2566906905 AcComprInvActvReq "IB644";
BA_ "CI_SigId" SG_ 2566906905 AcComprInvActvReq 10924;
BA_ "CI_SigName" SG_ 2566906905 AcComprInvActvReq "Air conditioning compressor inverter activation request";
BA_ "GenSigTimeoutTime_NBM_" SG_ 2566906905 AcComprInvActvReq 5000;
BA_ "GenSigTimeoutTime_PCM" SG_ 2566906905 AcComprInvActvReq 5000;
BA_ "GenSigTimeoutTime_SGW__" SG_ 2566906905 AcComprInvActvReq 5000;
BA_ "SigType" SG_ 2566906905 AcComprInvActvReq 4;
BA_ "CI_ParId" SG_ 2566906905 CirculationSts "IB645";
BA_ "CI_SigId" SG_ 2566906905 CirculationSts 10925;
BA_ "CI_SigName" SG_ 2566906905 CirculationSts "Circulation status";
BA_ "GenSigTimeoutTime_PCM" SG_ 2566906905 CirculationSts 5000;
BA_ "GenSigTimeoutTime_SGW__" SG_ 2566906905 CirculationSts 5000;
BA_ "SigType" SG_ 2566906905 CirculationSts 4;
BA_ "CI_ParId" SG_ 2566906905 ThermHtrSts "IB646";
BA_ "CI_SigId" SG_ 2566906905 ThermHtrSts 10926;
BA_ "CI_SigName" SG_ 2566906905 ThermHtrSts "Thermal heater status";
BA_ "GenSigTimeoutTime_NBM_" SG_ 2566906905 ThermHtrSts 5000;
BA_ "GenSigTimeoutTime_PCM" SG_ 2566906905 ThermHtrSts 5000;
BA_ "GenSigTimeoutTime_SGW__" SG_ 2566906905 ThermHtrSts 5000;
BA_ "SigType" SG_ 2566906905 ThermHtrSts 4;
BA_ "CI_ParId" SG_ 2566906905 ElHtrSts "IB647";
BA_ "CI_SigId" SG_ 2566906905 ElHtrSts 10927;
BA_ "CI_SigName" SG_ 2566906905 ElHtrSts "Electrical heater status";
BA_ "GenSigTimeoutTime_NBM_" SG_ 2566906905 ElHtrSts 5000;
BA_ "GenSigTimeoutTime_PCM" SG_ 2566906905 ElHtrSts 5000;
BA_ "GenSigTimeoutTime_SGW__" SG_ 2566906905 ElHtrSts 5000;
BA_ "SigType" SG_ 2566906905 ElHtrSts 4;
BA_ "CI_ParId" SG_ 2566906905 AcComprInvSpeedReq "IB648";
BA_ "CI_SigId" SG_ 2566906905 AcComprInvSpeedReq 10928;
BA_ "CI_SigName" SG_ 2566906905 AcComprInvSpeedReq "Air conditioning compressor inverter speed request";
BA_ "GenSigTimeoutTime_NBM_" SG_ 2566906905 AcComprInvSpeedReq 5000;
BA_ "GenSigTimeoutTime_PCM" SG_ 2566906905 AcComprInvSpeedReq 5000;
BA_ "GenSigTimeoutTime_SGW__" SG_ 2566906905 AcComprInvSpeedReq 5000;
BA_ "SigType" SG_ 2566906905 AcComprInvSpeedReq 1;
BA_ "CI_ParId" SG_ 2566906905 AcSuctPrs "IB649";
BA_ "CI_SigId" SG_ 2566906905 AcSuctPrs 10929;
BA_ "CI_SigName" SG_ 2566906905 AcSuctPrs "Air conditioning suction pressure";
BA_ "GenSigTimeoutTime_NBM_" SG_ 2566906905 AcSuctPrs 5000;
BA_ "GenSigTimeoutTime_PCM" SG_ 2566906905 AcSuctPrs 5000;
BA_ "GenSigTimeoutTime_SGW__" SG_ 2566906905 AcSuctPrs 5000;
BA_ "SigType" SG_ 2566906905 AcSuctPrs 1;
BA_ "CI_ParId" SG_ 2566906905 AcDischPrs "IB650";
BA_ "CI_SigId" SG_ 2566906905 AcDischPrs 10930;
BA_ "CI_SigName" SG_ 2566906905 AcDischPrs "Air conditioning discharge pressure";
BA_ "GenSigTimeoutTime_NBM_" SG_ 2566906905 AcDischPrs 5000;
BA_ "GenSigTimeoutTime_PCM" SG_ 2566906905 AcDischPrs 5000;
BA_ "GenSigTimeoutTime_SGW__" SG_ 2566906905 AcDischPrs 5000;
BA_ "SigType" SG_ 2566906905 AcDischPrs 1;
BA_ "CI_ParId" SG_ 2566906905 StartStopInhibMildHybrid "IB1385";
BA_ "CI_SigId" SG_ 2566906905 StartStopInhibMildHybrid 10931;
BA_ "CI_SigName" SG_ 2566906905 StartStopInhibMildHybrid "Start/Stop Inhibit Mild Hybrid ";
BA_ "GenSigTimeoutTime_NBM" SG_ 2566906905 StartStopInhibMildHybrid 5000;
BA_ "GenSigTimeoutTime_PCM" SG_ 2566906905 StartStopInhibMildHybrid 5000;
BA_ "GenSigTimeoutTime_SGW__" SG_ 2566906905 StartStopInhibMildHybrid 5000;
BA_ "SigType" SG_ 2566906905 StartStopInhibMildHybrid 4;
BA_ "CI_ParId" SG_ 2566906905 ElHtrOverheating "IB1377";
BA_ "CI_SigId" SG_ 2566906905 ElHtrOverheating 10932;
BA_ "CI_SigName" SG_ 2566906905 ElHtrOverheating "Electric Heater Overheating";
BA_ "GenSigTimeoutTime_NBM_" SG_ 2566906905 ElHtrOverheating 5000;
BA_ "GenSigTimeoutTime_PCM" SG_ 2566906905 ElHtrOverheating 5000;
BA_ "GenSigTimeoutTime_SGW__" SG_ 2566906905 ElHtrOverheating 5000;
BA_ "SigType" SG_ 2566906905 ElHtrOverheating 4;
BA_ "CI_ParId" SG_ 2566906905 ElHtrHvRelayDamaged "IB1378";
BA_ "CI_SigId" SG_ 2566906905 ElHtrHvRelayDamaged 10933;
BA_ "CI_SigName" SG_ 2566906905 ElHtrHvRelayDamaged "Electric Heater HV relay damaged";
BA_ "GenSigTimeoutTime_NBM_" SG_ 2566906905 ElHtrHvRelayDamaged 5000;
BA_ "GenSigTimeoutTime_PCM" SG_ 2566906905 ElHtrHvRelayDamaged 5000;
BA_ "GenSigTimeoutTime_SGW__" SG_ 2566906905 ElHtrHvRelayDamaged 5000;
BA_ "SigType" SG_ 2566906905 ElHtrHvRelayDamaged 4;
BA_ "CI_ParId" SG_ 2566906905 ElHtrOverheatingWarn "IB1379";
BA_ "CI_SigId" SG_ 2566906905 ElHtrOverheatingWarn 10934;
BA_ "CI_SigName" SG_ 2566906905 ElHtrOverheatingWarn "Electric Heater Overheating warning";
BA_ "GenSigTimeoutTime_NBM_" SG_ 2566906905 ElHtrOverheatingWarn 5000;
BA_ "GenSigTimeoutTime_PCM" SG_ 2566906905 ElHtrOverheatingWarn 5000;
BA_ "GenSigTimeoutTime_SGW__" SG_ 2566906905 ElHtrOverheatingWarn 5000;
BA_ "SigType" SG_ 2566906905 ElHtrOverheatingWarn 4;
BA_ "CI_ParId" SG_ 2566846467 TransmOilTemp1 "177";
BA_ "CI_SigId" SG_ 2566846467 TransmOilTemp1 635;
BA_ "CI_SigName" SG_ 2566846467 TransmOilTemp1 "Transmission Oil Temperature 1";
BA_ "GenSigTimeoutTime_FMS4" SG_ 2566846467 TransmOilTemp1 5000;
BA_ "GenSigTimeoutTime_MulticS" SG_ 2566846467 TransmOilTemp1 5000;
BA_ "GenSigTimeoutTime_NBM" SG_ 2566846467 TransmOilTemp1 5000;
BA_ "GenSigTimeoutTime_PCM" SG_ 2566846467 TransmOilTemp1 5000;
BA_ "GenSigTimeoutTime_SGW__" SG_ 2566846467 TransmOilTemp1 5000;
BA_ "SPN" SG_ 2566846467 TransmOilTemp1 177;
BA_ "SigType" SG_ 2566846467 TransmOilTemp1 1;
BA_ "CI_ParId" SG_ 2566852119 TripBatEnergy "52004";
BA_ "CI_SigId" SG_ 2566852119 TripBatEnergy 1902;
BA_ "CI_SigName" SG_ 2566852119 TripBatEnergy "Trip Battery Energy";
BA_ "GenSigTimeoutTime_FMS4" SG_ 2566852119 TripBatEnergy 5000;
BA_ "GenSigTimeoutTime_PCM" SG_ 2566852119 TripBatEnergy 5000;
BA_ "GenSigTimeoutTime_SGW__" SG_ 2566852119 TripBatEnergy 5000;
BA_ "SPN" SG_ 2566852119 TripBatEnergy 52004;
BA_ "SigType" SG_ 2566852119 TripBatEnergy 1;
BA_ "CI_ParId" SG_ 2566852119 TripTractEnergy "52005";
BA_ "CI_SigId" SG_ 2566852119 TripTractEnergy 1903;
BA_ "CI_SigName" SG_ 2566852119 TripTractEnergy "Trip Traction Energy";
BA_ "GenSigTimeoutTime_FMS4" SG_ 2566852119 TripTractEnergy 5000;
BA_ "GenSigTimeoutTime_PCM" SG_ 2566852119 TripTractEnergy 5000;
BA_ "GenSigTimeoutTime_SGW__" SG_ 2566852119 TripTractEnergy 5000;
BA_ "SPN" SG_ 2566852119 TripTractEnergy 52005;
BA_ "SigType" SG_ 2566852119 TripTractEnergy 1;
BA_ "CI_ParId" SG_ 2566852119 TripAuxEnergy "52006";
BA_ "CI_SigId" SG_ 2566852119 TripAuxEnergy 1904;
BA_ "CI_SigName" SG_ 2566852119 TripAuxEnergy "Trip Auxiliary Energy";
BA_ "GenSigTimeoutTime_FMS4" SG_ 2566852119 TripAuxEnergy 5000;
BA_ "GenSigTimeoutTime_PCM" SG_ 2566852119 TripAuxEnergy 5000;
BA_ "GenSigTimeoutTime_SGW__" SG_ 2566852119 TripAuxEnergy 5000;
BA_ "SPN" SG_ 2566852119 TripAuxEnergy 52006;
BA_ "SigType" SG_ 2566852119 TripAuxEnergy 1;
BA_ "CI_ParId" SG_ 2566852119 TripRecovEnergy "52007";
BA_ "CI_SigId" SG_ 2566852119 TripRecovEnergy 1905;
BA_ "CI_SigName" SG_ 2566852119 TripRecovEnergy "Trip Recovery Energy ";
BA_ "GenSigTimeoutTime_FMS4" SG_ 2566852119 TripRecovEnergy 5000;
BA_ "GenSigTimeoutTime_PCM" SG_ 2566852119 TripRecovEnergy 5000;
BA_ "GenSigTimeoutTime_SGW__" SG_ 2566852119 TripRecovEnergy 5000;
BA_ "SPN" SG_ 2566852119 TripRecovEnergy 52007;
BA_ "SigType" SG_ 2566852119 TripRecovEnergy 1;
BA_ "CI_ParId" SG_ 2566856261 TripAcEnergy "IB806";
BA_ "CI_SigId" SG_ 2566856261 TripAcEnergy 1924;
BA_ "CI_SigName" SG_ 2566856261 TripAcEnergy "Trip A/C Energy";
BA_ "GenSigTimeoutTime_PCM" SG_ 2566856261 TripAcEnergy 5000;
BA_ "GenSigTimeoutTime_SGW__" SG_ 2566856261 TripAcEnergy 5000;
BA_ "SigType" SG_ 2566856261 TripAcEnergy 1;
BA_ "CI_ParId" SG_ 2566856261 TripNet24VEnergy "IB807";
BA_ "CI_SigId" SG_ 2566856261 TripNet24VEnergy 1925;
BA_ "CI_SigName" SG_ 2566856261 TripNet24VEnergy "Trip Network 24V Energy";
BA_ "GenSigTimeoutTime_PCM" SG_ 2566856261 TripNet24VEnergy 5000;
BA_ "GenSigTimeoutTime_SGW__" SG_ 2566856261 TripNet24VEnergy 5000;
BA_ "SigType" SG_ 2566856261 TripNet24VEnergy 1;
BA_ "CI_ParId" SG_ 2566749463 TtBlkId "FMS000";
BA_ "CI_SigId" SG_ 2566749463 TtBlkId 3202;
BA_ "CI_SigName" SG_ 2566749463 TtBlkId "Telltale Block ID";
BA_ "GenSigTimeoutTime_FMS4" SG_ 2566749463 TtBlkId 5000;
BA_ "GenSigTimeoutTime_PCM" SG_ 2566749463 TtBlkId 5000;
BA_ "GenSigTimeoutTime_SGW__" SG_ 2566749463 TtBlkId 5000;
BA_ "CI_ParId" SG_ 2566749463 CoolAc "FMS001";
BA_ "CI_SigId" SG_ 2566749463 CoolAc 3203;
BA_ "CI_SigName" SG_ 2566749463 CoolAc "Cooling air conditioning";
BA_ "GenSigTimeoutTime_FMS4" SG_ 2566749463 CoolAc 5000;
BA_ "GenSigTimeoutTime_PCM" SG_ 2566749463 CoolAc 5000;
BA_ "GenSigTimeoutTime_SGW__" SG_ 2566749463 CoolAc 5000;
BA_ "CI_ParId" SG_ 2566749463 HighBeamMainBeam "FMS002";
BA_ "CI_SigId" SG_ 2566749463 HighBeamMainBeam 3204;
BA_ "CI_SigName" SG_ 2566749463 HighBeamMainBeam "High beam, main beam";
BA_ "GenSigTimeoutTime_FMS4" SG_ 2566749463 HighBeamMainBeam 5000;
BA_ "GenSigTimeoutTime_PCM" SG_ 2566749463 HighBeamMainBeam 5000;
BA_ "GenSigTimeoutTime_SGW__" SG_ 2566749463 HighBeamMainBeam 5000;
BA_ "CI_ParId" SG_ 2566749463 LowBeamDipBeam "FMS003";
BA_ "CI_SigId" SG_ 2566749463 LowBeamDipBeam 3205;
BA_ "CI_SigName" SG_ 2566749463 LowBeamDipBeam "Low beam, dipped beam";
BA_ "GenSigTimeoutTime_FMS4" SG_ 2566749463 LowBeamDipBeam 5000;
BA_ "GenSigTimeoutTime_PCM" SG_ 2566749463 LowBeamDipBeam 5000;
BA_ "GenSigTimeoutTime_SGW__" SG_ 2566749463 LowBeamDipBeam 5000;
BA_ "CI_ParId" SG_ 2566749463 TurnSigs "FMS004";
BA_ "CI_SigId" SG_ 2566749463 TurnSigs 3206;
BA_ "CI_SigName" SG_ 2566749463 TurnSigs "Turn signals";
BA_ "GenSigTimeoutTime_FMS4" SG_ 2566749463 TurnSigs 5000;
BA_ "GenSigTimeoutTime_PCM" SG_ 2566749463 TurnSigs 5000;
BA_ "GenSigTimeoutTime_SGW__" SG_ 2566749463 TurnSigs 5000;
BA_ "CI_ParId" SG_ 2566749463 HazardWarn "FMS005";
BA_ "CI_SigId" SG_ 2566749463 HazardWarn 3207;
BA_ "CI_SigName" SG_ 2566749463 HazardWarn "Hazard warning";
BA_ "GenSigTimeoutTime_FMS4" SG_ 2566749463 HazardWarn 5000;
BA_ "GenSigTimeoutTime_PCM" SG_ 2566749463 HazardWarn 5000;
BA_ "GenSigTimeoutTime_SGW__" SG_ 2566749463 HazardWarn 5000;
BA_ "CI_ParId" SG_ 2566749463 ProvDisOrHandiPers "FMS006";
BA_ "CI_SigId" SG_ 2566749463 ProvDisOrHandiPers 3208;
BA_ "CI_SigName" SG_ 2566749463 ProvDisOrHandiPers "Provision for the disabled or handicapped persons";
BA_ "GenSigTimeoutTime_FMS4" SG_ 2566749463 ProvDisOrHandiPers 5000;
BA_ "GenSigTimeoutTime_PCM" SG_ 2566749463 ProvDisOrHandiPers 5000;
BA_ "GenSigTimeoutTime_SGW__" SG_ 2566749463 ProvDisOrHandiPers 5000;
BA_ "CI_ParId" SG_ 2566749463 ParkBrk "FMS007";
BA_ "CI_SigId" SG_ 2566749463 ParkBrk 3209;
BA_ "CI_SigName" SG_ 2566749463 ParkBrk "Parking Brake";
BA_ "GenSigTimeoutTime_FMS4" SG_ 2566749463 ParkBrk 5000;
BA_ "GenSigTimeoutTime_PCM" SG_ 2566749463 ParkBrk 5000;
BA_ "GenSigTimeoutTime_SGW__" SG_ 2566749463 ParkBrk 5000;
BA_ "CI_ParId" SG_ 2566749463 BrkFail_BrkSysMalf "FMS008";
BA_ "CI_SigId" SG_ 2566749463 BrkFail_BrkSysMalf 3210;
BA_ "CI_SigName" SG_ 2566749463 BrkFail_BrkSysMalf "Brake failure/brake system malfunction";
BA_ "GenSigTimeoutTime_FMS4" SG_ 2566749463 BrkFail_BrkSysMalf 5000;
BA_ "GenSigTimeoutTime_PCM" SG_ 2566749463 BrkFail_BrkSysMalf 5000;
BA_ "GenSigTimeoutTime_SGW__" SG_ 2566749463 BrkFail_BrkSysMalf 5000;
BA_ "CI_ParId" SG_ 2566749463 HatchOpen "FMS009";
BA_ "CI_SigId" SG_ 2566749463 HatchOpen 3211;
BA_ "CI_SigName" SG_ 2566749463 HatchOpen "Hatch open";
BA_ "GenSigTimeoutTime_FMS4" SG_ 2566749463 HatchOpen 5000;
BA_ "GenSigTimeoutTime_PCM" SG_ 2566749463 HatchOpen 5000;
BA_ "GenSigTimeoutTime_SGW__" SG_ 2566749463 HatchOpen 5000;
BA_ "CI_ParId" SG_ 2566749463 FuelLev "FMS010";
BA_ "CI_SigId" SG_ 2566749463 FuelLev 3212;
BA_ "CI_SigName" SG_ 2566749463 FuelLev "Fuel level";
BA_ "GenSigTimeoutTime_FMS4" SG_ 2566749463 FuelLev 5000;
BA_ "GenSigTimeoutTime_PCM" SG_ 2566749463 FuelLev 5000;
BA_ "GenSigTimeoutTime_SGW__" SG_ 2566749463 FuelLev 5000;
BA_ "CI_ParId" SG_ 2566749463 EngCoolTemp_18FD7D17 "FMS011";
BA_ "CI_SigId" SG_ 2566749463 EngCoolTemp_18FD7D17 3213;
BA_ "CI_SigName" SG_ 2566749463 EngCoolTemp_18FD7D17 "Engine coolant temperature";
BA_ "GenSigTimeoutTime_FMS4" SG_ 2566749463 EngCoolTemp_18FD7D17 5000;
BA_ "GenSigTimeoutTime_PCM" SG_ 2566749463 EngCoolTemp_18FD7D17 5000;
BA_ "GenSigTimeoutTime_SGW__" SG_ 2566749463 EngCoolTemp_18FD7D17 5000;
BA_ "CI_ParId" SG_ 2566749463 BatChgCond "FMS012";
BA_ "CI_SigId" SG_ 2566749463 BatChgCond 3214;
BA_ "CI_SigName" SG_ 2566749463 BatChgCond "Battery charging condition";
BA_ "GenSigTimeoutTime_FMS4" SG_ 2566749463 BatChgCond 5000;
BA_ "GenSigTimeoutTime_PCM" SG_ 2566749463 BatChgCond 5000;
BA_ "GenSigTimeoutTime_SGW__" SG_ 2566749463 BatChgCond 5000;
BA_ "CI_ParId" SG_ 2566749463 EngOil "FMS013";
BA_ "CI_SigId" SG_ 2566749463 EngOil 3215;
BA_ "CI_SigName" SG_ 2566749463 EngOil "Engine oil";
BA_ "GenSigTimeoutTime_FMS4" SG_ 2566749463 EngOil 5000;
BA_ "GenSigTimeoutTime_PCM" SG_ 2566749463 EngOil 5000;
BA_ "GenSigTimeoutTime_SGW__" SG_ 2566749463 EngOil 5000;
BA_ "CI_ParId" SG_ 2566749463 PosLightSideLight "FMS014";
BA_ "CI_SigId" SG_ 2566749463 PosLightSideLight 3216;
BA_ "CI_SigName" SG_ 2566749463 PosLightSideLight "Position lights,side lights";
BA_ "GenSigTimeoutTime_FMS4" SG_ 2566749463 PosLightSideLight 5000;
BA_ "GenSigTimeoutTime_PCM" SG_ 2566749463 PosLightSideLight 5000;
BA_ "GenSigTimeoutTime_SGW__" SG_ 2566749463 PosLightSideLight 5000;
BA_ "CI_ParId" SG_ 2566749463 FrontFogLight "FMS015";
BA_ "CI_SigId" SG_ 2566749463 FrontFogLight 3217;
BA_ "CI_SigName" SG_ 2566749463 FrontFogLight "Front fog light";
BA_ "GenSigTimeoutTime_FMS4" SG_ 2566749463 FrontFogLight 5000;
BA_ "GenSigTimeoutTime_PCM" SG_ 2566749463 FrontFogLight 5000;
BA_ "GenSigTimeoutTime_SGW__" SG_ 2566749463 FrontFogLight 5000;
BA_ "CI_ParId" SG_ 2566749463 RearFogLight "FMS001";
BA_ "CI_SigId" SG_ 2566749463 RearFogLight 14816;
BA_ "CI_SigName" SG_ 2566749463 RearFogLight "Rear fog light";
BA_ "GenSigTimeoutTime_FMS4" SG_ 2566749463 RearFogLight 5000;
BA_ "GenSigTimeoutTime_PCM" SG_ 2566749463 RearFogLight 5000;
BA_ "GenSigTimeoutTime_SGW__" SG_ 2566749463 RearFogLight 5000;
BA_ "CI_ParId" SG_ 2566749463 ParkHeat "FMS002";
BA_ "CI_SigId" SG_ 2566749463 ParkHeat 14817;
BA_ "CI_SigName" SG_ 2566749463 ParkHeat "Park Heating";
BA_ "GenSigTimeoutTime_FMS4" SG_ 2566749463 ParkHeat 5000;
BA_ "GenSigTimeoutTime_PCM" SG_ 2566749463 ParkHeat 5000;
BA_ "GenSigTimeoutTime_SGW__" SG_ 2566749463 ParkHeat 5000;
BA_ "CI_ParId" SG_ 2566749463 Eng_Mil "FMS003";
BA_ "CI_SigId" SG_ 2566749463 Eng_Mil 14818;
BA_ "CI_SigName" SG_ 2566749463 Eng_Mil "Engine / Mil indicator";
BA_ "GenSigTimeoutTime_FMS4" SG_ 2566749463 Eng_Mil 5000;
BA_ "GenSigTimeoutTime_PCM" SG_ 2566749463 Eng_Mil 5000;
BA_ "GenSigTimeoutTime_SGW__" SG_ 2566749463 Eng_Mil 5000;
BA_ "CI_ParId" SG_ 2566749463 ServCallForMaint "FMS004";
BA_ "CI_SigId" SG_ 2566749463 ServCallForMaint 14819;
BA_ "CI_SigName" SG_ 2566749463 ServCallForMaint "Service, call for maintenance";
BA_ "GenSigTimeoutTime_FMS4" SG_ 2566749463 ServCallForMaint 5000;
BA_ "GenSigTimeoutTime_PCM" SG_ 2566749463 ServCallForMaint 5000;
BA_ "GenSigTimeoutTime_SGW__" SG_ 2566749463 ServCallForMaint 5000;
BA_ "CI_ParId" SG_ 2566749463 TransmFluidTemp "FMS005";
BA_ "CI_SigId" SG_ 2566749463 TransmFluidTemp 14820;
BA_ "CI_SigName" SG_ 2566749463 TransmFluidTemp "Transmission fluid temperature";
BA_ "GenSigTimeoutTime_FMS4" SG_ 2566749463 TransmFluidTemp 5000;
BA_ "GenSigTimeoutTime_PCM" SG_ 2566749463 TransmFluidTemp 5000;
BA_ "GenSigTimeoutTime_SGW__" SG_ 2566749463 TransmFluidTemp 5000;
BA_ "CI_ParId" SG_ 2566749463 TransmFail_Malf "FMS006";
BA_ "CI_SigId" SG_ 2566749463 TransmFail_Malf 14821;
BA_ "CI_SigName" SG_ 2566749463 TransmFail_Malf "Transmission failure/malfunction";
BA_ "GenSigTimeoutTime_FMS4" SG_ 2566749463 TransmFail_Malf 5000;
BA_ "GenSigTimeoutTime_PCM" SG_ 2566749463 TransmFail_Malf 5000;
BA_ "GenSigTimeoutTime_SGW__" SG_ 2566749463 TransmFail_Malf 5000;
BA_ "CI_ParId" SG_ 2566749463 AntiLckBrkSysFail "FMS007";
BA_ "CI_SigId" SG_ 2566749463 AntiLckBrkSysFail 14822;
BA_ "CI_SigName" SG_ 2566749463 AntiLckBrkSysFail "Anti-lock brake system failure";
BA_ "GenSigTimeoutTime_FMS4" SG_ 2566749463 AntiLckBrkSysFail 5000;
BA_ "GenSigTimeoutTime_PCM" SG_ 2566749463 AntiLckBrkSysFail 5000;
BA_ "GenSigTimeoutTime_SGW__" SG_ 2566749463 AntiLckBrkSysFail 5000;
BA_ "CI_ParId" SG_ 2566749463 WornBrkLin "FMS008";
BA_ "CI_SigId" SG_ 2566749463 WornBrkLin 14823;
BA_ "CI_SigName" SG_ 2566749463 WornBrkLin "Worn brake linings";
BA_ "GenSigTimeoutTime_FMS4" SG_ 2566749463 WornBrkLin 5000;
BA_ "GenSigTimeoutTime_PCM" SG_ 2566749463 WornBrkLin 5000;
BA_ "GenSigTimeoutTime_SGW__" SG_ 2566749463 WornBrkLin 5000;
BA_ "CI_ParId" SG_ 2566749463 Windsh_WindshWasherFluid "FMS009";
BA_ "CI_SigId" SG_ 2566749463 Windsh_WindshWasherFluid 14824;
BA_ "CI_SigName" SG_ 2566749463 Windsh_WindshWasherFluid "Windscreen/windshield washer fluid";
BA_ "GenSigTimeoutTime_FMS4" SG_ 2566749463 Windsh_WindshWasherFluid 5000;
BA_ "GenSigTimeoutTime_PCM" SG_ 2566749463 Windsh_WindshWasherFluid 5000;
BA_ "GenSigTimeoutTime_SGW__" SG_ 2566749463 Windsh_WindshWasherFluid 5000;
BA_ "CI_ParId" SG_ 2566749463 TireFail_Malf "FMS010";
BA_ "CI_SigId" SG_ 2566749463 TireFail_Malf 14825;
BA_ "CI_SigName" SG_ 2566749463 TireFail_Malf "Tire failure/malfunction";
BA_ "GenSigTimeoutTime_FMS4" SG_ 2566749463 TireFail_Malf 5000;
BA_ "GenSigTimeoutTime_PCM" SG_ 2566749463 TireFail_Malf 5000;
BA_ "GenSigTimeoutTime_SGW__" SG_ 2566749463 TireFail_Malf 5000;
BA_ "CI_ParId" SG_ 2566749463 Malf_GenFail "FMS011";
BA_ "CI_SigId" SG_ 2566749463 Malf_GenFail 14826;
BA_ "CI_SigName" SG_ 2566749463 Malf_GenFail "Malfunction/general failure";
BA_ "GenSigTimeoutTime_FMS4" SG_ 2566749463 Malf_GenFail 5000;
BA_ "GenSigTimeoutTime_PCM" SG_ 2566749463 Malf_GenFail 5000;
BA_ "GenSigTimeoutTime_SGW__" SG_ 2566749463 Malf_GenFail 5000;
BA_ "CI_ParId" SG_ 2566749463 EngOilTemp "FMS012";
BA_ "CI_SigId" SG_ 2566749463 EngOilTemp 14827;
BA_ "CI_SigName" SG_ 2566749463 EngOilTemp "Engine oil temperature";
BA_ "GenSigTimeoutTime_FMS4" SG_ 2566749463 EngOilTemp 5000;
BA_ "GenSigTimeoutTime_PCM" SG_ 2566749463 EngOilTemp 5000;
BA_ "GenSigTimeoutTime_SGW__" SG_ 2566749463 EngOilTemp 5000;
BA_ "CI_ParId" SG_ 2566749463 EngOilLev "FMS013";
BA_ "CI_SigId" SG_ 2566749463 EngOilLev 14828;
BA_ "CI_SigName" SG_ 2566749463 EngOilLev "Engine oil level";
BA_ "GenSigTimeoutTime_FMS4" SG_ 2566749463 EngOilLev 5000;
BA_ "GenSigTimeoutTime_PCM" SG_ 2566749463 EngOilLev 5000;
BA_ "GenSigTimeoutTime_SGW__" SG_ 2566749463 EngOilLev 5000;
BA_ "CI_ParId" SG_ 2566749463 EngCoolLev "FMS014";
BA_ "CI_SigId" SG_ 2566749463 EngCoolLev 14829;
BA_ "CI_SigName" SG_ 2566749463 EngCoolLev "Engine coolant level";
BA_ "GenSigTimeoutTime_FMS4" SG_ 2566749463 EngCoolLev 5000;
BA_ "GenSigTimeoutTime_PCM" SG_ 2566749463 EngCoolLev 5000;
BA_ "GenSigTimeoutTime_SGW__" SG_ 2566749463 EngCoolLev 5000;
BA_ "CI_ParId" SG_ 2566749463 SteerFluidLev "FMS015";
BA_ "CI_SigId" SG_ 2566749463 SteerFluidLev 14830;
BA_ "CI_SigName" SG_ 2566749463 SteerFluidLev "Steering fluid level";
BA_ "GenSigTimeoutTime_FMS4" SG_ 2566749463 SteerFluidLev 5000;
BA_ "GenSigTimeoutTime_PCM" SG_ 2566749463 SteerFluidLev 5000;
BA_ "GenSigTimeoutTime_SGW__" SG_ 2566749463 SteerFluidLev 5000;
BA_ "CI_ParId" SG_ 2566749463 SteerFail "FMS001";
BA_ "CI_SigId" SG_ 2566749463 SteerFail 14831;
BA_ "CI_SigName" SG_ 2566749463 SteerFail "Steering failure";
BA_ "GenSigTimeoutTime_FMS4" SG_ 2566749463 SteerFail 5000;
BA_ "GenSigTimeoutTime_PCM" SG_ 2566749463 SteerFail 5000;
BA_ "GenSigTimeoutTime_SGW__" SG_ 2566749463 SteerFail 5000;
BA_ "CI_ParId" SG_ 2566749463 HtCtrl "FMS002";
BA_ "CI_SigId" SG_ 2566749463 HtCtrl 14832;
BA_ "CI_SigName" SG_ 2566749463 HtCtrl "Height Control (Levelling)";
BA_ "GenSigTimeoutTime_FMS4" SG_ 2566749463 HtCtrl 5000;
BA_ "GenSigTimeoutTime_PCM" SG_ 2566749463 HtCtrl 5000;
BA_ "GenSigTimeoutTime_SGW__" SG_ 2566749463 HtCtrl 5000;
BA_ "CI_ParId" SG_ 2566749463 Ret "FMS003";
BA_ "CI_SigId" SG_ 2566749463 Ret 14833;
BA_ "CI_SigName" SG_ 2566749463 Ret "Retarder";
BA_ "GenSigTimeoutTime_FMS4" SG_ 2566749463 Ret 5000;
BA_ "GenSigTimeoutTime_PCM" SG_ 2566749463 Ret 5000;
BA_ "GenSigTimeoutTime_SGW__" SG_ 2566749463 Ret 5000;
BA_ "CI_ParId" SG_ 2566749463 EngEmisSysFailMil "FMS004";
BA_ "CI_SigId" SG_ 2566749463 EngEmisSysFailMil 14834;
BA_ "CI_SigName" SG_ 2566749463 EngEmisSysFailMil "Engine Emission system failure -Mil indicator";
BA_ "GenSigTimeoutTime_FMS4" SG_ 2566749463 EngEmisSysFailMil 5000;
BA_ "GenSigTimeoutTime_PCM" SG_ 2566749463 EngEmisSysFailMil 5000;
BA_ "GenSigTimeoutTime_SGW__" SG_ 2566749463 EngEmisSysFailMil 5000;
BA_ "CI_ParId" SG_ 2566749463 EscInd "FMS005";
BA_ "CI_SigId" SG_ 2566749463 EscInd 14835;
BA_ "CI_SigName" SG_ 2566749463 EscInd "ESC indication";
BA_ "GenSigTimeoutTime_FMS4" SG_ 2566749463 EscInd 5000;
BA_ "GenSigTimeoutTime_PCM" SG_ 2566749463 EscInd 5000;
BA_ "GenSigTimeoutTime_SGW__" SG_ 2566749463 EscInd 5000;
BA_ "CI_ParId" SG_ 2566749463 BrkLight "FMS006";
BA_ "CI_SigId" SG_ 2566749463 BrkLight 14836;
BA_ "CI_SigName" SG_ 2566749463 BrkLight "Brake lights";
BA_ "GenSigTimeoutTime_FMS4" SG_ 2566749463 BrkLight 5000;
BA_ "GenSigTimeoutTime_PCM" SG_ 2566749463 BrkLight 5000;
BA_ "GenSigTimeoutTime_SGW__" SG_ 2566749463 BrkLight 5000;
BA_ "CI_ParId" SG_ 2566749463 Artic "FMS007";
BA_ "CI_SigId" SG_ 2566749463 Artic 14837;
BA_ "CI_SigName" SG_ 2566749463 Artic "Articulation";
BA_ "GenSigTimeoutTime_FMS4" SG_ 2566749463 Artic 5000;
BA_ "GenSigTimeoutTime_PCM" SG_ 2566749463 Artic 5000;
BA_ "GenSigTimeoutTime_SGW__" SG_ 2566749463 Artic 5000;
BA_ "CI_ParId" SG_ 2566749463 StopReq "FMS008";
BA_ "CI_SigId" SG_ 2566749463 StopReq 14838;
BA_ "CI_SigName" SG_ 2566749463 StopReq "Stop Request";
BA_ "GenSigTimeoutTime_FMS4" SG_ 2566749463 StopReq 5000;
BA_ "GenSigTimeoutTime_PCM" SG_ 2566749463 StopReq 5000;
BA_ "GenSigTimeoutTime_SGW__" SG_ 2566749463 StopReq 5000;
BA_ "CI_ParId" SG_ 2566749463 PramReq "FMS009";
BA_ "CI_SigId" SG_ 2566749463 PramReq 14839;
BA_ "CI_SigName" SG_ 2566749463 PramReq "Pram request";
BA_ "GenSigTimeoutTime_FMS4" SG_ 2566749463 PramReq 5000;
BA_ "GenSigTimeoutTime_PCM" SG_ 2566749463 PramReq 5000;
BA_ "GenSigTimeoutTime_SGW__" SG_ 2566749463 PramReq 5000;
BA_ "CI_ParId" SG_ 2566749463 BusStopBrk "FMS010";
BA_ "CI_SigId" SG_ 2566749463 BusStopBrk 14840;
BA_ "CI_SigName" SG_ 2566749463 BusStopBrk "Bus stop brake";
BA_ "GenSigTimeoutTime_FMS4" SG_ 2566749463 BusStopBrk 5000;
BA_ "GenSigTimeoutTime_PCM" SG_ 2566749463 BusStopBrk 5000;
BA_ "GenSigTimeoutTime_SGW__" SG_ 2566749463 BusStopBrk 5000;
BA_ "CI_ParId" SG_ 2566749463 AdblueLev "FMS011";
BA_ "CI_SigId" SG_ 2566749463 AdblueLev 14841;
BA_ "CI_SigName" SG_ 2566749463 AdblueLev "AdBlue level";
BA_ "GenSigTimeoutTime_FMS4" SG_ 2566749463 AdblueLev 5000;
BA_ "GenSigTimeoutTime_PCM" SG_ 2566749463 AdblueLev 5000;
BA_ "GenSigTimeoutTime_SGW__" SG_ 2566749463 AdblueLev 5000;
BA_ "CI_ParId" SG_ 2566749463 Raising "FMS012";
BA_ "CI_SigId" SG_ 2566749463 Raising 14842;
BA_ "CI_SigName" SG_ 2566749463 Raising "Raising";
BA_ "GenSigTimeoutTime_FMS4" SG_ 2566749463 Raising 5000;
BA_ "GenSigTimeoutTime_PCM" SG_ 2566749463 Raising 5000;
BA_ "GenSigTimeoutTime_SGW__" SG_ 2566749463 Raising 5000;
BA_ "CI_ParId" SG_ 2566749463 Low "FMS013";
BA_ "CI_SigId" SG_ 2566749463 Low 14843;
BA_ "CI_SigName" SG_ 2566749463 Low "Lowering";
BA_ "GenSigTimeoutTime_FMS4" SG_ 2566749463 Low 5000;
BA_ "GenSigTimeoutTime_PCM" SG_ 2566749463 Low 5000;
BA_ "GenSigTimeoutTime_SGW__" SG_ 2566749463 Low 5000;
BA_ "CI_ParId" SG_ 2566749463 Kneel "FMS014";
BA_ "CI_SigId" SG_ 2566749463 Kneel 14844;
BA_ "CI_SigName" SG_ 2566749463 Kneel "Kneeling";
BA_ "GenSigTimeoutTime_FMS4" SG_ 2566749463 Kneel 5000;
BA_ "GenSigTimeoutTime_PCM" SG_ 2566749463 Kneel 5000;
BA_ "GenSigTimeoutTime_SGW__" SG_ 2566749463 Kneel 5000;
BA_ "CI_ParId" SG_ 2566749463 EngCompTemp "FMS015";
BA_ "CI_SigId" SG_ 2566749463 EngCompTemp 14845;
BA_ "CI_SigName" SG_ 2566749463 EngCompTemp "Engine compartment temperature";
BA_ "GenSigTimeoutTime_FMS4" SG_ 2566749463 EngCompTemp 5000;
BA_ "GenSigTimeoutTime_PCM" SG_ 2566749463 EngCompTemp 5000;
BA_ "GenSigTimeoutTime_SGW__" SG_ 2566749463 EngCompTemp 5000;
BA_ "CI_ParId" SG_ 2566749463 AuxAirPrs "FMS001";
BA_ "CI_SigId" SG_ 2566749463 AuxAirPrs 14846;
BA_ "CI_SigName" SG_ 2566749463 AuxAirPrs "Auxiliary air pressure";
BA_ "GenSigTimeoutTime_FMS4" SG_ 2566749463 AuxAirPrs 5000;
BA_ "GenSigTimeoutTime_PCM" SG_ 2566749463 AuxAirPrs 5000;
BA_ "GenSigTimeoutTime_SGW__" SG_ 2566749463 AuxAirPrs 5000;
BA_ "CI_ParId" SG_ 2566749463 AirFiltClog "FMS002";
BA_ "CI_SigId" SG_ 2566749463 AirFiltClog 14847;
BA_ "CI_SigName" SG_ 2566749463 AirFiltClog "Air filter clogged";
BA_ "GenSigTimeoutTime_FMS4" SG_ 2566749463 AirFiltClog 5000;
BA_ "GenSigTimeoutTime_PCM" SG_ 2566749463 AirFiltClog 5000;
BA_ "GenSigTimeoutTime_SGW__" SG_ 2566749463 AirFiltClog 5000;
BA_ "CI_ParId" SG_ 2566749463 FuelFiltDiffPrs "FMS003";
BA_ "CI_SigId" SG_ 2566749463 FuelFiltDiffPrs 14848;
BA_ "CI_SigName" SG_ 2566749463 FuelFiltDiffPrs "Fuel filter differential pressure";
BA_ "GenSigTimeoutTime_FMS4" SG_ 2566749463 FuelFiltDiffPrs 5000;
BA_ "GenSigTimeoutTime_PCM" SG_ 2566749463 FuelFiltDiffPrs 5000;
BA_ "GenSigTimeoutTime_SGW__" SG_ 2566749463 FuelFiltDiffPrs 5000;
BA_ "CI_ParId" SG_ 2566749463 SeatBelt "FMS004";
BA_ "CI_SigId" SG_ 2566749463 SeatBelt 14849;
BA_ "CI_SigName" SG_ 2566749463 SeatBelt "Seat belt";
BA_ "GenSigTimeoutTime_FMS4" SG_ 2566749463 SeatBelt 5000;
BA_ "GenSigTimeoutTime_PCM" SG_ 2566749463 SeatBelt 5000;
BA_ "GenSigTimeoutTime_SGW__" SG_ 2566749463 SeatBelt 5000;
BA_ "CI_ParId" SG_ 2566749463 Ebs "FMS005";
BA_ "CI_SigId" SG_ 2566749463 Ebs 14850;
BA_ "CI_SigName" SG_ 2566749463 Ebs "EBS";
BA_ "GenSigTimeoutTime_FMS4" SG_ 2566749463 Ebs 5000;
BA_ "GenSigTimeoutTime_PCM" SG_ 2566749463 Ebs 5000;
BA_ "GenSigTimeoutTime_SGW__" SG_ 2566749463 Ebs 5000;
BA_ "CI_ParId" SG_ 2566749463 LaneDepInd "FMS006";
BA_ "CI_SigId" SG_ 2566749463 LaneDepInd 14851;
BA_ "CI_SigName" SG_ 2566749463 LaneDepInd "Lane departure indication";
BA_ "GenSigTimeoutTime_FMS4" SG_ 2566749463 LaneDepInd 5000;
BA_ "GenSigTimeoutTime_PCM" SG_ 2566749463 LaneDepInd 5000;
BA_ "GenSigTimeoutTime_SGW__" SG_ 2566749463 LaneDepInd 5000;
BA_ "CI_ParId" SG_ 2566749463 Aebs "FMS007";
BA_ "CI_SigId" SG_ 2566749463 Aebs 14852;
BA_ "CI_SigName" SG_ 2566749463 Aebs "Advanced emergency braking system";
BA_ "GenSigTimeoutTime_FMS4" SG_ 2566749463 Aebs 5000;
BA_ "GenSigTimeoutTime_PCM" SG_ 2566749463 Aebs 5000;
BA_ "GenSigTimeoutTime_SGW__" SG_ 2566749463 Aebs 5000;
BA_ "CI_ParId" SG_ 2566749463 Acc "FMS008";
BA_ "CI_SigId" SG_ 2566749463 Acc 14853;
BA_ "CI_SigName" SG_ 2566749463 Acc "ACC";
BA_ "GenSigTimeoutTime_FMS4" SG_ 2566749463 Acc 5000;
BA_ "GenSigTimeoutTime_PCM" SG_ 2566749463 Acc 5000;
BA_ "GenSigTimeoutTime_SGW__" SG_ 2566749463 Acc 5000;
BA_ "CI_ParId" SG_ 2566749463 TrailConn "FMS009";
BA_ "CI_SigId" SG_ 2566749463 TrailConn 14854;
BA_ "CI_SigName" SG_ 2566749463 TrailConn "Trailer connected";
BA_ "GenSigTimeoutTime_FMS4" SG_ 2566749463 TrailConn 5000;
BA_ "GenSigTimeoutTime_PCM" SG_ 2566749463 TrailConn 5000;
BA_ "GenSigTimeoutTime_SGW__" SG_ 2566749463 TrailConn 5000;
BA_ "CI_ParId" SG_ 2566749463 AbsTrail12 "FMS010";
BA_ "CI_SigId" SG_ 2566749463 AbsTrail12 14855;
BA_ "CI_SigName" SG_ 2566749463 AbsTrail12 "ABS Trailer 1,2";
BA_ "GenSigTimeoutTime_FMS4" SG_ 2566749463 AbsTrail12 5000;
BA_ "GenSigTimeoutTime_PCM" SG_ 2566749463 AbsTrail12 5000;
BA_ "GenSigTimeoutTime_SGW__" SG_ 2566749463 AbsTrail12 5000;
BA_ "CI_ParId" SG_ 2566749463 Airbag "FMS011";
BA_ "CI_SigId" SG_ 2566749463 Airbag 14856;
BA_ "CI_SigName" SG_ 2566749463 Airbag "Airbag";
BA_ "GenSigTimeoutTime_FMS4" SG_ 2566749463 Airbag 5000;
BA_ "GenSigTimeoutTime_PCM" SG_ 2566749463 Airbag 5000;
BA_ "GenSigTimeoutTime_SGW__" SG_ 2566749463 Airbag 5000;
BA_ "CI_ParId" SG_ 2566749463 EbsTrail12 "FMS012";
BA_ "CI_SigId" SG_ 2566749463 EbsTrail12 14857;
BA_ "CI_SigName" SG_ 2566749463 EbsTrail12 "EBS Trailer 1,2";
BA_ "GenSigTimeoutTime_FMS4" SG_ 2566749463 EbsTrail12 5000;
BA_ "GenSigTimeoutTime_PCM" SG_ 2566749463 EbsTrail12 5000;
BA_ "GenSigTimeoutTime_SGW__" SG_ 2566749463 EbsTrail12 5000;
BA_ "CI_ParId" SG_ 2566749463 TcoInd "FMS013";
BA_ "CI_SigId" SG_ 2566749463 TcoInd 14858;
BA_ "CI_SigName" SG_ 2566749463 TcoInd "Tachograph indication";
BA_ "GenSigTimeoutTime_FMS4" SG_ 2566749463 TcoInd 5000;
BA_ "GenSigTimeoutTime_PCM" SG_ 2566749463 TcoInd 5000;
BA_ "GenSigTimeoutTime_SGW__" SG_ 2566749463 TcoInd 5000;
BA_ "CI_ParId" SG_ 2566749463 EscSwdOff "FMS014";
BA_ "CI_SigId" SG_ 2566749463 EscSwdOff 14859;
BA_ "CI_SigName" SG_ 2566749463 EscSwdOff "ESC switched off";
BA_ "GenSigTimeoutTime_FMS4" SG_ 2566749463 EscSwdOff 5000;
BA_ "GenSigTimeoutTime_PCM" SG_ 2566749463 EscSwdOff 5000;
BA_ "GenSigTimeoutTime_SGW__" SG_ 2566749463 EscSwdOff 5000;
BA_ "CI_ParId" SG_ 2566749463 LdwSwdOff "FMS015";
BA_ "CI_SigId" SG_ 2566749463 LdwSwdOff 14860;
BA_ "CI_SigName" SG_ 2566749463 LdwSwdOff "Lane departure warning switched off";
BA_ "GenSigTimeoutTime_FMS4" SG_ 2566749463 LdwSwdOff 5000;
BA_ "GenSigTimeoutTime_PCM" SG_ 2566749463 LdwSwdOff 5000;
BA_ "GenSigTimeoutTime_SGW__" SG_ 2566749463 LdwSwdOff 5000;
BA_ "CI_ParId" SG_ 2566749463 EngEmisFilt "FMS001";
BA_ "CI_SigId" SG_ 2566749463 EngEmisFilt 14861;
BA_ "CI_SigName" SG_ 2566749463 EngEmisFilt "Engine emission filter (Soot Filter)";
BA_ "GenSigTimeoutTime_FMS4" SG_ 2566749463 EngEmisFilt 5000;
BA_ "GenSigTimeoutTime_PCM" SG_ 2566749463 EngEmisFilt 5000;
BA_ "GenSigTimeoutTime_SGW__" SG_ 2566749463 EngEmisFilt 5000;
BA_ "CI_ParId" SG_ 2566749463 ElMotFails "FMS002";
BA_ "CI_SigId" SG_ 2566749463 ElMotFails 14862;
BA_ "CI_SigName" SG_ 2566749463 ElMotFails "Electric motor failures";
BA_ "GenSigTimeoutTime_FMS4" SG_ 2566749463 ElMotFails 5000;
BA_ "GenSigTimeoutTime_PCM" SG_ 2566749463 ElMotFails 5000;
BA_ "GenSigTimeoutTime_SGW__" SG_ 2566749463 ElMotFails 5000;
BA_ "CI_ParId" SG_ 2566749463 AdblueTamp "FMS003";
BA_ "CI_SigId" SG_ 2566749463 AdblueTamp 14863;
BA_ "CI_SigName" SG_ 2566749463 AdblueTamp "AdBlue tampering";
BA_ "GenSigTimeoutTime_FMS4" SG_ 2566749463 AdblueTamp 5000;
BA_ "GenSigTimeoutTime_PCM" SG_ 2566749463 AdblueTamp 5000;
BA_ "GenSigTimeoutTime_SGW__" SG_ 2566749463 AdblueTamp 5000;
BA_ "CI_ParId" SG_ 2566749463 MuxSys "FMS004";
BA_ "CI_SigId" SG_ 2566749463 MuxSys 14864;
BA_ "CI_SigName" SG_ 2566749463 MuxSys "Multiplex System";
BA_ "GenSigTimeoutTime_FMS4" SG_ 2566749463 MuxSys 5000;
BA_ "GenSigTimeoutTime_PCM" SG_ 2566749463 MuxSys 5000;
BA_ "GenSigTimeoutTime_SGW__" SG_ 2566749463 MuxSys 5000;
BA_ "CI_ParId" SG_ 2566749463 BatPak "FMS005";
BA_ "CI_SigId" SG_ 2566749463 BatPak 14865;
BA_ "CI_SigName" SG_ 2566749463 BatPak "Battery pack";
BA_ "GenSigTimeoutTime_FMS4" SG_ 2566749463 BatPak 5000;
BA_ "GenSigTimeoutTime_PCM" SG_ 2566749463 BatPak 5000;
BA_ "GenSigTimeoutTime_SGW__" SG_ 2566749463 BatPak 5000;
BA_ "CI_ParId" SG_ 2566749463 highVsysCaution "FMS006";
BA_ "CI_SigId" SG_ 2566749463 highVsysCaution 14866;
BA_ "CI_SigName" SG_ 2566749463 highVsysCaution "High voltage system caution";
BA_ "GenSigTimeoutTime_FMS4" SG_ 2566749463 highVsysCaution 5000;
BA_ "GenSigTimeoutTime_PCM" SG_ 2566749463 highVsysCaution 5000;
BA_ "GenSigTimeoutTime_SGW__" SG_ 2566749463 highVsysCaution 5000;
BA_ "CI_ParId" SG_ 2566749463 BatPakTemp "FMS007";
BA_ "CI_SigId" SG_ 2566749463 BatPakTemp 14867;
BA_ "CI_SigName" SG_ 2566749463 BatPakTemp "Battery pack temperature ";
BA_ "GenSigTimeoutTime_FMS4" SG_ 2566749463 BatPakTemp 5000;
BA_ "GenSigTimeoutTime_PCM" SG_ 2566749463 BatPakTemp 5000;
BA_ "GenSigTimeoutTime_SGW__" SG_ 2566749463 BatPakTemp 5000;
BA_ "CI_ParId" SG_ 2566749463 LimPerfElMot "FMS008";
BA_ "CI_SigId" SG_ 2566749463 LimPerfElMot 14868;
BA_ "CI_SigName" SG_ 2566749463 LimPerfElMot "Limited performance electric motor";
BA_ "GenSigTimeoutTime_FMS4" SG_ 2566749463 LimPerfElMot 5000;
BA_ "GenSigTimeoutTime_PCM" SG_ 2566749463 LimPerfElMot 5000;
BA_ "GenSigTimeoutTime_SGW__" SG_ 2566749463 LimPerfElMot 5000;
BA_ "CI_ParId" SG_ 2566749463 BatPakCool "FMS009";
BA_ "CI_SigId" SG_ 2566749463 BatPakCool 14869;
BA_ "CI_SigName" SG_ 2566749463 BatPakCool "Battery pack cooling";
BA_ "GenSigTimeoutTime_FMS4" SG_ 2566749463 BatPakCool 5000;
BA_ "GenSigTimeoutTime_PCM" SG_ 2566749463 BatPakCool 5000;
BA_ "GenSigTimeoutTime_SGW__" SG_ 2566749463 BatPakCool 5000;
BA_ "CI_ParId" SG_ 2566884426 DeferredDataReq "IB074";
BA_ "CI_SigId" SG_ 2566884426 DeferredDataReq 1329;
BA_ "CI_SigName" SG_ 2566884426 DeferredDataReq "Deferred data request";
BA_ "GenSigTimeoutTime_CAID" SG_ 2566884426 DeferredDataReq 5000;
BA_ "GenSigTimeoutTime_SGW2" SG_ 2566884426 DeferredDataReq 5000;
BA_ "GenSigTimeoutTime_SGW_" SG_ 2566884426 DeferredDataReq 5000;
BA_ "CI_ParId" SG_ 2566884426 EcuIdReq "IB075";
BA_ "CI_SigId" SG_ 2566884426 EcuIdReq 1330;
BA_ "CI_SigName" SG_ 2566884426 EcuIdReq "ECU identification request";
BA_ "GenSigTimeoutTime_CAID" SG_ 2566884426 EcuIdReq 5000;
BA_ "GenSigTimeoutTime_SGW2" SG_ 2566884426 EcuIdReq 5000;
BA_ "GenSigTimeoutTime_SGW_" SG_ 2566884426 EcuIdReq 5000;
BA_ "CI_ParId" SG_ 2566884426 CompIdReq "IB076";
BA_ "CI_SigId" SG_ 2566884426 CompIdReq 1331;
BA_ "CI_SigName" SG_ 2566884426 CompIdReq "Component identification request";
BA_ "GenSigTimeoutTime_CAID" SG_ 2566884426 CompIdReq 5000;
BA_ "GenSigTimeoutTime_SGW2" SG_ 2566884426 CompIdReq 5000;
BA_ "GenSigTimeoutTime_SGW_" SG_ 2566884426 CompIdReq 5000;
BA_ "CI_ParId" SG_ 2566884426 SwIdReq "IB077";
BA_ "CI_SigId" SG_ 2566884426 SwIdReq 1332;
BA_ "CI_SigName" SG_ 2566884426 SwIdReq "Software identification request";
BA_ "GenSigTimeoutTime_CAID" SG_ 2566884426 SwIdReq 5000;
BA_ "GenSigTimeoutTime_SGW2" SG_ 2566884426 SwIdReq 5000;
BA_ "GenSigTimeoutTime_SGW_" SG_ 2566884426 SwIdReq 5000;
BA_ "CI_ParId" SG_ 2566884426 AllTheDataRemoval "IB078";
BA_ "CI_SigId" SG_ 2566884426 AllTheDataRemoval 1333;
BA_ "CI_SigName" SG_ 2566884426 AllTheDataRemoval "All the data removal";
BA_ "GenSigTimeoutTime_CAID" SG_ 2566884426 AllTheDataRemoval 5000;
BA_ "GenSigTimeoutTime_SGW2" SG_ 2566884426 AllTheDataRemoval 5000;
BA_ "GenSigTimeoutTime_SGW_" SG_ 2566884426 AllTheDataRemoval 5000;
BA_ "CI_ParId" SG_ 2566877568 FCU2_8_H2LeakLamp "IB3001";
BA_ "CI_SigId" SG_ 2566877568 FCU2_8_H2LeakLamp 18905;
BA_ "CI_SigName" SG_ 2566877568 FCU2_8_H2LeakLamp "FCU2_8_H2LeakLamp";
BA_ "GenSigTimeoutTime_PCM" SG_ 2566877568 FCU2_8_H2LeakLamp 500;
BA_ "GenSigTimeoutTime_SGW__" SG_ 2566877568 FCU2_8_H2LeakLamp 500;
BA_ "SigType" SG_ 2566877568 FCU2_8_H2LeakLamp 4;
BA_ "CI_ParId" SG_ 2566877568 FCU2_5_H2FaultLamp "IB3002";
BA_ "CI_SigId" SG_ 2566877568 FCU2_5_H2FaultLamp 18906;
BA_ "CI_SigName" SG_ 2566877568 FCU2_5_H2FaultLamp "FCU2_5_H2FaultLamp";
BA_ "GenSigTimeoutTime_PCM" SG_ 2566877568 FCU2_5_H2FaultLamp 500;
BA_ "GenSigTimeoutTime_SGW__" SG_ 2566877568 FCU2_5_H2FaultLamp 500;
BA_ "CI_ParId" SG_ 2566877568 FCU2_HighvoltageInterlockReactRe "IB3003";
BA_ "CI_SigId" SG_ 2566877568 FCU2_HighvoltageInterlockReactRe 18907;
BA_ "CI_SigName" SG_ 2566877568 FCU2_HighvoltageInterlockReactRe "FCU2_HighvoltageInterlockReactRequest";
BA_ "GenSigTimeoutTime_PCM" SG_ 2566877568 FCU2_HighvoltageInterlockReactRe 500;
BA_ "GenSigTimeoutTime_SGW__" SG_ 2566877568 FCU2_HighvoltageInterlockReactRe 500;
BA_ "CI_ParId" SG_ 2566877568 FCU2_H2TankValveEmergencyClose "IB3004";
BA_ "CI_SigId" SG_ 2566877568 FCU2_H2TankValveEmergencyClose 18908;
BA_ "CI_SigName" SG_ 2566877568 FCU2_H2TankValveEmergencyClose "FCU2_H2TankValveEmergencyClose";
BA_ "GenSigTimeoutTime_PCM" SG_ 2566877568 FCU2_H2TankValveEmergencyClose 500;
BA_ "GenSigTimeoutTime_SGW__" SG_ 2566877568 FCU2_H2TankValveEmergencyClose 500;
BA_ "CI_ParId" SG_ 2566877568 FuelCellSwitchONOFFinputVCU "IB3005";
BA_ "CI_SigId" SG_ 2566877568 FuelCellSwitchONOFFinputVCU 18909;
BA_ "CI_SigName" SG_ 2566877568 FuelCellSwitchONOFFinputVCU "Fuel Cell Switch ON/OFF (input VCU)";
BA_ "GenSigTimeoutTime_PCM" SG_ 2566877568 FuelCellSwitchONOFFinputVCU 500;
BA_ "GenSigTimeoutTime_SGW__" SG_ 2566877568 FuelCellSwitchONOFFinputVCU 500;
BA_ "CI_ParId" SG_ 2566877568 VCU_FuelcellCoolantLevelLow "IB3006";
BA_ "CI_SigId" SG_ 2566877568 VCU_FuelcellCoolantLevelLow 18910;
BA_ "CI_SigName" SG_ 2566877568 VCU_FuelcellCoolantLevelLow "VCU_FuelcellCoolantLevelLow";
BA_ "GenSigTimeoutTime_PCM" SG_ 2566877568 VCU_FuelcellCoolantLevelLow 500;
BA_ "GenSigTimeoutTime_SGW__" SG_ 2566877568 VCU_FuelcellCoolantLevelLow 500;
BA_ "CI_ParId" SG_ 2566877568 FCU2_5_FuelcellStartup "IB3007";
BA_ "CI_SigId" SG_ 2566877568 FCU2_5_FuelcellStartup 18911;
BA_ "CI_SigName" SG_ 2566877568 FCU2_5_FuelcellStartup "FCU2_5_FuelcellStartup";
BA_ "GenSigTimeoutTime_PCM" SG_ 2566877568 FCU2_5_FuelcellStartup 500;
BA_ "GenSigTimeoutTime_SGW__" SG_ 2566877568 FCU2_5_FuelcellStartup 500;
BA_ "SigType" SG_ 2566877568 FCU2_5_FuelcellStartup 4;
BA_ "CI_ParId" SG_ 2566877568 FCU2_5_FuelcellLoadPermmit "IB3008";
BA_ "CI_SigId" SG_ 2566877568 FCU2_5_FuelcellLoadPermmit 18912;
BA_ "CI_SigName" SG_ 2566877568 FCU2_5_FuelcellLoadPermmit "FCU2_5_FuelcellLoadPermmit";
BA_ "GenSigTimeoutTime_PCM" SG_ 2566877568 FCU2_5_FuelcellLoadPermmit 500;
BA_ "GenSigTimeoutTime_SGW__" SG_ 2566877568 FCU2_5_FuelcellLoadPermmit 500;
BA_ "CI_ParId" SG_ 2566877568 FCU2_5_FuelcellShutdown "IB3009";
BA_ "CI_SigId" SG_ 2566877568 FCU2_5_FuelcellShutdown 18913;
BA_ "CI_SigName" SG_ 2566877568 FCU2_5_FuelcellShutdown "FCU2_5_FuelcellShutdown";
BA_ "GenSigTimeoutTime_PCM" SG_ 2566877568 FCU2_5_FuelcellShutdown 500;
BA_ "GenSigTimeoutTime_SGW__" SG_ 2566877568 FCU2_5_FuelcellShutdown 500;
BA_ "SigType" SG_ 2566877568 FCU2_5_FuelcellShutdown 4;
BA_ "CI_ParId" SG_ 2566877568 FCU2_5_FuelcellFault "IB3010";
BA_ "CI_SigId" SG_ 2566877568 FCU2_5_FuelcellFault 18914;
BA_ "CI_SigName" SG_ 2566877568 FCU2_5_FuelcellFault "FCU2_5_FuelcellFault";
BA_ "GenSigTimeoutTime_PCM" SG_ 2566877568 FCU2_5_FuelcellFault 500;
BA_ "GenSigTimeoutTime_SGW__" SG_ 2566877568 FCU2_5_FuelcellFault 500;
BA_ "CI_ParId" SG_ 2566877568 FCU2_7_FuelcellStopImpossible "IB3011";
BA_ "CI_SigId" SG_ 2566877568 FCU2_7_FuelcellStopImpossible 18915;
BA_ "CI_SigName" SG_ 2566877568 FCU2_7_FuelcellStopImpossible "FCU2_7_FuelcellStopImpossible";
BA_ "GenSigTimeoutTime_PCM" SG_ 2566877568 FCU2_7_FuelcellStopImpossible 500;
BA_ "GenSigTimeoutTime_SGW__" SG_ 2566877568 FCU2_7_FuelcellStopImpossible 500;
BA_ "SigType" SG_ 2566877568 FCU2_7_FuelcellStopImpossible 4;
BA_ "CI_ParId" SG_ 2566877568 FCU2_7_FuelcellStopState "IB3012";
BA_ "CI_SigId" SG_ 2566877568 FCU2_7_FuelcellStopState 18916;
BA_ "CI_SigName" SG_ 2566877568 FCU2_7_FuelcellStopState "FCU2_7_FuelcellStopState";
BA_ "GenSigTimeoutTime_PCM" SG_ 2566877568 FCU2_7_FuelcellStopState 500;
BA_ "GenSigTimeoutTime_SGW__" SG_ 2566877568 FCU2_7_FuelcellStopState 500;
BA_ "SigType" SG_ 2566877568 FCU2_7_FuelcellStopState 4;
BA_ "CI_ParId" SG_ 2566877568 VCU_HighvoltageFaultEmergencyShu "IB3013";
BA_ "CI_SigId" SG_ 2566877568 VCU_HighvoltageFaultEmergencyShu 18917;
BA_ "CI_SigName" SG_ 2566877568 VCU_HighvoltageFaultEmergencyShu "VCU_HighvoltageFaultEmergencyShutdownRequest_Fuelcell1";
BA_ "GenSigTimeoutTime_PCM" SG_ 2566877568 VCU_HighvoltageFaultEmergencyShu 500;
BA_ "GenSigTimeoutTime_SGW__" SG_ 2566877568 VCU_HighvoltageFaultEmergencyShu 500;
BA_ "CI_ParId" SG_ 2566877568 VCU_TankCloseEmergencyShutdownRe "IB3014";
BA_ "CI_SigId" SG_ 2566877568 VCU_TankCloseEmergencyShutdownRe 18918;
BA_ "CI_SigName" SG_ 2566877568 VCU_TankCloseEmergencyShutdownRe "VCU_TankCloseEmergencyShutdownRequest_Fuelcell1";
BA_ "GenSigTimeoutTime_PCM" SG_ 2566877568 VCU_TankCloseEmergencyShutdownRe 500;
BA_ "GenSigTimeoutTime_SGW__" SG_ 2566877568 VCU_TankCloseEmergencyShutdownRe 500;
BA_ "CI_ParId" SG_ 2566877568 Fcactivationdeactivationstatusfo "IB3015";
BA_ "CI_SigId" SG_ 2566877568 Fcactivationdeactivationstatusfo 18919;
BA_ "CI_SigName" SG_ 2566877568 Fcactivationdeactivationstatusfo "FC activation / deactivation status for dashboard displaying";
BA_ "GenSigTimeoutTime_PCM" SG_ 2566877568 Fcactivationdeactivationstatusfo 500;
BA_ "GenSigTimeoutTime_SGW__" SG_ 2566877568 Fcactivationdeactivationstatusfo 500;
BA_ "SigType" SG_ 2566877568 Fcactivationdeactivationstatusfo 4;
BA_ "CI_ParId" SG_ 2566877568 H2ConctValExc3Pc_AwlR134 "IB3016";
BA_ "CI_SigId" SG_ 2566877568 H2ConctValExc3Pc_AwlR134 18920;
BA_ "CI_SigName" SG_ 2566877568 H2ConctValExc3Pc_AwlR134 "H2 concentration value exceeding 3% (Amber Warning Lamp R134)";
BA_ "GenSigTimeoutTime_PCM" SG_ 2566877568 H2ConctValExc3Pc_AwlR134 500;
BA_ "GenSigTimeoutTime_SGW__" SG_ 2566877568 H2ConctValExc3Pc_AwlR134 500;
BA_ "CI_ParId" SG_ 2566877568 H2ConctValExc4Pc_RsllR134 "IB3017";
BA_ "CI_SigId" SG_ 2566877568 H2ConctValExc4Pc_RsllR134 18921;
BA_ "CI_SigName" SG_ 2566877568 H2ConctValExc4Pc_RsllR134 "H2 concentration value exceeding 4% (Red Stop Lamp R134)";
BA_ "GenSigTimeoutTime_PCM" SG_ 2566877568 H2ConctValExc4Pc_RsllR134 500;
BA_ "GenSigTimeoutTime_SGW__" SG_ 2566877568 H2ConctValExc4Pc_RsllR134 500;
BA_ "CI_ParId" SG_ 2566877568 H2sensor1leakagestatus "IB3018";
BA_ "CI_SigId" SG_ 2566877568 H2sensor1leakagestatus 18922;
BA_ "CI_SigName" SG_ 2566877568 H2sensor1leakagestatus "H2 sensor 1 leakage status";
BA_ "GenSigTimeoutTime_PCM" SG_ 2566877568 H2sensor1leakagestatus 500;
BA_ "GenSigTimeoutTime_SGW__" SG_ 2566877568 H2sensor1leakagestatus 500;
BA_ "CI_ParId" SG_ 2566877568 H2sensor2leakagestatus "IB3019";
BA_ "CI_SigId" SG_ 2566877568 H2sensor2leakagestatus 18923;
BA_ "CI_SigName" SG_ 2566877568 H2sensor2leakagestatus "H2 sensor 2 leakage status";
BA_ "GenSigTimeoutTime_PCM" SG_ 2566877568 H2sensor2leakagestatus 500;
BA_ "GenSigTimeoutTime_SGW__" SG_ 2566877568 H2sensor2leakagestatus 500;
BA_ "CI_ParId" SG_ 2566877568 H2sensor3leakagestatus "IB3020";
BA_ "CI_SigId" SG_ 2566877568 H2sensor3leakagestatus 18924;
BA_ "CI_SigName" SG_ 2566877568 H2sensor3leakagestatus "H2 sensor 3 leakage status";
BA_ "GenSigTimeoutTime_PCM" SG_ 2566877568 H2sensor3leakagestatus 500;
BA_ "GenSigTimeoutTime_SGW__" SG_ 2566877568 H2sensor3leakagestatus 500;
BA_ "CI_ParId" SG_ 2566877568 H2sensor4leakagestatus "IB3021";
BA_ "CI_SigId" SG_ 2566877568 H2sensor4leakagestatus 18925;
BA_ "CI_SigName" SG_ 2566877568 H2sensor4leakagestatus "H2 sensor 4 leakage status";
BA_ "GenSigTimeoutTime_PCM" SG_ 2566877568 H2sensor4leakagestatus 500;
BA_ "GenSigTimeoutTime_SGW__" SG_ 2566877568 H2sensor4leakagestatus 500;
BA_ "CI_ParId" SG_ 2566877568 FuelCellstatusfromSupervisorside "IB3022";
BA_ "CI_SigId" SG_ 2566877568 FuelCellstatusfromSupervisorside 18926;
BA_ "CI_SigName" SG_ 2566877568 FuelCellstatusfromSupervisorside "Fuel Cell status (from Supervisor side)";
BA_ "GenSigTimeoutTime_PCM" SG_ 2566877568 FuelCellstatusfromSupervisorside 500;
BA_ "GenSigTimeoutTime_SGW__" SG_ 2566877568 FuelCellstatusfromSupervisorside 500;
BA_ "CI_ParId" SG_ 2566877568 H2Circuitstatus "IB3023";
BA_ "CI_SigId" SG_ 2566877568 H2Circuitstatus 18927;
BA_ "CI_SigName" SG_ 2566877568 H2Circuitstatus "H2 Circuit status";
BA_ "GenSigTimeoutTime_PCM" SG_ 2566877568 H2Circuitstatus 500;
BA_ "GenSigTimeoutTime_SGW__" SG_ 2566877568 H2Circuitstatus 500;
BA_ "CI_ParId" SG_ 2566877568 Limphomemodeoverridemodestatus "IB3024";
BA_ "CI_SigId" SG_ 2566877568 Limphomemodeoverridemodestatus 18928;
BA_ "CI_SigName" SG_ 2566877568 Limphomemodeoverridemodestatus "Limp home mode / override mode status";
BA_ "GenSigTimeoutTime_PCM" SG_ 2566877568 Limphomemodeoverridemodestatus 500;
BA_ "GenSigTimeoutTime_SGW__" SG_ 2566877568 Limphomemodeoverridemodestatus 500;
BA_ "CI_ParId" SG_ 2566877568 H2CircuitFautRSL "IB3025";
BA_ "CI_SigId" SG_ 2566877568 H2CircuitFautRSL 18929;
BA_ "CI_SigName" SG_ 2566877568 H2CircuitFautRSL "H2 Circuit Faut (RSL)";
BA_ "GenSigTimeoutTime_PCM" SG_ 2566877568 H2CircuitFautRSL 500;
BA_ "GenSigTimeoutTime_SGW__" SG_ 2566877568 H2CircuitFautRSL 500;
BA_ "CI_ParId" SG_ 2566877568 H2circuitFaultAWL "IB3026";
BA_ "CI_SigId" SG_ 2566877568 H2circuitFaultAWL 18930;
BA_ "CI_SigName" SG_ 2566877568 H2circuitFaultAWL "H2 circuit Fault (AWL)";
BA_ "GenSigTimeoutTime_PCM" SG_ 2566877568 H2circuitFaultAWL 500;
BA_ "GenSigTimeoutTime_SGW__" SG_ 2566877568 H2circuitFaultAWL 500;
BA_ "CI_ParId" SG_ 2566877568 HVDCLinkStatus "IB3027";
BA_ "CI_SigId" SG_ 2566877568 HVDCLinkStatus 18931;
BA_ "CI_SigName" SG_ 2566877568 HVDCLinkStatus "HV DC Link Status";
BA_ "GenSigTimeoutTime_PCM" SG_ 2566877568 HVDCLinkStatus 500;
BA_ "GenSigTimeoutTime_SGW__" SG_ 2566877568 HVDCLinkStatus 500;
BA_ "CI_ParId" SG_ 2566877568 FCModerequestbytheSupervisor "IB3028";
BA_ "CI_SigId" SG_ 2566877568 FCModerequestbytheSupervisor 18932;
BA_ "CI_SigName" SG_ 2566877568 FCModerequestbytheSupervisor "FC Mode request (by the Supervisor)";
BA_ "GenSigTimeoutTime_PCM" SG_ 2566877568 FCModerequestbytheSupervisor 500;
BA_ "GenSigTimeoutTime_SGW__" SG_ 2566877568 FCModerequestbytheSupervisor 500;
BA_ "CI_ParId" SG_ 2566877568 NumberoftanksopenforH2Readytopro "IB3029";
BA_ "CI_SigId" SG_ 2566877568 NumberoftanksopenforH2Readytopro 18933;
BA_ "CI_SigName" SG_ 2566877568 NumberoftanksopenforH2Readytopro "Number of tanks open for H2 (Ready to provide H2 to the FC)";
BA_ "GenSigTimeoutTime_PCM" SG_ 2566877568 NumberoftanksopenforH2Readytopro 500;
BA_ "GenSigTimeoutTime_SGW__" SG_ 2566877568 NumberoftanksopenforH2Readytopro 500;
BA_ "CI_ParId" SG_ 2566877568 Fillingauthorizationduetosafetyr "IB3030";
BA_ "CI_SigId" SG_ 2566877568 Fillingauthorizationduetosafetyr 18934;
BA_ "CI_SigName" SG_ 2566877568 Fillingauthorizationduetosafetyr "Filling authorization due to safety reasons";
BA_ "GenSigTimeoutTime_PCM" SG_ 2566877568 Fillingauthorizationduetosafetyr 500;
BA_ "GenSigTimeoutTime_SGW__" SG_ 2566877568 Fillingauthorizationduetosafetyr 500;
BA_ "CI_ParId" SG_ 2566877568 FCU2_8_FuelcellConsumption "IB3031";
BA_ "CI_SigId" SG_ 2566877568 FCU2_8_FuelcellConsumption 18935;
BA_ "CI_SigName" SG_ 2566877568 FCU2_8_FuelcellConsumption "FCU2_8_FuelcellConsumption";
BA_ "GenSigTimeoutTime_PCM" SG_ 2566877568 FCU2_8_FuelcellConsumption 500;
BA_ "GenSigTimeoutTime_SGW__" SG_ 2566877568 FCU2_8_FuelcellConsumption 500;
BA_ "SigType" SG_ 2566877568 FCU2_8_FuelcellConsumption 1;
BA_ "CI_ParId" SG_ 2566877824 FCCoolanttemperaturegaugesignal "IB3032";
BA_ "CI_SigId" SG_ 2566877824 FCCoolanttemperaturegaugesignal 18937;
BA_ "CI_SigName" SG_ 2566877824 FCCoolanttemperaturegaugesignal "FC Coolant temperature gauge signal.";
BA_ "GenSigTimeoutTime_PCM" SG_ 2566877824 FCCoolanttemperaturegaugesignal 5000;
BA_ "GenSigTimeoutTime_SGW__" SG_ 2566877824 FCCoolanttemperaturegaugesignal 5000;
BA_ "CI_ParId" SG_ 2566877824 FDC1_2_FDC1CoolantTemperature "IB3033";
BA_ "CI_SigId" SG_ 2566877824 FDC1_2_FDC1CoolantTemperature 18938;
BA_ "CI_SigName" SG_ 2566877824 FDC1_2_FDC1CoolantTemperature "FDC1_2_FDC1 Coolant Temperature";
BA_ "GenSigTimeoutTime_PCM" SG_ 2566877824 FDC1_2_FDC1CoolantTemperature 5000;
BA_ "GenSigTimeoutTime_SGW__" SG_ 2566877824 FDC1_2_FDC1CoolantTemperature 5000;
BA_ "CI_ParId" SG_ 2566877824 SOCH2 "IB3034";
BA_ "CI_SigId" SG_ 2566877824 SOCH2 18939;
BA_ "CI_SigName" SG_ 2566877824 SOCH2 "SOC H2";
BA_ "GenSigTimeoutTime_PCM" SG_ 2566877824 SOCH2 5000;
BA_ "GenSigTimeoutTime_SGW__" SG_ 2566877824 SOCH2 5000;
BA_ "CI_ParId" SG_ 2566877824 FCU2_4_FuelcellNetPower "IB3035";
BA_ "CI_SigId" SG_ 2566877824 FCU2_4_FuelcellNetPower 18940;
BA_ "CI_SigName" SG_ 2566877824 FCU2_4_FuelcellNetPower "FCU2_4_FuelcellNetPower";
BA_ "GenSigTimeoutTime_PCM" SG_ 2566877824 FCU2_4_FuelcellNetPower 5000;
BA_ "GenSigTimeoutTime_SGW__" SG_ 2566877824 FCU2_4_FuelcellNetPower 5000;
BA_ "CI_ParId" SG_ 2566877824 FuelCellHoursofrunning "IB3036";
BA_ "CI_SigId" SG_ 2566877824 FuelCellHoursofrunning 18941;
BA_ "CI_SigName" SG_ 2566877824 FuelCellHoursofrunning "Fuel Cell Hours of running";
BA_ "GenSigTimeoutTime_PCM" SG_ 2566877824 FuelCellHoursofrunning 5000;
BA_ "GenSigTimeoutTime_SGW__" SG_ 2566877824 FuelCellHoursofrunning 5000;
BA_ "CI_ParId" SG_ 2566877824 AutonomyH2 "IB3037";
BA_ "CI_SigId" SG_ 2566877824 AutonomyH2 18942;
BA_ "CI_SigName" SG_ 2566877824 AutonomyH2 "Autonomy H2";
BA_ "GenSigTimeoutTime_PCM" SG_ 2566877824 AutonomyH2 5000;
BA_ "GenSigTimeoutTime_SGW__" SG_ 2566877824 AutonomyH2 5000;
BA_ "CI_ParId" SG_ 2566878080 VCU_H2HighPressureLSB "IB3038";
BA_ "CI_SigId" SG_ 2566878080 VCU_H2HighPressureLSB 18944;
BA_ "CI_SigName" SG_ 2566878080 VCU_H2HighPressureLSB "VCU_H2HighPressure (LSB)";
BA_ "GenSigTimeoutTime_PCM" SG_ 2566878080 VCU_H2HighPressureLSB 5000;
BA_ "GenSigTimeoutTime_SGW__" SG_ 2566878080 VCU_H2HighPressureLSB 5000;
BA_ "CI_ParId" SG_ 2566878080 VCU_H2HighPressureMSB "IB3039";
BA_ "CI_SigId" SG_ 2566878080 VCU_H2HighPressureMSB 18945;
BA_ "CI_SigName" SG_ 2566878080 VCU_H2HighPressureMSB "VCU_H2HighPressure (MSB)";
BA_ "GenSigTimeoutTime_PCM" SG_ 2566878080 VCU_H2HighPressureMSB 5000;
BA_ "GenSigTimeoutTime_SGW__" SG_ 2566878080 VCU_H2HighPressureMSB 5000;
BA_ "CI_ParId" SG_ 2566878080 StatusHP_LPpressuresensors "IB3040";
BA_ "CI_SigId" SG_ 2566878080 StatusHP_LPpressuresensors 18946;
BA_ "CI_SigName" SG_ 2566878080 StatusHP_LPpressuresensors "Status HP&LP pressure sensors";
BA_ "GenSigTimeoutTime_PCM" SG_ 2566878080 StatusHP_LPpressuresensors 5000;
BA_ "GenSigTimeoutTime_SGW__" SG_ 2566878080 StatusHP_LPpressuresensors 5000;
BA_ "CI_ParId" SG_ 2566878080 StatusShutOffValve "IB3041";
BA_ "CI_SigId" SG_ 2566878080 StatusShutOffValve 18947;
BA_ "CI_SigName" SG_ 2566878080 StatusShutOffValve "Status ShutOff Valve";
BA_ "GenSigTimeoutTime_PCM" SG_ 2566878080 StatusShutOffValve 5000;
BA_ "GenSigTimeoutTime_SGW__" SG_ 2566878080 StatusShutOffValve 5000;
BA_ "CI_ParId" SG_ 2566878080 StatusH2Lines "IB3042";
BA_ "CI_SigId" SG_ 2566878080 StatusH2Lines 18948;
BA_ "CI_SigName" SG_ 2566878080 StatusH2Lines "Status H2 Lines";
BA_ "GenSigTimeoutTime_PCM" SG_ 2566878080 StatusH2Lines 5000;
BA_ "GenSigTimeoutTime_SGW__" SG_ 2566878080 StatusH2Lines 5000;
BA_ "CI_ParId" SG_ 2566878080 LeakagetestsStatusatstartup "IB3043";
BA_ "CI_SigId" SG_ 2566878080 LeakagetestsStatusatstartup 18949;
BA_ "CI_SigName" SG_ 2566878080 LeakagetestsStatusatstartup "Leakage tests Status at start up";
BA_ "GenSigTimeoutTime_PCM" SG_ 2566878080 LeakagetestsStatusatstartup 5000;
BA_ "GenSigTimeoutTime_SGW__" SG_ 2566878080 LeakagetestsStatusatstartup 5000;
BA_ "CI_ParId" SG_ 2566878080 LeakagetestsStatusatShutdown "IB3044";
BA_ "CI_SigId" SG_ 2566878080 LeakagetestsStatusatShutdown 18950;
BA_ "CI_SigName" SG_ 2566878080 LeakagetestsStatusatShutdown "Leakage tests Status at Shutdown";
BA_ "GenSigTimeoutTime_PCM" SG_ 2566878080 LeakagetestsStatusatShutdown 5000;
BA_ "GenSigTimeoutTime_SGW__" SG_ 2566878080 LeakagetestsStatusatShutdown 5000;
BA_ "CI_ParId" SG_ 2566878080 VCU_H2LowPressure "IB3045";
BA_ "CI_SigId" SG_ 2566878080 VCU_H2LowPressure 18951;
BA_ "CI_SigName" SG_ 2566878080 VCU_H2LowPressure "VCU_H2LowPressure";
BA_ "GenSigTimeoutTime_PCM" SG_ 2566878080 VCU_H2LowPressure 5000;
BA_ "GenSigTimeoutTime_SGW__" SG_ 2566878080 VCU_H2LowPressure 5000;
BA_ "CI_ParId" SG_ 2566878080 VCU_H2MidPressure "IB3046";
BA_ "CI_SigId" SG_ 2566878080 VCU_H2MidPressure 18952;
BA_ "CI_SigName" SG_ 2566878080 VCU_H2MidPressure "VCU_H2MidPressure";
BA_ "GenSigTimeoutTime_PCM" SG_ 2566878080 VCU_H2MidPressure 5000;
BA_ "GenSigTimeoutTime_SGW__" SG_ 2566878080 VCU_H2MidPressure 5000;
BA_ "CI_ParId" SG_ 2566878080 VCU_H2PressureTank1 "IB3047";
BA_ "CI_SigId" SG_ 2566878080 VCU_H2PressureTank1 18953;
BA_ "CI_SigName" SG_ 2566878080 VCU_H2PressureTank1 "VCU_H2PressureTank1";
BA_ "GenSigTimeoutTime_PCM" SG_ 2566878080 VCU_H2PressureTank1 5000;
BA_ "GenSigTimeoutTime_SGW__" SG_ 2566878080 VCU_H2PressureTank1 5000;
BA_ "CI_ParId" SG_ 2566878080 VCU_H2PressureTank2 "IB3048";
BA_ "CI_SigId" SG_ 2566878080 VCU_H2PressureTank2 18954;
BA_ "CI_SigName" SG_ 2566878080 VCU_H2PressureTank2 "VCU_H2PressureTank2";
BA_ "GenSigTimeoutTime_PCM" SG_ 2566878080 VCU_H2PressureTank2 5000;
BA_ "GenSigTimeoutTime_SGW__" SG_ 2566878080 VCU_H2PressureTank2 5000;
BA_ "CI_ParId" SG_ 2566878080 VCU_H2PressureTank3 "IB3049";
BA_ "CI_SigId" SG_ 2566878080 VCU_H2PressureTank3 18955;
BA_ "CI_SigName" SG_ 2566878080 VCU_H2PressureTank3 "VCU_H2PressureTank3";
BA_ "GenSigTimeoutTime_PCM" SG_ 2566878080 VCU_H2PressureTank3 5000;
BA_ "GenSigTimeoutTime_SGW__" SG_ 2566878080 VCU_H2PressureTank3 5000;
BA_ "CI_ParId" SG_ 2566878080 VCU_H2PressureTank4 "IB3050";
BA_ "CI_SigId" SG_ 2566878080 VCU_H2PressureTank4 18956;
BA_ "CI_SigName" SG_ 2566878080 VCU_H2PressureTank4 "VCU_H2PressureTank4";
BA_ "GenSigTimeoutTime_PCM" SG_ 2566878080 VCU_H2PressureTank4 5000;
BA_ "GenSigTimeoutTime_SGW__" SG_ 2566878080 VCU_H2PressureTank4 5000;
BA_ "CI_ParId" SG_ 2566878592 H2temperaturetank1 "IB3056";
BA_ "CI_SigId" SG_ 2566878592 H2temperaturetank1 18964;
BA_ "CI_SigName" SG_ 2566878592 H2temperaturetank1 "H2 temperature tank 1";
BA_ "GenSigTimeoutTime_PCM" SG_ 2566878592 H2temperaturetank1 5000;
BA_ "GenSigTimeoutTime_SGW__" SG_ 2566878592 H2temperaturetank1 5000;
BA_ "CI_ParId" SG_ 2566878592 H2temperaturetank2 "IB3057";
BA_ "CI_SigId" SG_ 2566878592 H2temperaturetank2 18965;
BA_ "CI_SigName" SG_ 2566878592 H2temperaturetank2 "H2 temperature tank 2";
BA_ "GenSigTimeoutTime_PCM" SG_ 2566878592 H2temperaturetank2 5000;
BA_ "GenSigTimeoutTime_SGW__" SG_ 2566878592 H2temperaturetank2 5000;
BA_ "CI_ParId" SG_ 2566878592 H2temperaturetank3 "IB3058";
BA_ "CI_SigId" SG_ 2566878592 H2temperaturetank3 18966;
BA_ "CI_SigName" SG_ 2566878592 H2temperaturetank3 "H2 temperature tank 3";
BA_ "GenSigTimeoutTime_PCM" SG_ 2566878592 H2temperaturetank3 5000;
BA_ "GenSigTimeoutTime_SGW__" SG_ 2566878592 H2temperaturetank3 5000;
BA_ "CI_ParId" SG_ 2566878592 H2temperaturetank4 "IB3059";
BA_ "CI_SigId" SG_ 2566878592 H2temperaturetank4 18967;
BA_ "CI_SigName" SG_ 2566878592 H2temperaturetank4 "H2 temperature tank 4";
BA_ "GenSigTimeoutTime_PCM" SG_ 2566878592 H2temperaturetank4 5000;
BA_ "GenSigTimeoutTime_SGW__" SG_ 2566878592 H2temperaturetank4 5000;
BA_ "CI_ParId" SG_ 2566878592 H2refuelingplug1 "IB3060";
BA_ "CI_SigId" SG_ 2566878592 H2refuelingplug1 18968;
BA_ "CI_SigName" SG_ 2566878592 H2refuelingplug1 "H2 refueling plug 1";
BA_ "GenSigTimeoutTime_PCM" SG_ 2566878592 H2refuelingplug1 5000;
BA_ "GenSigTimeoutTime_SGW__" SG_ 2566878592 H2refuelingplug1 5000;
BA_ "CI_ParId" SG_ 2566878592 H2refuelingplug2 "IB3061";
BA_ "CI_SigId" SG_ 2566878592 H2refuelingplug2 18969;
BA_ "CI_SigName" SG_ 2566878592 H2refuelingplug2 "H2 refueling plug 2";
BA_ "GenSigTimeoutTime_PCM" SG_ 2566878592 H2refuelingplug2 5000;
BA_ "GenSigTimeoutTime_SGW__" SG_ 2566878592 H2refuelingplug2 5000;
BA_ "CI_ParId" SG_ 2566878592 H2sensor5leakagestatus "IB3062";
BA_ "CI_SigId" SG_ 2566878592 H2sensor5leakagestatus 18970;
BA_ "CI_SigName" SG_ 2566878592 H2sensor5leakagestatus "H2 sensor 5 leakage status";
BA_ "GenSigTimeoutTime_PCM" SG_ 2566878592 H2sensor5leakagestatus 5000;
BA_ "GenSigTimeoutTime_SGW__" SG_ 2566878592 H2sensor5leakagestatus 5000;
BA_ "CI_ParId" SG_ 2566878592 H2sensor6leakagestatus "IB3063";
BA_ "CI_SigId" SG_ 2566878592 H2sensor6leakagestatus 18971;
BA_ "CI_SigName" SG_ 2566878592 H2sensor6leakagestatus "H2 sensor 6 leakage status";
BA_ "GenSigTimeoutTime_PCM" SG_ 2566878592 H2sensor6leakagestatus 5000;
BA_ "GenSigTimeoutTime_SGW__" SG_ 2566878592 H2sensor6leakagestatus 5000;
BA_ "CI_ParId" SG_ 2566878592 IRD1status "IB3064";
BA_ "CI_SigId" SG_ 2566878592 IRD1status 18972;
BA_ "CI_SigName" SG_ 2566878592 IRD1status "IRD #1 status";
BA_ "GenSigTimeoutTime_PCM" SG_ 2566878592 IRD1status 5000;
BA_ "GenSigTimeoutTime_SGW__" SG_ 2566878592 IRD1status 5000;
BA_ "CI_ParId" SG_ 2566878592 IRD2status "IB3065";
BA_ "CI_SigId" SG_ 2566878592 IRD2status 18973;
BA_ "CI_SigName" SG_ 2566878592 IRD2status "IRD #2 status";
BA_ "GenSigTimeoutTime_PCM" SG_ 2566878592 IRD2status 5000;
BA_ "GenSigTimeoutTime_SGW__" SG_ 2566878592 IRD2status 5000;
BA_ "CI_ParId" SG_ 2566878592 RefuelingMode "IB3068";
BA_ "CI_SigId" SG_ 2566878592 RefuelingMode 18976;
BA_ "CI_SigName" SG_ 2566878592 RefuelingMode "Refueling mode";
BA_ "GenSigTimeoutTime_PCM" SG_ 2566878592 RefuelingMode 5000;
BA_ "GenSigTimeoutTime_SGW__" SG_ 2566878592 RefuelingMode 5000;
BA_ "CI_ParId" SG_ 2566803211 VdcInfoSig "1813";
BA_ "CI_SigId" SG_ 2566803211 VdcInfoSig 346;
BA_ "CI_SigName" SG_ 2566803211 VdcInfoSig "VDC Information Signal";
BA_ "GenSigTimeoutTime_MulticII" SG_ 2566803211 VdcInfoSig 500;
BA_ "GenSigTimeoutTime_MulticS__" SG_ 2566803211 VdcInfoSig 500;
BA_ "GenSigTimeoutTime_PCM" SG_ 2566803211 VdcInfoSig 500;
BA_ "GenSigTimeoutTime_SGW__" SG_ 2566803211 VdcInfoSig 500;
BA_ "GenSigTimeoutTime_VCM" SG_ 2566803211 VdcInfoSig 500;
BA_ "SPN" SG_ 2566803211 VdcInfoSig 1813;
BA_ "SigType" SG_ 2566803211 VdcInfoSig 4;
BA_ "CI_ParId" SG_ 2566803211 VdcFullyOp "1814";
BA_ "CI_SigId" SG_ 2566803211 VdcFullyOp 347;
BA_ "CI_SigName" SG_ 2566803211 VdcFullyOp "VDC Fully Operational";
BA_ "GenSigTimeoutTime_ADCU" SG_ 2566803211 VdcFullyOp 500;
BA_ "GenSigTimeoutTime_Ecolife2" SG_ 2566803211 VdcFullyOp 500;
BA_ "GenSigTimeoutTime_MulticII" SG_ 2566803211 VdcFullyOp 500;
BA_ "GenSigTimeoutTime_MulticS" SG_ 2566803211 VdcFullyOp 500;
BA_ "GenSigTimeoutTime_MulticS_" SG_ 2566803211 VdcFullyOp 500;
BA_ "GenSigTimeoutTime_MulticS__" SG_ 2566803211 VdcFullyOp 500;
BA_ "GenSigTimeoutTime_PCM" SG_ 2566803211 VdcFullyOp 500;
BA_ "GenSigTimeoutTime_SGW__" SG_ 2566803211 VdcFullyOp 500;
BA_ "GenSigTimeoutTime_VCM" SG_ 2566803211 VdcFullyOp 500;
BA_ "SPN" SG_ 2566803211 VdcFullyOp 1814;
BA_ "SigType" SG_ 2566803211 VdcFullyOp 4;
BA_ "CI_ParId" SG_ 2565867787 SteerWhAngle "1807";
BA_ "CI_SigId" SG_ 2565867787 SteerWhAngle 355;
BA_ "CI_SigName" SG_ 2565867787 SteerWhAngle "Steering Wheel Angle";
BA_ "GenSigTimeoutTime_ADCU" SG_ 2565867787 SteerWhAngle 500;
BA_ "GenSigTimeoutTime_ELC5_Fr" SG_ 2565867787 SteerWhAngle 500;
BA_ "GenSigTimeoutTime_FMS4" SG_ 2565867787 SteerWhAngle 500;
BA_ "GenSigTimeoutTime_NBM" SG_ 2565867787 SteerWhAngle 500;
BA_ "GenSigTimeoutTime_NBM_" SG_ 2565867787 SteerWhAngle 500;
BA_ "GenSigTimeoutTime_NBM__" SG_ 2565867787 SteerWhAngle 500;
BA_ "GenSigTimeoutTime_NBM___" SG_ 2565867787 SteerWhAngle 500;
BA_ "GenSigTimeoutTime_PCM" SG_ 2565867787 SteerWhAngle 500;
BA_ "GenSigTimeoutTime_SGW__" SG_ 2565867787 SteerWhAngle 500;
BA_ "SPN" SG_ 2565867787 SteerWhAngle 1807;
BA_ "SigType" SG_ 2565867787 SteerWhAngle 1;
BA_ "CI_ParId" SG_ 2565867787 YawRate "1808";
BA_ "CI_SigId" SG_ 2565867787 YawRate 358;
BA_ "CI_SigName" SG_ 2565867787 YawRate "Yaw Rate";
BA_ "GenSigTimeoutTime_ADCU" SG_ 2565867787 YawRate 500;
BA_ "GenSigTimeoutTime_PCM" SG_ 2565867787 YawRate 500;
BA_ "GenSigTimeoutTime_SGW__" SG_ 2565867787 YawRate 500;
BA_ "SPN" SG_ 2565867787 YawRate 1808;
BA_ "SigType" SG_ 2565867787 YawRate 1;
BA_ "CI_ParId" SG_ 2565867787 LatAccel "1809";
BA_ "CI_SigId" SG_ 2565867787 LatAccel 359;
BA_ "CI_SigName" SG_ 2565867787 LatAccel "Lateral Acceleration";
BA_ "GenSigTimeoutTime_ADCU" SG_ 2565867787 LatAccel 500;
BA_ "GenSigTimeoutTime_PCM" SG_ 2565867787 LatAccel 500;
BA_ "GenSigTimeoutTime_SGW__" SG_ 2565867787 LatAccel 500;
BA_ "SPN" SG_ 2565867787 LatAccel 1809;
BA_ "SigType" SG_ 2565867787 LatAccel 1;
BA_ "CI_ParId" SG_ 2565867787 LongAccel "1810";
BA_ "CI_SigId" SG_ 2565867787 LongAccel 360;
BA_ "CI_SigName" SG_ 2565867787 LongAccel "Longitudinal Acceleration";
BA_ "GenSigTimeoutTime_ADCU" SG_ 2565867787 LongAccel 500;
BA_ "GenSigTimeoutTime_PCM" SG_ 2565867787 LongAccel 500;
BA_ "GenSigTimeoutTime_SGW__" SG_ 2565867787 LongAccel 500;
BA_ "SPN" SG_ 2565867787 LongAccel 1810;
BA_ "SigType" SG_ 2565867787 LongAccel 1;
BA_ "CI_ParId" SG_ 2566832622 TotVehDistHr "917";
BA_ "CI_SigId" SG_ 2566832622 TotVehDistHr 674;
BA_ "CI_SigName" SG_ 2566832622 TotVehDistHr "Total Vehicle Distance (High Resolution)";
BA_ "GenSigTimeoutTime_ADCU" SG_ 2566832622 TotVehDistHr 5000;
BA_ "GenSigTimeoutTime_CANAIR" SG_ 2566832622 TotVehDistHr 5000;
BA_ "GenSigTimeoutTime_DICO" SG_ 2566832622 TotVehDistHr 5000;
BA_ "GenSigTimeoutTime_ELFA3" SG_ 2566832622 TotVehDistHr 5000;
BA_ "GenSigTimeoutTime_Ecolife2" SG_ 2566832622 TotVehDistHr 5000;
BA_ "GenSigTimeoutTime_FMS4" SG_ 2566832622 TotVehDistHr 5000;
BA_ "GenSigTimeoutTime_IRCS" SG_ 2566832622 TotVehDistHr 5000;
BA_ "GenSigTimeoutTime_MD1_D" SG_ 2566832622 TotVehDistHr 5000;
BA_ "GenSigTimeoutTime_MD1_G" SG_ 2566832622 TotVehDistHr 5000;
BA_ "GenSigTimeoutTime_MulticII" SG_ 2566832622 TotVehDistHr 5000;
BA_ "GenSigTimeoutTime_MulticS" SG_ 2566832622 TotVehDistHr 5000;
BA_ "GenSigTimeoutTime_MulticS_" SG_ 2566832622 TotVehDistHr 5000;
BA_ "GenSigTimeoutTime_MulticS__" SG_ 2566832622 TotVehDistHr 5000;
BA_ "GenSigTimeoutTime_NBM" SG_ 2566832622 TotVehDistHr 5000;
BA_ "GenSigTimeoutTime_NBM_" SG_ 2566832622 TotVehDistHr 5000;
BA_ "GenSigTimeoutTime_NBM___" SG_ 2566832622 TotVehDistHr 5000;
BA_ "GenSigTimeoutTime_PCM" SG_ 2566832622 TotVehDistHr 5000;
BA_ "GenSigTimeoutTime_SGW2" SG_ 2566832622 TotVehDistHr 5000;
BA_ "GenSigTimeoutTime_SGW__" SG_ 2566832622 TotVehDistHr 5000;
BA_ "GenSigTimeoutTime_TPMS" SG_ 2566832622 TotVehDistHr 5000;
BA_ "GenSigTimeoutTime_VCM" SG_ 2566832622 TotVehDistHr 5000;
BA_ "GenSigTimeoutTime_VCU_" SG_ 2566832622 TotVehDistHr 5000;
BA_ "GenSigTimeoutTime_VMU" SG_ 2566832622 TotVehDistHr 5000;
BA_ "SPN" SG_ 2566832622 TotVehDistHr 917;
BA_ "SigType" SG_ 2566832622 TotVehDistHr 1;
BA_ "CI_ParId" SG_ 2566832622 TripDistHr "918";
BA_ "CI_SigId" SG_ 2566832622 TripDistHr 675;
BA_ "CI_SigName" SG_ 2566832622 TripDistHr "Trip Distance (High Resolution)";
BA_ "GenSigTimeoutTime_CANAIR" SG_ 2566832622 TripDistHr 5000;
BA_ "GenSigTimeoutTime_DICO" SG_ 2566832622 TripDistHr 5000;
BA_ "GenSigTimeoutTime_ELFA3" SG_ 2566832622 TripDistHr 5000;
BA_ "GenSigTimeoutTime_MulticS" SG_ 2566832622 TripDistHr 5000;
BA_ "GenSigTimeoutTime_MulticS_" SG_ 2566832622 TripDistHr 5000;
BA_ "GenSigTimeoutTime_PCM" SG_ 2566832622 TripDistHr 5000;
BA_ "GenSigTimeoutTime_SGW2" SG_ 2566832622 TripDistHr 5000;
BA_ "GenSigTimeoutTime_SGW__" SG_ 2566832622 TripDistHr 5000;
BA_ "GenSigTimeoutTime_VCM" SG_ 2566832622 TripDistHr 5000;
BA_ "GenSigTimeoutTime_VCU_" SG_ 2566832622 TripDistHr 5000;
BA_ "GenSigTimeoutTime_VMU" SG_ 2566832622 TripDistHr 5000;
BA_ "SPN" SG_ 2566832622 TripDistHr 918;
BA_ "SigType" SG_ 2566832622 TripDistHr 1;
BA_ "CI_ParId" SG_ 2566846208 BatPot_PwrIn1 "168";
BA_ "CI_SigId" SG_ 2566846208 BatPot_PwrIn1 2209;
BA_ "CI_SigName" SG_ 2566846208 BatPot_PwrIn1 "Battery Potential / Power Input 1";
BA_ "GenSigTimeoutTime_ADCU" SG_ 2566846208 BatPot_PwrIn1 5000;
BA_ "GenSigTimeoutTime_FMS4" SG_ 2566846208 BatPot_PwrIn1 5000;
BA_ "GenSigTimeoutTime_PCM" SG_ 2566846208 BatPot_PwrIn1 5000;
BA_ "GenSigTimeoutTime_SGW__" SG_ 2566846208 BatPot_PwrIn1 5000;
BA_ "GenSigTimeoutTime_VCM_" SG_ 2566846208 BatPot_PwrIn1 5000;
BA_ "GenSigTimeoutTime_VCM__" SG_ 2566846208 BatPot_PwrIn1 5000;
BA_ "SPN" SG_ 2566846208 BatPot_PwrIn1 168;
BA_ "SigType" SG_ 2566846208 BatPot_PwrIn1 1;
BA_ "CI_ParId" SG_ 2566846451 BatPot_PwrIn1_18FEF7F3 "168";
BA_ "CI_SigId" SG_ 2566846451 BatPot_PwrIn1_18FEF7F3 2215;
BA_ "CI_SigName" SG_ 2566846451 BatPot_PwrIn1_18FEF7F3 "Battery Potential / Power Input 1";
BA_ "GenSigTimeoutTime_PCM" SG_ 2566846451 BatPot_PwrIn1_18FEF7F3 500;
BA_ "GenSigTimeoutTime_SGW__" SG_ 2566846451 BatPot_PwrIn1_18FEF7F3 500;
BA_ "SPN" SG_ 2566846451 BatPot_PwrIn1_18FEF7F3 168;
BA_ "SigType" SG_ 2566846451 BatPot_PwrIn1_18FEF7F3 1;
BA_ "CI_ParId" SG_ 2566804211 SliBat1NetCurHr "2579";
BA_ "CI_SigId" SG_ 2566804211 SliBat1NetCurHr 2219;
BA_ "CI_SigName" SG_ 2566804211 SliBat1NetCurHr "SLI Battery 1 Net Current (High Range/Resolution)";
BA_ "GenSigTimeoutTime_PCM" SG_ 2566804211 SliBat1NetCurHr 500;
BA_ "GenSigTimeoutTime_SGW__" SG_ 2566804211 SliBat1NetCurHr 500;
BA_ "SPN" SG_ 2566804211 SliBat1NetCurHr 2579;
BA_ "SigType" SG_ 2566804211 SliBat1NetCurHr 1;
BA_ "CI_ParId" SG_ 2566698739 SliBatSoc "5981";
BA_ "CI_SigId" SG_ 2566698739 SliBatSoc 2587;
BA_ "CI_SigName" SG_ 2566698739 SliBatSoc "SLI Battery Pack State of Charge";
BA_ "GenSigTimeoutTime_PCM" SG_ 2566698739 SliBatSoc 5000;
BA_ "GenSigTimeoutTime_SGW__" SG_ 2566698739 SliBatSoc 5000;
BA_ "SPN" SG_ 2566698739 SliBatSoc 5981;
BA_ "SigType" SG_ 2566698739 SliBatSoc 1;
BA_ "CI_ParId" SG_ 2566698739 SliBatCap "5982";
BA_ "CI_SigId" SG_ 2566698739 SliBatCap 2588;
BA_ "CI_SigName" SG_ 2566698739 SliBatCap "SLI Battery Pack Capacity";
BA_ "GenSigTimeoutTime_PCM" SG_ 2566698739 SliBatCap 5000;
BA_ "GenSigTimeoutTime_SGW__" SG_ 2566698739 SliBatCap 5000;
BA_ "SPN" SG_ 2566698739 SliBatCap 5982;
BA_ "SigType" SG_ 2566698739 SliBatCap 1;
BA_ "CI_ParId" SG_ 2566698739 SliBatHealth "5983";
BA_ "CI_SigId" SG_ 2566698739 SliBatHealth 2589;
BA_ "CI_SigName" SG_ 2566698739 SliBatHealth "SLI Battery Pack Health";
BA_ "GenSigTimeoutTime_PCM" SG_ 2566698739 SliBatHealth 5000;
BA_ "GenSigTimeoutTime_SGW__" SG_ 2566698739 SliBatHealth 5000;
BA_ "SPN" SG_ 2566698739 SliBatHealth 5983;
BA_ "SigType" SG_ 2566698739 SliBatHealth 1;
BA_ "CI_ParId" SG_ 2566843630 Vin "237";
BA_ "CI_SigId" SG_ 2566843630 Vin 744;
BA_ "CI_SigName" SG_ 2566843630 Vin "Vehicle Identification Number";
BA_ "GenSigTimeoutTime_ADCU" SG_ 2566843630 Vin 50000;
BA_ "GenSigTimeoutTime_FMS4" SG_ 2566843630 Vin 50000;
BA_ "GenSigTimeoutTime_PCM" SG_ 2566843630 Vin 50000;
BA_ "SPN" SG_ 2566843630 Vin 237;
BA_ "SigType" SG_ 2566843630 Vin 8;
BA_ "CI_ParId" SG_ 2566845212 Lat "584";
BA_ "CI_SigId" SG_ 2566845212 Lat 3461;
BA_ "CI_SigName" SG_ 2566845212 Lat "Latitude";
BA_ "GenSigTimeoutTime_PCM" SG_ 2566845212 Lat 5000;
BA_ "SPN" SG_ 2566845212 Lat 584;
BA_ "SigType" SG_ 2566845212 Lat 1;
BA_ "CI_ParId" SG_ 2566845212 Long "585";
BA_ "CI_SigId" SG_ 2566845212 Long 3462;
BA_ "CI_SigName" SG_ 2566845212 Long "Longitude";
BA_ "GenSigTimeoutTime_PCM" SG_ 2566845212 Long 5000;
BA_ "SPN" SG_ 2566845212 Long 585;
BA_ "SigType" SG_ 2566845212 Long 1;
BA_ "CI_ParId" SG_ 2566842927 Axle_Location "IB2160";
BA_ "CI_SigId" SG_ 2566842927 Axle_Location 17508;
BA_ "CI_SigName" SG_ 2566842927 Axle_Location "Axle_Location";
BA_ "GenSigTimeoutTime_PCM" SG_ 2566842927 Axle_Location 5000;
BA_ "GenSigTimeoutTime_SGW__" SG_ 2566842927 Axle_Location 5000;
BA_ "CI_ParId" SG_ 2566842927 Axle_Weight_1 "IB2161";
BA_ "CI_SigId" SG_ 2566842927 Axle_Weight_1 17509;
BA_ "CI_SigName" SG_ 2566842927 Axle_Weight_1 "Axle_Weight_1";
BA_ "GenSigTimeoutTime_PCM" SG_ 2566842927 Axle_Weight_1 5000;
BA_ "GenSigTimeoutTime_SGW__" SG_ 2566842927 Axle_Weight_1 5000;
BA_ "SigType" SG_ 2566842927 Axle_Weight_1 1;
BA_ "CI_ParId" SG_ 2566842927 Axle_Weight_2 "IB2162";
BA_ "CI_SigId" SG_ 2566842927 Axle_Weight_2 17510;
BA_ "CI_SigName" SG_ 2566842927 Axle_Weight_2 "Axle_Weight_2";
BA_ "GenSigTimeoutTime_PCM" SG_ 2566842927 Axle_Weight_2 5000;
BA_ "GenSigTimeoutTime_SGW__" SG_ 2566842927 Axle_Weight_2 5000;
BA_ "SigType" SG_ 2566842927 Axle_Weight_2 1;
BA_ "CI_ParId" SG_ 2566842927 Axle_Weight_3 "IB2163";
BA_ "CI_SigId" SG_ 2566842927 Axle_Weight_3 17511;
BA_ "CI_SigName" SG_ 2566842927 Axle_Weight_3 "Axle_Weight_3";
BA_ "GenSigTimeoutTime_PCM" SG_ 2566842927 Axle_Weight_3 5000;
BA_ "GenSigTimeoutTime_SGW__" SG_ 2566842927 Axle_Weight_3 5000;
BA_ "SigType" SG_ 2566842927 Axle_Weight_3 1;
BA_ "CI_ParId" SG_ 2566842927 Axle_Weight_4 "IB2164";
BA_ "CI_SigId" SG_ 2566842927 Axle_Weight_4 17512;
BA_ "CI_SigName" SG_ 2566842927 Axle_Weight_4 "Axle_Weight_4";
BA_ "GenSigTimeoutTime_PCM" SG_ 2566842927 Axle_Weight_4 5000;
BA_ "GenSigTimeoutTime_SGW__" SG_ 2566842927 Axle_Weight_4 5000;
BA_ "SigType" SG_ 2566842927 Axle_Weight_4 1;
BA_ "CI_ParId" SG_ 2566842927 Axle_Weight_5 "IB2165";
BA_ "CI_SigId" SG_ 2566842927 Axle_Weight_5 17513;
BA_ "CI_SigName" SG_ 2566842927 Axle_Weight_5 "Axle_Weight_5";
BA_ "GenSigTimeoutTime_PCM" SG_ 2566842927 Axle_Weight_5 5000;
BA_ "GenSigTimeoutTime_SGW__" SG_ 2566842927 Axle_Weight_5 5000;
BA_ "SigType" SG_ 2566842927 Axle_Weight_5 1;
BA_ "CI_ParId" SG_ 2566842944 Axle_Location_18FEEA40 "IB2160";
BA_ "CI_SigId" SG_ 2566842944 Axle_Location_18FEEA40 17515;
BA_ "CI_SigName" SG_ 2566842944 Axle_Location_18FEEA40 "Axle_Location";
BA_ "GenSigTimeoutTime_PCM" SG_ 2566842944 Axle_Location_18FEEA40 5000;
BA_ "GenSigTimeoutTime_SGW__" SG_ 2566842944 Axle_Location_18FEEA40 5000;
BA_ "CI_ParId" SG_ 2566842944 Axle_Weight_1_18FEEA40 "IB2161";
BA_ "CI_SigId" SG_ 2566842944 Axle_Weight_1_18FEEA40 17516;
BA_ "CI_SigName" SG_ 2566842944 Axle_Weight_1_18FEEA40 "Axle_Weight_1";
BA_ "GenSigTimeoutTime_PCM" SG_ 2566842944 Axle_Weight_1_18FEEA40 5000;
BA_ "GenSigTimeoutTime_SGW__" SG_ 2566842944 Axle_Weight_1_18FEEA40 5000;
BA_ "SigType" SG_ 2566842944 Axle_Weight_1_18FEEA40 1;
BA_ "CI_ParId" SG_ 2566842944 Axle_Weight_2_18FEEA40 "IB2162";
BA_ "CI_SigId" SG_ 2566842944 Axle_Weight_2_18FEEA40 17517;
BA_ "CI_SigName" SG_ 2566842944 Axle_Weight_2_18FEEA40 "Axle_Weight_2";
BA_ "GenSigTimeoutTime_PCM" SG_ 2566842944 Axle_Weight_2_18FEEA40 5000;
BA_ "GenSigTimeoutTime_SGW__" SG_ 2566842944 Axle_Weight_2_18FEEA40 5000;
BA_ "SigType" SG_ 2566842944 Axle_Weight_2_18FEEA40 1;
BA_ "CI_ParId" SG_ 2566842944 Axle_Weight_3_18FEEA40 "IB2163";
BA_ "CI_SigId" SG_ 2566842944 Axle_Weight_3_18FEEA40 17518;
BA_ "CI_SigName" SG_ 2566842944 Axle_Weight_3_18FEEA40 "Axle_Weight_3";
BA_ "GenSigTimeoutTime_PCM" SG_ 2566842944 Axle_Weight_3_18FEEA40 5000;
BA_ "GenSigTimeoutTime_SGW__" SG_ 2566842944 Axle_Weight_3_18FEEA40 5000;
BA_ "SigType" SG_ 2566842944 Axle_Weight_3_18FEEA40 1;
BA_ "CI_ParId" SG_ 2566842944 Axle_Weight_4_18FEEA40 "IB2164";
BA_ "CI_SigId" SG_ 2566842944 Axle_Weight_4_18FEEA40 17519;
BA_ "CI_SigName" SG_ 2566842944 Axle_Weight_4_18FEEA40 "Axle_Weight_4";
BA_ "GenSigTimeoutTime_PCM" SG_ 2566842944 Axle_Weight_4_18FEEA40 5000;
BA_ "GenSigTimeoutTime_SGW__" SG_ 2566842944 Axle_Weight_4_18FEEA40 5000;
BA_ "SigType" SG_ 2566842944 Axle_Weight_4_18FEEA40 1;
BA_ "CI_ParId" SG_ 2566842944 Axle_Weight_5_18FEEA40 "IB2165";
BA_ "CI_SigId" SG_ 2566842944 Axle_Weight_5_18FEEA40 17520;
BA_ "CI_SigName" SG_ 2566842944 Axle_Weight_5_18FEEA40 "Axle_Weight_5";
BA_ "GenSigTimeoutTime_PCM" SG_ 2566842944 Axle_Weight_5_18FEEA40 5000;
BA_ "GenSigTimeoutTime_SGW__" SG_ 2566842944 Axle_Weight_5_18FEEA40 5000;
BA_ "SigType" SG_ 2566842944 Axle_Weight_5_18FEEA40 1;
BA_ "CI_ParId" SG_ 2566848256 WaterInFuelInd1 "97";
BA_ "CI_SigId" SG_ 2566848256 WaterInFuelInd1 1617;
BA_ "CI_SigName" SG_ 2566848256 WaterInFuelInd1 "Water In Fuel Indicator 1";
BA_ "GenSigTimeoutTime_MulticS" SG_ 2566848256 WaterInFuelInd1 5000;
BA_ "GenSigTimeoutTime_MulticS__" SG_ 2566848256 WaterInFuelInd1 5000;
BA_ "GenSigTimeoutTime_PCM" SG_ 2566848256 WaterInFuelInd1 5000;
BA_ "GenSigTimeoutTime_SGW__" SG_ 2566848256 WaterInFuelInd1 5000;
BA_ "GenSigTimeoutTime_VCM_" SG_ 2566848256 WaterInFuelInd1 5000;
BA_ "SPN" SG_ 2566848256 WaterInFuelInd1 97;
BA_ "SigType" SG_ 2566848256 WaterInFuelInd1 4;
BA_ "CI_ParId" SG_ 2349075360 XbrMsgCnt "3189";
BA_ "CI_SigId" SG_ 2349075360 XbrMsgCnt 343;
BA_ "CI_SigName" SG_ 2349075360 XbrMsgCnt "XBR Message Counter";
BA_ "GenSigTimeoutTime_EBS" SG_ 2349075360 XbrMsgCnt 1000;
BA_ "GenSigTimeoutTime_EBS_" SG_ 2349075360 XbrMsgCnt 1000;
BA_ "GenSigTimeoutTime_PCM" SG_ 2349075360 XbrMsgCnt 1000;
BA_ "GenSigTimeoutTime_SGW__" SG_ 2349075360 XbrMsgCnt 1000;
BA_ "SPN" SG_ 2349075360 XbrMsgCnt 3189;
BA_ "CI_ParId" SG_ 2565472330 PgnRqst_4A_00 "2540";
BA_ "CI_SigId" SG_ 2565472330 PgnRqst_4A_00 100001;
BA_ "CI_SigName" SG_ 2565472330 PgnRqst_4A_00 "Parameter Group Number (RQST)";
BA_ "SPN" SG_ 2565472330 PgnRqst_4A_00 2540;
BA_ "SigType" SG_ 2565472330 PgnRqst_4A_00 6;
BA_ "CI_ParId" SG_ 2565482314 PgnRqst_4A_27 "2540";
BA_ "CI_SigId" SG_ 2565482314 PgnRqst_4A_27 100003;
BA_ "CI_SigName" SG_ 2565482314 PgnRqst_4A_27 "Parameter Group Number (RQST)";
BA_ "SPN" SG_ 2565482314 PgnRqst_4A_27 2540;
BA_ "SigType" SG_ 2565482314 PgnRqst_4A_27 6;
BA_ "CI_ParId" SG_ 2565478218 PgnRqst_4A_17 "2540";
BA_ "CI_SigId" SG_ 2565478218 PgnRqst_4A_17 100005;
BA_ "CI_SigName" SG_ 2565478218 PgnRqst_4A_17 "Parameter Group Number (RQST)";
BA_ "SPN" SG_ 2565478218 PgnRqst_4A_17 2540;
BA_ "SigType" SG_ 2565478218 PgnRqst_4A_17 6;
BA_ "CI_ParId" SG_ 2565473098 PgnRqst_4A_03 "2540";
BA_ "CI_SigId" SG_ 2565473098 PgnRqst_4A_03 100007;
BA_ "CI_SigName" SG_ 2565473098 PgnRqst_4A_03 "Parameter Group Number (RQST)";
BA_ "SPN" SG_ 2565473098 PgnRqst_4A_03 2540;
BA_ "SigType" SG_ 2565473098 PgnRqst_4A_03 6;
BA_ "CI_ParId" SG_ 2565475146 PgnRqst_4A_0B "2540";
BA_ "CI_SigId" SG_ 2565475146 PgnRqst_4A_0B 100009;
BA_ "CI_SigName" SG_ 2565475146 PgnRqst_4A_0B "Parameter Group Number (RQST)";
BA_ "SPN" SG_ 2565475146 PgnRqst_4A_0B 2540;
BA_ "SigType" SG_ 2565475146 PgnRqst_4A_0B 6;
BA_ "CI_ParId" SG_ 2565479754 PgnRqst_4A_1D "2540";
BA_ "CI_SigId" SG_ 2565479754 PgnRqst_4A_1D 100011;
BA_ "CI_SigName" SG_ 2565479754 PgnRqst_4A_1D "Parameter Group Number (RQST)";
BA_ "SPN" SG_ 2565479754 PgnRqst_4A_1D 2540;
BA_ "SigType" SG_ 2565479754 PgnRqst_4A_1D 6;
BA_ "CI_ParId" SG_ 2565486666 PgnRqst_4A_38 "2540";
BA_ "CI_SigId" SG_ 2565486666 PgnRqst_4A_38 100013;
BA_ "CI_SigName" SG_ 2565486666 PgnRqst_4A_38 "Parameter Group Number (RQST)";
BA_ "SPN" SG_ 2565486666 PgnRqst_4A_38 2540;
BA_ "SigType" SG_ 2565486666 PgnRqst_4A_38 6;
BA_ "CI_ParId" SG_ 2565504586 PgnRqst_4A_7E "2540";
BA_ "CI_SigId" SG_ 2565504586 PgnRqst_4A_7E 100015;
BA_ "CI_SigName" SG_ 2565504586 PgnRqst_4A_7E "Parameter Group Number (RQST)";
BA_ "SPN" SG_ 2565504586 PgnRqst_4A_7E 2540;
BA_ "SigType" SG_ 2565504586 PgnRqst_4A_7E 6;
BA_ "CI_ParId" SG_ 2565512778 PgnRqst_4A_9E "2540";
BA_ "CI_SigId" SG_ 2565512778 PgnRqst_4A_9E 100017;
BA_ "CI_SigName" SG_ 2565512778 PgnRqst_4A_9E "Parameter Group Number (RQST)";
BA_ "SPN" SG_ 2565512778 PgnRqst_4A_9E 2540;
BA_ "SigType" SG_ 2565512778 PgnRqst_4A_9E 6;
BA_ "CI_ParId" SG_ 2565513290 PgnRqst_4A_A0 "2540";
BA_ "CI_SigId" SG_ 2565513290 PgnRqst_4A_A0 100019;
BA_ "CI_SigName" SG_ 2565513290 PgnRqst_4A_A0 "Parameter Group Number (RQST)";
BA_ "SPN" SG_ 2565513290 PgnRqst_4A_A0 2540;
BA_ "SigType" SG_ 2565513290 PgnRqst_4A_A0 6;
BA_ "CI_ParId" SG_ 2565531466 PgnRqst_4A_E7 "2540";
BA_ "CI_SigId" SG_ 2565531466 PgnRqst_4A_E7 100021;
BA_ "CI_SigName" SG_ 2565531466 PgnRqst_4A_E7 "Parameter Group Number (RQST)";
BA_ "SPN" SG_ 2565531466 PgnRqst_4A_E7 2540;
BA_ "SigType" SG_ 2565531466 PgnRqst_4A_E7 6;
BA_ "CI_ParId" SG_ 2565480778 PgnRqst_4A_21 "2540";
BA_ "CI_SigId" SG_ 2565480778 PgnRqst_4A_21 100023;
BA_ "CI_SigName" SG_ 2565480778 PgnRqst_4A_21 "Parameter Group Number (RQST)";
BA_ "SPN" SG_ 2565480778 PgnRqst_4A_21 2540;
BA_ "SigType" SG_ 2565480778 PgnRqst_4A_21 6;
BA_ "CI_ParId" SG_ 2565496394 PgnRqst_4A_5E "2540";
BA_ "CI_SigId" SG_ 2565496394 PgnRqst_4A_5E 100025;
BA_ "CI_SigName" SG_ 2565496394 PgnRqst_4A_5E "Parameter Group Number (RQST)";
BA_ "SPN" SG_ 2565496394 PgnRqst_4A_5E 2540;
BA_ "SigType" SG_ 2565496394 PgnRqst_4A_5E 6;
BA_ "CI_ParId" SG_ 2565495370 PgnRqst_4A_5A "2540";
BA_ "CI_SigId" SG_ 2565495370 PgnRqst_4A_5A 100027;
BA_ "CI_SigName" SG_ 2565495370 PgnRqst_4A_5A "Parameter Group Number (RQST)";
BA_ "SPN" SG_ 2565495370 PgnRqst_4A_5A 2540;
BA_ "SigType" SG_ 2565495370 PgnRqst_4A_5A 6;
BA_ "CI_ParId" SG_ 2565484362 PgnRqst_4A_2F "2540";
BA_ "CI_SigId" SG_ 2565484362 PgnRqst_4A_2F 100029;
BA_ "CI_SigName" SG_ 2565484362 PgnRqst_4A_2F "Parameter Group Number (RQST)";
BA_ "SPN" SG_ 2565484362 PgnRqst_4A_2F 2540;
BA_ "SigType" SG_ 2565484362 PgnRqst_4A_2F 6;
BA_ "CI_ParId" SG_ 2565488714 PgnRqst_4A_40 "2540";
BA_ "CI_SigId" SG_ 2565488714 PgnRqst_4A_40 100031;
BA_ "CI_SigName" SG_ 2565488714 PgnRqst_4A_40 "Parameter Group Number (RQST)";
BA_ "SPN" SG_ 2565488714 PgnRqst_4A_40 2540;
BA_ "SigType" SG_ 2565488714 PgnRqst_4A_40 6;
BA_ "CI_ParId" SG_ 2565535562 PgnRqst_4A_F7 "2540";
BA_ "CI_SigId" SG_ 2565535562 PgnRqst_4A_F7 100033;
BA_ "CI_SigName" SG_ 2565535562 PgnRqst_4A_F7 "Parameter Group Number (RQST)";
BA_ "SPN" SG_ 2565535562 PgnRqst_4A_F7 2540;
BA_ "SigType" SG_ 2565535562 PgnRqst_4A_F7 6;
BA_ "CI_ParId" SG_ 2565535306 PgnRqst_4A_F6 "2540";
BA_ "CI_SigId" SG_ 2565535306 PgnRqst_4A_F6 100035;
BA_ "CI_SigName" SG_ 2565535306 PgnRqst_4A_F6 "Parameter Group Number (RQST)";
BA_ "SPN" SG_ 2565535306 PgnRqst_4A_F6 2540;
BA_ "SigType" SG_ 2565535306 PgnRqst_4A_F6 6;
BA_ "CI_ParId" SG_ 2565534538 PgnRqst_4A_F3 "2540";
BA_ "CI_SigId" SG_ 2565534538 PgnRqst_4A_F3 100037;
BA_ "CI_SigName" SG_ 2565534538 PgnRqst_4A_F3 "Parameter Group Number (RQST)";
BA_ "SPN" SG_ 2565534538 PgnRqst_4A_F3 2540;
BA_ "SigType" SG_ 2565534538 PgnRqst_4A_F3 6;
BA_ "CI_ParId" SG_ 2565491018 PgnRqst_4A_49 "2540";
BA_ "CI_SigId" SG_ 2565491018 PgnRqst_4A_49 100039;
BA_ "CI_SigName" SG_ 2565491018 PgnRqst_4A_49 "Parameter Group Number (RQST)";
BA_ "SPN" SG_ 2565491018 PgnRqst_4A_49 2540;
BA_ "SigType" SG_ 2565491018 PgnRqst_4A_49 6;
BA_ "CI_ParId" SG_ 2565476426 PgnRqst_4A_10 "2540";
BA_ "CI_SigId" SG_ 2565476426 PgnRqst_4A_10 100041;
BA_ "CI_SigName" SG_ 2565476426 PgnRqst_4A_10 "Parameter Group Number (RQST)";
BA_ "SPN" SG_ 2565476426 PgnRqst_4A_10 2540;
BA_ "SigType" SG_ 2565476426 PgnRqst_4A_10 6;
BA_ "CI_ParId" SG_ 2565484106 PgnRqst_4A_2E "2540";
BA_ "CI_SigId" SG_ 2565484106 PgnRqst_4A_2E 100043;
BA_ "CI_SigName" SG_ 2565484106 PgnRqst_4A_2E "Parameter Group Number (RQST)";
BA_ "SPN" SG_ 2565484106 PgnRqst_4A_2E 2540;
BA_ "SigType" SG_ 2565484106 PgnRqst_4A_2E 6;
BA_ "CI_ParId" SG_ 2565509194 PgnRqst_4A_90 "2540";
BA_ "CI_SigId" SG_ 2565509194 PgnRqst_4A_90 100045;
BA_ "CI_SigName" SG_ 2565509194 PgnRqst_4A_90 "Parameter Group Number (RQST)";
BA_ "SPN" SG_ 2565509194 PgnRqst_4A_90 2540;
BA_ "SigType" SG_ 2565509194 PgnRqst_4A_90 6;
BA_ "CI_ParId" SG_ 2565509450 PgnRqst_4A_91 "2540";
BA_ "CI_SigId" SG_ 2565509450 PgnRqst_4A_91 100047;
BA_ "CI_SigName" SG_ 2565509450 PgnRqst_4A_91 "Parameter Group Number (RQST)";
BA_ "SPN" SG_ 2565509450 PgnRqst_4A_91 2540;
BA_ "SigType" SG_ 2565509450 PgnRqst_4A_91 6;
BA_ "CI_ParId" SG_ 2565509706 PgnRqst_4A_92 "2540";
BA_ "CI_SigId" SG_ 2565509706 PgnRqst_4A_92 100049;
BA_ "CI_SigName" SG_ 2565509706 PgnRqst_4A_92 "Parameter Group Number (RQST)";
BA_ "SPN" SG_ 2565509706 PgnRqst_4A_92 2540;
BA_ "SigType" SG_ 2565509706 PgnRqst_4A_92 6;
BA_ "CI_ParId" SG_ 2565512266 PgnRqst_4A_9C "2540";
BA_ "CI_SigId" SG_ 2565512266 PgnRqst_4A_9C 100051;
BA_ "CI_SigName" SG_ 2565512266 PgnRqst_4A_9C "Parameter Group Number (RQST)";
BA_ "SPN" SG_ 2565512266 PgnRqst_4A_9C 2540;
BA_ "SigType" SG_ 2565512266 PgnRqst_4A_9C 6;
BA_ "CI_ParId" SG_ 2565521994 PgnRqst_4A_C2 "2540";
BA_ "CI_SigId" SG_ 2565521994 PgnRqst_4A_C2 100053;
BA_ "CI_SigName" SG_ 2565521994 PgnRqst_4A_C2 "Parameter Group Number (RQST)";
BA_ "SPN" SG_ 2565521994 PgnRqst_4A_C2 2540;
BA_ "SigType" SG_ 2565521994 PgnRqst_4A_C2 6;
BA_ "CI_ParId" SG_ 2565531722 PgnRqst_4A_E8 "2540";
BA_ "CI_SigId" SG_ 2565531722 PgnRqst_4A_E8 100055;
BA_ "CI_SigName" SG_ 2565531722 PgnRqst_4A_E8 "Parameter Group Number (RQST)";
BA_ "SPN" SG_ 2565531722 PgnRqst_4A_E8 2540;
BA_ "SigType" SG_ 2565531722 PgnRqst_4A_E8 6;
BA_ "CI_ParId" SG_ 2565505098 PgnRqst_4A_80 "2540";
BA_ "CI_SigId" SG_ 2565505098 PgnRqst_4A_80 100057;
BA_ "CI_SigName" SG_ 2565505098 PgnRqst_4A_80 "Parameter Group Number (RQST)";
BA_ "SPN" SG_ 2565505098 PgnRqst_4A_80 2540;
BA_ "SigType" SG_ 2565505098 PgnRqst_4A_80 6;
BA_ "CI_ParId" SG_ 2565489994 PgnRqst_4A_45 "2540";
BA_ "CI_SigId" SG_ 2565489994 PgnRqst_4A_45 100059;
BA_ "CI_SigName" SG_ 2565489994 PgnRqst_4A_45 "Parameter Group Number (RQST)";
BA_ "SPN" SG_ 2565489994 PgnRqst_4A_45 2540;
BA_ "SigType" SG_ 2565489994 PgnRqst_4A_45 6;
BA_ "CI_ParId" SG_ 2565501514 PgnRqst_4A_72 "2540";
BA_ "CI_SigId" SG_ 2565501514 PgnRqst_4A_72 100061;
BA_ "CI_SigName" SG_ 2565501514 PgnRqst_4A_72 "Parameter Group Number (RQST)";
BA_ "SPN" SG_ 2565501514 PgnRqst_4A_72 2540;
BA_ "SigType" SG_ 2565501514 PgnRqst_4A_72 6;
BA_ "CI_ParId" SG_ 2565476170 PgnRqst_4A_0F "2540";
BA_ "CI_SigId" SG_ 2565476170 PgnRqst_4A_0F 100063;
BA_ "CI_SigName" SG_ 2565476170 PgnRqst_4A_0F "Parameter Group Number (RQST)";
BA_ "SPN" SG_ 2565476170 PgnRqst_4A_0F 2540;
BA_ "SigType" SG_ 2565476170 PgnRqst_4A_0F 6;
BA_ "CI_ParId" SG_ 2565533514 PgnRqst_4A_EF "2540";
BA_ "CI_SigId" SG_ 2565533514 PgnRqst_4A_EF 100065;
BA_ "CI_SigName" SG_ 2565533514 PgnRqst_4A_EF "Parameter Group Number (RQST)";
BA_ "SPN" SG_ 2565533514 PgnRqst_4A_EF 2540;
BA_ "SigType" SG_ 2565533514 PgnRqst_4A_EF 6;
BA_ "CI_ParId" SG_ 2565501258 PgnRqst_4A_71 "2540";
BA_ "CI_SigId" SG_ 2565501258 PgnRqst_4A_71 100067;
BA_ "CI_SigName" SG_ 2565501258 PgnRqst_4A_71 "Parameter Group Number (RQST)";
BA_ "SPN" SG_ 2565501258 PgnRqst_4A_71 2540;
BA_ "SigType" SG_ 2565501258 PgnRqst_4A_71 6;
BA_ "CI_ParId" SG_ 2565478730 PgnRqst_4A_19 "2540";
BA_ "CI_SigId" SG_ 2565478730 PgnRqst_4A_19 100069;
BA_ "CI_SigName" SG_ 2565478730 PgnRqst_4A_19 "Parameter Group Number (RQST)";
BA_ "SPN" SG_ 2565478730 PgnRqst_4A_19 2540;
BA_ "SigType" SG_ 2565478730 PgnRqst_4A_19 6;
BA_ "CI_ParId" SG_ 2565537610 PgnRqst_4A_FF "2540";
BA_ "CI_SigId" SG_ 2565537610 PgnRqst_4A_FF 100071;
BA_ "CI_SigName" SG_ 2565537610 PgnRqst_4A_FF "Parameter Group Number (RQST)";
BA_ "SPN" SG_ 2565537610 PgnRqst_4A_FF 2540;
BA_ "SigType" SG_ 2565537610 PgnRqst_4A_FF 6;
VAL_ 2566858309 VehStsOnDrivMode 1 "Recovery_ChargeState" 2 "ECO" 3 "POWER" ;
VAL_ 2566858309 ChgIncident_OvernightModeFullEle 0 "OFF" 1 "ON" ;
VAL_ 2566858309 ChgIncident_InServOpportunityChg 0 "OFF" 1 "ON" ;
VAL_ 2566858309 LowPwrSupplyLevFullElec 0 "OFF" 1 "ON" ;
VAL_ 2566858309 CanPwr3FaultFullElec 0 "OFF" 1 "ON" ;
VAL_ 2566858309 HeatOnFullElec 0 "OFF" 1 "ON" ;
VAL_ 2566870597 VehMode 0 "Standby" 1 "Drive" 2 "Overnight Charging" 3 "Opportunity Charging" 4 "Reserved" 5 "Reserved" 6 "Reserved" 7 "Not Available" ;
VAL_ 2566870597 HeatLiquidLowLev 0 "OFF" 1 "ON" ;
VAL_ 2566870597 HeatFuelLowLev 0 "OFF" 1 "ON" ;
VAL_ 2566870597 HeatSysHighTempFault 0 "OFF" 1 "ON" ;
VAL_ 2566870597 ParkBrkSwFullyApplied 0 "OFF" 1 "ON" ;
VAL_ 2566870597 FaeSts 0 "OFF" 1 "ON" 2 "ERROR" ;
VAL_ 2566870597 FipoSts 0 "OFF" 1 "ON" 2 "ERROR" ;
VAL_ 2566870597 EmerBtnSts 0 "Not activated" 1 "Activated" ;
VAL_ 2566870597 Door1EmerInh 0 "Not activated" 1 "Activated" ;
VAL_ 2566870597 Door2EmerInh 0 "Not activated" 1 "Activated" ;
VAL_ 2566870597 Door3EmerInh 0 "Not activated" 1 "Activated" ;
VAL_ 2566870597 Door4EmerInh 0 "Not activated" 1 "Activated" ;
VAL_ 2566870597 Door1ActvInEmerMode 0 "Not activated" 1 "Activated" ;
VAL_ 2566870597 Door2ActvInEmerMode 0 "Not activated" 1 "Activated" ;
VAL_ 2566870597 Door3ActvInEmerMode 0 "Not activated" 1 "Activated" ;
VAL_ 2566870597 Door4ActvInEmerMode 0 "Not activated" 1 "Activated" ;
VAL_ 2566870597 AirDryerSts 0 "OFF" 1 "ON" ;
VAL_ 2566870597 OverheatingComprElec 0 "OFF" 1 "ON" ;
VAL_ 2566854469 NoBat1Recharge 0 "OFF" 1 "ON" ;
VAL_ 2566854469 NoBat2Recharge 0 "OFF" 1 "ON" ;
VAL_ 2566854469 NoBat3Recharge 0 "OFF" 1 "ON" ;
VAL_ 2566854469 _3RdAxlePrsLow 0 "OFF" 1 "ON" ;
VAL_ 2566854469 _3RdAxleOilLevLow 0 "OFF" 1 "ON" ;
VAL_ 2566854469 _3RdAxleOvl 0 "OFF" 1 "ON" ;
VAL_ 2566854469 PropellerShaftOverspeedAlert 0 "OFF" 1 "ON" ;
VAL_ 2566854469 OilMaintenanceAlert 0 "OFF" 1 "MaintenanceNeeded" 2 "MaintenanceDelayExceeded" 3 "NotAvailable" ;
VAL_ 2566854469 OilMaintenanceReset 0 "NoReset" 1 "ResetPerformed" 2 "Reserved" 3 "NotAvailable" ;
VAL_ 2566906905 AcComprInvActvReq 0 "no request" 1 "request a/c compressor on" 3 "not available." ;
VAL_ 2566906905 CirculationSts 0 "not circulating" 1 "circulating" 2 "error" 3 "not available." ;
VAL_ 2566906905 ThermHtrSts 0 "not active" 1 "active" 2 "error" 3 "not available" ;
VAL_ 2566906905 ElHtrSts 0 "not active" 1 "active" 2 "error" 3 "not available" ;
VAL_ 2566906905 StartStopInhibMildHybrid 1 "SS_Enabled" 3 "SS_Blocked" ;
VAL_ 2566906905 ElHtrOverheating 0 "OK_AlarmNotActive" 1 "Alarm active" 2 "Not used" 3 "Not available" ;
VAL_ 2566906905 ElHtrHvRelayDamaged 0 "OK_AlarmNotActive" 1 "Alarm active" 2 "Not used" 3 "Not available" ;
VAL_ 2566906905 ElHtrOverheatingWarn 0 "OK_AlarmNotActive" 1 "Alarm active" 2 "Not used" 3 "Not available" ;
VAL_ 2566846467 TransmOilTemp1 65024 "Error" 65535 "Not_Available" ;
VAL_ 2566749463 TtBlkId 0 "Block ID0" 1 "Block ID1" 2 "Block ID2" 3 "Block ID3" 4 "Block ID4" 5 "Reserved" 6 "Reserved" 7 "Not Available" ;
VAL_ 2566749463 CoolAc 0 "Off" 1 "Cond. Red" 2 "Cond. Yellow" 3 "Cond. Info" 7 "Not Available" ;
VAL_ 2566749463 HighBeamMainBeam 0 "Off" 1 "Cond. Red" 2 "Cond. Yellow" 3 "Cond. Info" 7 "Not Available" ;
VAL_ 2566749463 LowBeamDipBeam 0 "Off" 1 "Cond. Red" 2 "Cond. Yellow" 3 "Cond. Info" 7 "Not Available" ;
VAL_ 2566749463 TurnSigs 0 "Off" 1 "Cond. Red" 2 "Cond. Yellow" 3 "Cond. Info" 7 "Not Available" ;
VAL_ 2566749463 HazardWarn 0 "Off" 1 "Cond. Red" 2 "Cond. Yellow" 3 "Cond. Info" 7 "Not Available" ;
VAL_ 2566749463 ProvDisOrHandiPers 0 "Off" 1 "Cond. Red" 2 "Cond. Yellow" 3 "Cond. Info" 7 "Not Available" ;
VAL_ 2566749463 ParkBrk 0 "Off" 1 "Cond. Red" 2 "Cond. Yellow" 3 "Cond. Info" 7 "Not Available" ;
VAL_ 2566749463 BrkFail_BrkSysMalf 0 "Off" 1 "Cond. Red" 2 "Cond. Yellow" 3 "Cond. Info" 7 "Not Available" ;
VAL_ 2566749463 HatchOpen 0 "Off" 1 "Cond. Red" 2 "Cond. Yellow" 3 "Cond. Info" 7 "Not Available" ;
VAL_ 2566749463 FuelLev 0 "Off" 1 "Cond. Red" 2 "Cond. Yellow" 3 "Cond. Info" 7 "Not Available" ;
VAL_ 2566749463 EngCoolTemp_18FD7D17 0 "Off" 1 "Cond. Red" 2 "Cond. Yellow" 3 "Cond. Info" 7 "Not Available" ;
VAL_ 2566749463 BatChgCond 0 "Off" 1 "Cond. Red" 2 "Cond. Yellow" 3 "Cond. Info" 7 "Not Available" ;
VAL_ 2566749463 EngOil 0 "Off" 1 "Cond. Red" 2 "Cond. Yellow" 3 "Cond. Info" 7 "Not Available" ;
VAL_ 2566749463 PosLightSideLight 0 "Off" 1 "Cond. Red" 2 "Cond. Yellow" 3 "Cond. Info" 7 "Not Available" ;
VAL_ 2566749463 FrontFogLight 0 "Off" 1 "Cond. Red" 2 "Cond. Yellow" 3 "Cond. Info" 7 "Not Available" ;
VAL_ 2566749463 RearFogLight 0 "Off" 1 "Cond. Red" 2 "Cond. Yellow" 3 "Cond. Info" 7 "Not Available" ;
VAL_ 2566749463 ParkHeat 0 "Off" 1 "Cond. Red" 2 "Cond. Yellow" 3 "Cond. Info" 7 "Not Available" ;
VAL_ 2566749463 Eng_Mil 0 "Off" 1 "Cond. Red" 2 "Cond. Yellow" 3 "Cond. Info" 7 "Not Available" ;
VAL_ 2566749463 ServCallForMaint 0 "Off" 1 "Cond. Red" 2 "Cond. Yellow" 3 "Cond. Info" 7 "Not Available" ;
VAL_ 2566749463 TransmFluidTemp 0 "Off" 1 "Cond. Red" 2 "Cond. Yellow" 3 "Cond. Info" 7 "Not Available" ;
VAL_ 2566749463 TransmFail_Malf 0 "Off" 1 "Cond. Red" 2 "Cond. Yellow" 3 "Cond. Info" 7 "Not Available" ;
VAL_ 2566749463 AntiLckBrkSysFail 0 "Off" 1 "Cond. Red" 2 "Cond. Yellow" 3 "Cond. Info" 7 "Not Available" ;
VAL_ 2566749463 WornBrkLin 0 "Off" 1 "Cond. Red" 2 "Cond. Yellow" 3 "Cond. Info" 7 "Not Available" ;
VAL_ 2566749463 Windsh_WindshWasherFluid 0 "Off" 1 "Cond. Red" 2 "Cond. Yellow" 3 "Cond. Info" 7 "Not Available" ;
VAL_ 2566749463 TireFail_Malf 0 "Off" 1 "Cond. Red" 2 "Cond. Yellow" 3 "Cond. Info" 7 "Not Available" ;
VAL_ 2566749463 Malf_GenFail 0 "Off" 1 "Cond. Red" 2 "Cond. Yellow" 3 "Cond. Info" 7 "Not Available" ;
VAL_ 2566749463 EngOilTemp 0 "Off" 1 "Cond. Red" 2 "Cond. Yellow" 3 "Cond. Info" 7 "Not Available" ;
VAL_ 2566749463 EngOilLev 0 "Off" 1 "Cond. Red" 2 "Cond. Yellow" 3 "Cond. Info" 7 "Not Available" ;
VAL_ 2566749463 EngCoolLev 0 "Off" 1 "Cond. Red" 2 "Cond. Yellow" 3 "Cond. Info" 7 "Not Available" ;
VAL_ 2566749463 SteerFluidLev 0 "Off" 1 "Cond. Red" 2 "Cond. Yellow" 3 "Cond. Info" 7 "Not Available" ;
VAL_ 2566749463 SteerFail 0 "Off" 1 "Cond. Red" 2 "Cond. Yellow" 3 "Cond. Info" 7 "Not Available" ;
VAL_ 2566749463 HtCtrl 0 "Off" 1 "Cond. Red" 2 "Cond. Yellow" 3 "Cond. Info" 7 "Not Available" ;
VAL_ 2566749463 Ret 0 "Off" 1 "Cond. Red" 2 "Cond. Yellow" 3 "Cond. Info" 7 "Not Available" ;
VAL_ 2566749463 EngEmisSysFailMil 0 "Off" 1 "Cond. Red" 2 "Cond. Yellow" 3 "Cond. Info" 7 "Not Available" ;
VAL_ 2566749463 EscInd 0 "Off" 1 "Cond. Red" 2 "Cond. Yellow" 3 "Cond. Info" 7 "Not Available" ;
VAL_ 2566749463 BrkLight 0 "Off" 1 "Cond. Red" 2 "Cond. Yellow" 3 "Cond. Info" 7 "Not Available" ;
VAL_ 2566749463 Artic 0 "Off" 1 "Cond. Red" 2 "Cond. Yellow" 3 "Cond. Info" 7 "Not Available" ;
VAL_ 2566749463 StopReq 0 "Off" 1 "Cond. Red" 2 "Cond. Yellow" 3 "Cond. Info" 7 "Not Available" ;
VAL_ 2566749463 PramReq 0 "Off" 1 "Cond. Red" 2 "Cond. Yellow" 3 "Cond. Info" 7 "Not Available" ;
VAL_ 2566749463 BusStopBrk 0 "Off" 1 "Cond. Red" 2 "Cond. Yellow" 3 "Cond. Info" 7 "Not Available" ;
VAL_ 2566749463 AdblueLev 0 "Off" 1 "Cond. Red" 2 "Cond. Yellow" 3 "Cond. Info" 7 "Not Available" ;
VAL_ 2566749463 Raising 0 "Off" 1 "Cond. Red" 2 "Cond. Yellow" 3 "Cond. Info" 7 "Not Available" ;
VAL_ 2566749463 Low 0 "Off" 1 "Cond. Red" 2 "Cond. Yellow" 3 "Cond. Info" 7 "Not Available" ;
VAL_ 2566749463 Kneel 0 "Off" 1 "Cond. Red" 2 "Cond. Yellow" 3 "Cond. Info" 7 "Not Available" ;
VAL_ 2566749463 EngCompTemp 0 "Off" 1 "Cond. Red" 2 "Cond. Yellow" 3 "Cond. Info" 7 "Not Available" ;
VAL_ 2566749463 AuxAirPrs 0 "Off" 1 "Cond. Red" 2 "Cond. Yellow" 3 "Cond. Info" 7 "Not Available" ;
VAL_ 2566749463 AirFiltClog 0 "Off" 1 "Cond. Red" 2 "Cond. Yellow" 3 "Cond. Info" 7 "Not Available" ;
VAL_ 2566749463 FuelFiltDiffPrs 0 "Off" 1 "Cond. Red" 2 "Cond. Yellow" 3 "Cond. Info" 7 "Not Available" ;
VAL_ 2566749463 SeatBelt 0 "Off" 1 "Cond. Red" 2 "Cond. Yellow" 3 "Cond. Info" 7 "Not Available" ;
VAL_ 2566749463 Ebs 0 "Off" 1 "Cond. Red" 2 "Cond. Yellow" 3 "Cond. Info" 7 "Not Available" ;
VAL_ 2566749463 LaneDepInd 0 "Off" 1 "Cond. Red" 2 "Cond. Yellow" 3 "Cond. Info" 7 "Not Available" ;
VAL_ 2566749463 Aebs 0 "Off" 1 "Cond. Red" 2 "Cond. Yellow" 3 "Cond. Info" 7 "Not Available" ;
VAL_ 2566749463 Acc 0 "Off" 1 "Cond. Red" 2 "Cond. Yellow" 3 "Cond. Info" 7 "Not Available" ;
VAL_ 2566749463 TrailConn 0 "Off" 1 "Cond. Red" 2 "Cond. Yellow" 3 "Cond. Info" 7 "Not Available" ;
VAL_ 2566749463 AbsTrail12 0 "Off" 1 "Cond. Red" 2 "Cond. Yellow" 3 "Cond. Info" 7 "Not Available" ;
VAL_ 2566749463 Airbag 0 "Off" 1 "Cond. Red" 2 "Cond. Yellow" 3 "Cond. Info" 7 "Not Available" ;
VAL_ 2566749463 EbsTrail12 0 "Off" 1 "Cond. Red" 2 "Cond. Yellow" 3 "Cond. Info" 7 "Not Available" ;
VAL_ 2566749463 TcoInd 0 "Off" 1 "Cond. Red" 2 "Cond. Yellow" 3 "Cond. Info" 7 "Not Available" ;
VAL_ 2566749463 EscSwdOff 0 "Off" 1 "Cond. Red" 2 "Cond. Yellow" 3 "Cond. Info" 7 "Not Available" ;
VAL_ 2566749463 LdwSwdOff 0 "Off" 1 "Cond. Red" 2 "Cond. Yellow" 3 "Cond. Info" 7 "Not Available" ;
VAL_ 2566749463 EngEmisFilt 0 "Off" 1 "Cond. Red" 2 "Cond. Yellow" 3 "Cond. Info" 7 "Not Available" ;
VAL_ 2566749463 ElMotFails 0 "Off" 1 "Cond. Red" 2 "Cond. Yellow" 3 "Cond. Info" 7 "Not Available" ;
VAL_ 2566749463 AdblueTamp 0 "Off" 1 "Cond. Red" 2 "Cond. Yellow" 3 "Cond. Info" 7 "Not Available" ;
VAL_ 2566749463 MuxSys 0 "Off" 1 "Cond. Red" 2 "Cond. Yellow" 3 "Cond. Info" 7 "Not Available" ;
VAL_ 2566749463 BatPak 0 "Off" 1 "Cond. Red" 2 "Cond. Yellow" 3 "Cond. Info" 4 "Reserved" 5 "Reserved" 6 "Reserved" 7 "Not Available" ;
VAL_ 2566749463 highVsysCaution 0 "Off" 1 "Cond. Red" 2 "Cond. Yellow" 3 "Cond. Info" 4 "Reserved" 5 "Reserved" 6 "Reserved" 7 "Not Available" ;
VAL_ 2566749463 BatPakTemp 0 "Off" 1 "Cond. Red" 2 "Cond. Yellow" 3 "Cond. Info" 4 "Reserved" 5 "Reserved" 6 "Reserved" 7 "Not Available" ;
VAL_ 2566749463 LimPerfElMot 0 "Off" 1 "Cond. Red" 2 "Cond. Yellow" 3 "Cond. Info" 4 "Reserved" 5 "Reserved" 6 "Reserved" 7 "Not Available" ;
VAL_ 2566749463 BatPakCool 0 "Off" 1 "Cond. Red" 2 "Cond. Yellow" 3 "Cond. Info" 4 "Reserved" 5 "Reserved" 6 "Reserved" 7 "Not Available" ;
VAL_ 2566884426 DeferredDataReq 0 "NoRequest" 1 "RequestIsActive" ;
VAL_ 2566884426 EcuIdReq 0 "NoRequest" 1 "RequestIsActive" ;
VAL_ 2566884426 CompIdReq 0 "NoRequest" 1 "RequestIsActive" ;
VAL_ 2566884426 SwIdReq 0 "NoRequest" 1 "RequestIsActive" ;
VAL_ 2566884426 AllTheDataRemoval 0 "NoRequest" 1 "RequestIsActive" ;
VAL_ 2566877568 FCU2_8_H2LeakLamp 0 "Leak" 1 "Leak" 2 "Leak" ;
VAL_ 2566877568 FCU2_HighvoltageInterlockReactRe 0 "Reaction Request" ;
VAL_ 2566877568 FCU2_H2TankValveEmergencyClose 0 "Close" ;
VAL_ 2566877568 FuelCellSwitchONOFFinputVCU 0 ": OFF  0x1 : ON" ;
VAL_ 2566877568 FCU2_5_FuelcellStartup 0 "start-up^0x2:start-up complete^0" ;
VAL_ 2566877568 FCU2_5_FuelcellLoadPermmit 0 "Permissive^0x1:Permissive" ;
VAL_ 2566877568 FCU2_5_FuelcellShutdown 0 "shut-down^0x2:shut-down complete" ;
VAL_ 2566877568 FCU2_7_FuelcellStopImpossible 0 "Stop impossible^0x2~0x3:Reserved" ;
VAL_ 2566877568 FCU2_7_FuelcellStopState 0 "Stop release completed)^0x1:duri" ;
VAL_ 2566877568 VCU_HighvoltageFaultEmergencyShu 0 "stop" ;
VAL_ 2566877568 VCU_TankCloseEmergencyShutdownRe 0 "stop" ;
VAL_ 2566877568 Fcactivationdeactivationstatusfo 0 "no activation, 01 FC activation " ;
VAL_ 2566877568 H2ConctValExc3Pc_AwlR134 0 ": OK  1 H2-Leakage of more than " ;
VAL_ 2566877568 H2ConctValExc4Pc_RsllR134 0 ": OK  1 H2-Leakage of more than " ;
VAL_ 2566877568 H2sensor1leakagestatus 0 "No H2 leakage detected / 0x1 H2 " ;
VAL_ 2566877568 H2sensor2leakagestatus 0 "No H2 leakage detected / 0x1 H2 " ;
VAL_ 2566877568 H2sensor3leakagestatus 0 "No H2 leakage detected / 0x1 H2 " ;
VAL_ 2566877568 H2sensor4leakagestatus 0 "No H2 leakage detected / 0x1 H2 " ;
VAL_ 2566877568 FuelCellstatusfromSupervisorside 0 "Stop (0xB)" ;
VAL_ 2566877568 H2Circuitstatus 1 ": H2 circuit is close safely wit" 2 ": not used" 3 ": H2 circuit is close with criti" 4 ": H2 circuit is open with critic" ;
VAL_ 2566877568 Limphomemodeoverridemodestatus 0 "No override / Ox1 Override mode " ;
VAL_ 2566877568 H2CircuitFautRSL 0 "No picto / 0x1 Red stop Lamp H2 " ;
VAL_ 2566877568 H2circuitFaultAWL 0 "No picto / 0x1 Amber H2 circuit " ;
VAL_ 2566877568 HVDCLinkStatus 0 "DC link Faulty / 0x1 Dc Linf OK" ;
VAL_ 2566877568 FCModerequestbytheSupervisor 0 "Stop Command due to HV fault det" ;
VAL_ 2566877568 NumberoftanksopenforH2Readytopro 0 ": no tanks open / 1 : 1 tank ope" ;
VAL_ 2566877568 Fillingauthorizationduetosafetyr 0 ": filling is allowed  0x1 fillin" ;
VAL_ 2566803211 VdcInfoSig 0 "Off" 1 "On" 2 "Reserved" 3 "Don’t Care / Take no action" ;
VAL_ 2566803211 VdcFullyOp 0 "Not fully operational" 1 "Fully operational" 2 "Reserved" 3 "Don’t Care / Take no action" ;
VAL_ 2566842927 Axle_Location 0 "Axle 1" 1 "Axle 2" 2 "Axle 3" 3 "Axle 4" 4 "Axle 5" ;
VAL_ 2566842944 Axle_Location_18FEEA40 0 "Axle 1" 1 "Axle 2" 2 "Axle 3" 3 "Axle 4" 4 "Axle 5" ;
VAL_ 2566848256 WaterInFuelInd1 0 "No" 1 "Yes" 2 "Error" 3 "Not Available" ;
